VERSION ""

NS_ :

BS_:

BU_:

BO_ 2566856960 ECU_EDC2BC: 8 Vector__XXX
 SG_ FF21_ForcedRegenerationStatus : 28|2@1+ (1,0) [0|3] "" Vector__XXX
 SG_ FF21_DPFSootLevel : 56|8@1+ (1,0) [0|255] "" Vector__XXX
 SG_ FF21_EBCoperationalStatus : 52|4@1+ (1,0) [0|15] "" Vector__XXX
 SG_ FF21_EngineDegradationLevel : 48|4@1+ (1,0) [0|15] "" Vector__XXX
 SG_ FF21_EngineOilTempHigh : 46|2@1+ (1,0) [0|3] "" Vector__XXX
 SG_ FF21_FuelFilterHeaterStatus : 44|2@1+ (1,0) [0|3] "" Vector__XXX
 SG_ FF21_WaterInFuelDetection : 42|2@1+ (1,0) [0|3] "" Vector__XXX
 SG_ FF21_EngineOilPressureLow : 40|2@1+ (1,0) [0|3] "" Vector__XXX
 SG_ FF21_StopButtonSatus : 35|2@1+ (1,0) [0|3] "" Vector__XXX
 SG_ FF21_RegenerationLampStatus : 32|3@1+ (1,0) [0|7] "" Vector__XXX
 SG_ FF21_HydrauPumpActiveRequest : 26|2@1+ (1,0) [0|3] "" Vector__XXX
 SG_ FF21_MILStatus : 24|2@1+ (1,0) [0|3] "" Vector__XXX
 SG_ FF21_EngineOverSpeed : 10|2@1+ (1,0) [0|3] "" Vector__XXX
 SG_ FF21_VehicleSpeedLimitLampStatus : 8|2@1+ (1,0) [0|3] "" Vector__XXX
 SG_ FF21_DiagnosticLampStatus : 6|2@1+ (1,0) [0|3] "" Vector__XXX
 SG_ FF21_FuelBlockStatusByTheI : 4|2@1+ (1,0) [0|3] "" Vector__XXX
 SG_ FF21_ColdStartHeaterStatus : 0|4@1+ (1,0) [0|15] "" Vector__XXX

BO_ 2566763581 ECU_AT1IG2_SA3D: 8 Vector__XXX
 SG_ Aftrtrtmnt1ExhaustTemperature1 : 0|16@1+ (0.03125,-273) [-273|1734.96875] "deg C" Vector__XXX
 SG_ Aftrtrtmnt1DslPFIntkTemperature : 16|16@1+ (0.03125,-273) [-273|1734.96875] "deg C" Vector__XXX
 SG_ Aftrtrtmnt1ExhstTemp1PrelimFMI : 32|5@1+ (1,0) [0|31] "" Vector__XXX
 SG_ Aft1DslPFIntkTempPrelimFMI : 40|5@1+ (1,0) [0|31] "" Vector__XXX

BO_ 2566719744 ECU_HRLFC: 8 Vector__XXX
 SG_ EngineTripFuel : 0|32@1+ (0.001,0) [0|4211081.215] "l" Vector__XXX
 SG_ EngineTotalFuelUsed : 32|32@1+ (0.001,0) [0|4211081.215] "l" Vector__XXX

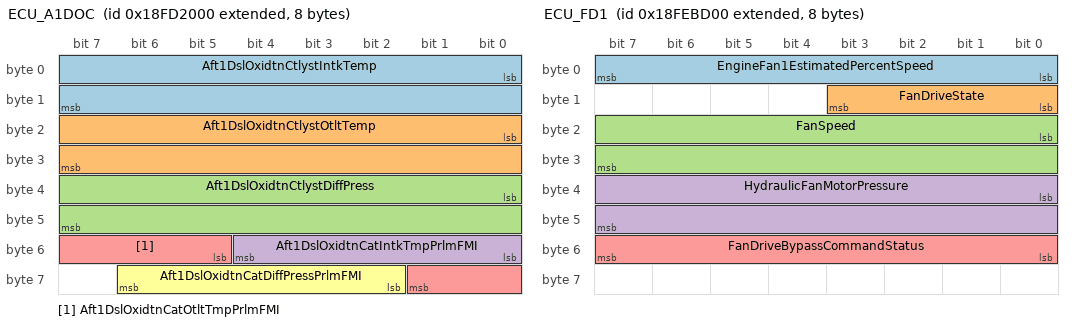
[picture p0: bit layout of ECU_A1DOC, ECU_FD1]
BO_ 2566725632 ECU_A1DOC: 8 Vector__XXX
 SG_ Aft1DslOxidtnCtlystIntkTemp : 0|16@1+ (0.03125,-273) [-273|1734.96875] "deg C" Vector__XXX
 SG_ Aft1DslOxidtnCtlystOtltTemp : 16|16@1+ (0.03125,-273) [-273|1734.96875] "deg C" Vector__XXX
 SG_ Aft1DslOxidtnCtlystDiffPress : 32|16@1+ (0.1,0) [0|6425.5] "kPa" Vector__XXX
 SG_ Aft1DslOxidtnCatIntkTmpPrlmFMI : 48|5@1+ (1,0) [0|31] "" Vector__XXX
 SG_ Aft1DslOxidtnCatOtltTmpPrlmFMI : 53|5@1+ (1,0) [0|31] "" Vector__XXX
 SG_ Aft1DslOxidtnCatDiffPressPrlmFMI : 58|5@1+ (1,0) [0|31] "" Vector__XXX

BO_ 2566749184 ECU_DPFC1: 8 Vector__XXX
 SG_ DieselParticulateFilterLampCmd : 0|3@1+ (1,0) [0|7] "" Vector__XXX
 SG_ AftrtrtmntDslPFPassiveRegenStat : 8|2@1+ (1,0) [0|3] "" Vector__XXX
 SG_ AftrtrtmntDslPFActvRegenStatus : 10|2@1+ (1,0) [0|3] "" Vector__XXX
 SG_ AftrtrtmntDslPFStatus : 12|3@1+ (1,0) [0|7] "" Vector__XXX
 SG_ DslPFActvRegenInhbtdStatus : 16|2@1+ (1,0) [0|3] "" Vector__XXX
 SG_ DslPFActvRegenInhbtdDTInhbtSw : 18|2@1+ (1,0) [0|3] "" Vector__XXX
 SG_ DslPFActRegenInhbtdDTCltchDiseng : 20|2@1+ (1,0) [0|3] "" Vector__XXX
 SG_ DslPFActRegenInhbtdDTSrvcBrkActv : 22|2@1+ (1,0) [0|3] "" Vector__XXX
 SG_ DslPFActvRegenInhbtdDTPTOActv : 24|2@1+ (1,0) [0|3] "" Vector__XXX
 SG_ DPFActRegenInhbtdDTAcclPdlOffIdl : 26|2@1+ (1,0) [0|3] "" Vector__XXX
 SG_ DslPFActvRegenInhbtdDTOutOfNtrl : 28|2@1+ (1,0) [0|3] "" Vector__XXX
 SG_ DPFActRegInhDTVhclSpdAbvAllwdSpd : 30|2@1+ (1,0) [0|3] "" Vector__XXX
 SG_ DPFActRegenInhbtdDTPrkBrkNotSet : 32|2@1+ (1,0) [0|3] "" Vector__XXX
 SG_ DPFActRegenInhbtdDTLowExhstTemp : 34|2@1+ (1,0) [0|3] "" Vector__XXX
 SG_ DslPFActRegenInhbtdDTSysFaultAct : 36|2@1+ (1,0) [0|3] "" Vector__XXX
 SG_ DslPFActvRegenInhbtdDTSysTimeout : 38|2@1+ (1,0) [0|3] "" Vector__XXX
 SG_ DPFActRegenInhbtdDTTmprySysLckt : 40|2@1+ (1,0) [0|3] "" Vector__XXX
 SG_ DPFActRegenInhbtdDTPrmntSysLckt : 42|2@1+ (1,0) [0|3] "" Vector__XXX
 SG_ DPFActRegInhbtdDTEngNotWarmedUp : 44|2@1+ (1,0) [0|3] "" Vector__XXX
 SG_ DPFActRegInhDTVhclSpdBlwAllwdSpd : 46|2@1+ (1,0) [0|3] "" Vector__XXX
 SG_ DslPFAutoActvRegenInitConf : 48|2@1+ (1,0) [0|3] "" Vector__XXX
 SG_ ExhstSystemHghTemperatureLampCmd : 50|3@1+ (1,0) [0|7] "" Vector__XXX
 SG_ DslPFActvRegenForcedStatus : 53|3@1+ (1,0) [0|7] "" Vector__XXX
 SG_ HydrocarbonDoserPurgingEnable : 56|2@1+ (1,0) [0|3] "" Vector__XXX
 SG_ DPFActRegenInhbtdDTLowExhstPress : 58|2@1+ (1,0) [0|3] "" Vector__XXX
 SG_ Aft1DPFConditionsNotMetForActReg : 60|2@1+ (1,0) [0|3] "" Vector__XXX

BO_ 2566831360 ECU_FD1: 8 Vector__XXX
 SG_ EngineFan1EstimatedPercentSpeed : 0|8@1+ (0.4,0) [0|100] "%" Vector__XXX
 SG_ FanDriveState : 8|4@1+ (1,0) [0|15] "" Vector__XXX
 SG_ FanSpeed : 16|16@1+ (0.125,0) [0|8031.875] "rpm" Vector__XXX
 SG_ HydraulicFanMotorPressure : 32|16@1+ (0.5,0) [0|32127.5] "kPa" Vector__XXX
 SG_ FanDriveBypassCommandStatus : 48|8@1+ (0.4,0) [0|100] "%" Vector__XXX

BO_ 2566845696 ECU_AMB: 8 Vector__XXX
 SG_ BarometricPressure : 0|8@1+ (0.5,0) [0|125] "kPa" Vector__XXX
 SG_ CabInteriorTemperature : 8|16@1+ (0.03125,-273) [-273|1734.96875] "deg C" Vector__XXX
 SG_ AmbientAirTemperature : 24|16@1+ (0.03125,-273) [-273|1734.96875] "deg C" Vector__XXX
 SG_ EngineIntakeAirTemperature : 40|8@1+ (1,-40) [-40|210] "deg C" Vector__XXX
 SG_ RoadSurfaceTemperature : 48|16@1+ (0.03125,-273) [-273|1734.96875] "deg C" Vector__XXX

BO_ 2566846208 ECU_VEP1: 8 Vector__XXX
 SG_ NetBatteryCurrent : 0|8@1+ (1,-125) [-125|125] "A" Vector__XXX
 SG_ AlternatorCurrent : 8|8@1+ (1,0) [0|250] "A" Vector__XXX
 SG_ ChargingSystemPotential : 16|16@1+ (0.05,0) [0|3212.75] "V" Vector__XXX
 SG_ BatteryPotentialPowerInput1 : 32|16@1+ (0.05,0) [0|3212.75] "V" Vector__XXX
 SG_ KeyswitchBatteryPotential : 48|16@1+ (0.05,0) [0|3212.75] "V" Vector__XXX

BO_ 2566875929 AIRCON_ACRM: 8 Vector__XXX
 SG_ FF6B_VCU_Compressure_State : 22|2@1+ (1,0) [0|3] "" Vector__XXX
 SG_ FF6B_ACP_PS : 56|8@1+ (16,0) [0|4000] "kPa" Vector__XXX
 SG_ FF6B_CurrentAmbientTemperature_ : 48|8@1+ (1,0) [0|255] "" Vector__XXX
 SG_ FF6B_TemperatureState : 44|4@1+ (1,0) [0|15] "" Vector__XXX
 SG_ FF6B_WindDirectRearIndicState : 10|2@1+ (1,0) [0|3] "" Vector__XXX
 SG_ FF6B_WindDirectFrontIndicState : 8|2@1+ (1,0) [0|3] "" Vector__XXX
 SG_ FF6B_WindDirectFloorIndicState : 12|2@1+ (1,0) [0|3] "" Vector__XXX
 SG_ FF6B_WindDirectDEFIndicState : 14|2@1+ (1,0) [0|3] "" Vector__XXX
 SG_ FF6B_TempSettingValueOverState : 18|2@1+ (1,0) [0|3] "" Vector__XXX
 SG_ FF6B_TempSettingValueBelowState : 20|2@1+ (1,0) [0|3] "" Vector__XXX
 SG_ FF6B_OuttakeIntakeModeSelect : 4|2@1+ (1,0) [0|3] "" Vector__XXX
 SG_ FF6B_ManualAutoModeState : 0|2@1+ (1,0) [0|3] "" Vector__XXX
 SG_ FF6B_HVACPowerState : 16|2@1+ (1,0) [0|3] "" Vector__XXX
 SG_ FF6B_DEFModeState : 6|2@1+ (1,0) [0|3] "" Vector__XXX
 SG_ FF6B_CurrentTemperatureSetting : 24|5@1+ (1,0) [0|31] "" Vector__XXX
 SG_ FF6B_CurrentBlowerSpeed : 40|4@1+ (1,0) [0|15] "" Vector__XXX
 SG_ FF6B_CurrentAmbientTemperature : 32|8@1+ (1,0) [0|255] "" Vector__XXX
 SG_ FF6B_ACModeState : 2|2@1+ (1,0) [0|3] "" Vector__XXX

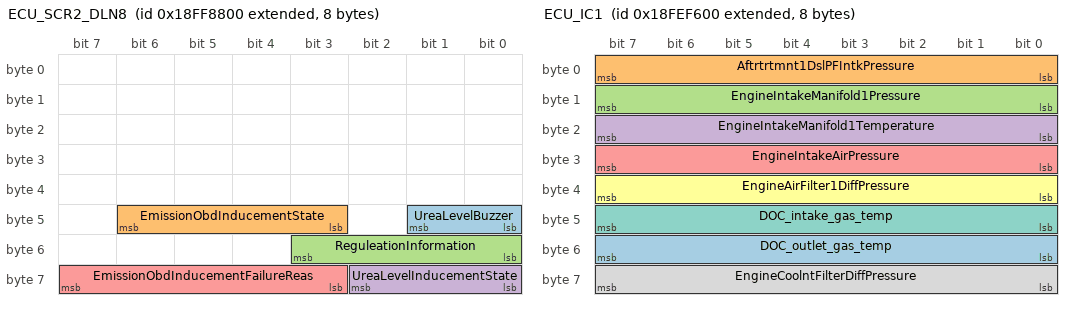
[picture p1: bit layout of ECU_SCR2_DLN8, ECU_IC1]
BO_ 2566883328 ECU_SCR2_DLN8: 8 Vector__XXX
 SG_ UreaLevelBuzzer : 40|2@1+ (1,0) [0|3] "bit" Vector__XXX
 SG_ EmissionObdInducementState : 43|4@1+ (1,0) [0|15] "bit" Vector__XXX
 SG_ ReguleationInformation : 48|4@1+ (1,0) [0|15] "bit" Vector__XXX
 SG_ UreaLevelInducementState : 56|3@1+ (1,0) [0|7] "bit" Vector__XXX
 SG_ EmissionObdInducementFailureReas : 59|5@1+ (1,0) [0|31] "bit" Vector__XXX

BO_ 2566845952 ECU_IC1: 8 Vector__XXX
 SG_ DOC_outlet_gas_temp : 48|8@1+ (0.03125,-273) [-273|-265.03125] "deg C" Vector__XXX
 SG_ Aftrtrtmnt1DslPFIntkPressure : 0|8@1+ (0.5,0) [0|125] "kPa" Vector__XXX
 SG_ EngineIntakeManifold1Pressure : 8|8@1+ (2,0) [0|500] "kPa" Vector__XXX
 SG_ EngineIntakeManifold1Temperature : 16|8@1+ (1,-40) [-40|210] "deg C" Vector__XXX
 SG_ EngineIntakeAirPressure : 24|8@1+ (2,0) [0|500] "kPa" Vector__XXX
 SG_ EngineAirFilter1DiffPressure : 32|8@1+ (0.05,0) [0|12.5] "kPa" Vector__XXX
 SG_ DOC_intake_gas_temp : 40|8@1+ (0.03125,-273) [-273|-265.03125] "deg C" Vector__XXX
 SG_ EngineCoolntFilterDiffPressure : 56|8@1+ (0.5,0) [0|125] "kPa" Vector__XXX

BO_ 2348875776 ECU_TC1: 8 Vector__XXX
 SG_ TransmissionGearShiftInhbtRq : 0|2@1+ (1,0) [0|3] "" Vector__XXX
 SG_ TrnsmTrqCnvLockupDisableRq : 2|2@1+ (1,0) [0|3] "" Vector__XXX
 SG_ DisengageDrivelineRequest : 4|2@1+ (1,0) [0|3] "" Vector__XXX
 SG_ TrnsmReverseGearShftInhbtRq : 6|2@1+ (1,0) [0|3] "" Vector__XXX
 SG_ RequestedPercentClutchSlip : 8|8@1+ (0.4,0) [0|100] "%" Vector__XXX
 SG_ TransmissionRequestedGear : 16|8@1+ (1,-125) [-125|125] "" Vector__XXX
 SG_ DisengiffLockRequestFrontAxl1 : 24|2@1+ (1,0) [0|3] "" Vector__XXX
 SG_ DisengiffLockRequestFrontAxl2 : 26|2@1+ (1,0) [0|3] "" Vector__XXX
 SG_ DisengageDiffLockRequestRearAxl1 : 28|2@1+ (1,0) [0|3] "" Vector__XXX
 SG_ DisengageDiffLockRequestRearAxl2 : 30|2@1+ (1,0) [0|3] "" Vector__XXX
 SG_ DisengageDiffLockRequestCentral : 32|2@1+ (1,0) [0|3] "" Vector__XXX
 SG_ DisengiffLockRequestCentralFront : 34|2@1+ (1,0) [0|3] "" Vector__XXX
 SG_ DisengiffLockRequestCentralRear : 36|2@1+ (1,0) [0|3] "" Vector__XXX
 SG_ TransmissionLoadRedInhbtRequest : 38|2@1+ (1,0) [0|3] "" Vector__XXX
 SG_ TransmissionMode1 : 40|2@1+ (1,0) [0|3] "" Vector__XXX
 SG_ TransmissionMode2 : 42|2@1+ (1,0) [0|3] "" Vector__XXX
 SG_ TransmissionMode3 : 44|2@1+ (1,0) [0|3] "" Vector__XXX
 SG_ TransmissionMode4 : 46|2@1+ (1,0) [0|3] "" Vector__XXX
 SG_ TransmissionRequestedLaunchGear : 50|4@1+ (1,0) [0|15] "" Vector__XXX
 SG_ TrnsmShftSlctorDisplayMdeSw : 54|2@1+ (1,0) [0|3] "" Vector__XXX
 SG_ TransmissionMode5 : 56|2@1+ (1,0) [0|3] "" Vector__XXX
 SG_ TransmissionMode6 : 58|2@1+ (1,0) [0|3] "" Vector__XXX
 SG_ TransmissionMode7 : 60|2@1+ (1,0) [0|3] "" Vector__XXX
 SG_ TransmissionMode8 : 62|2@1+ (1,0) [0|3] "" Vector__XXX

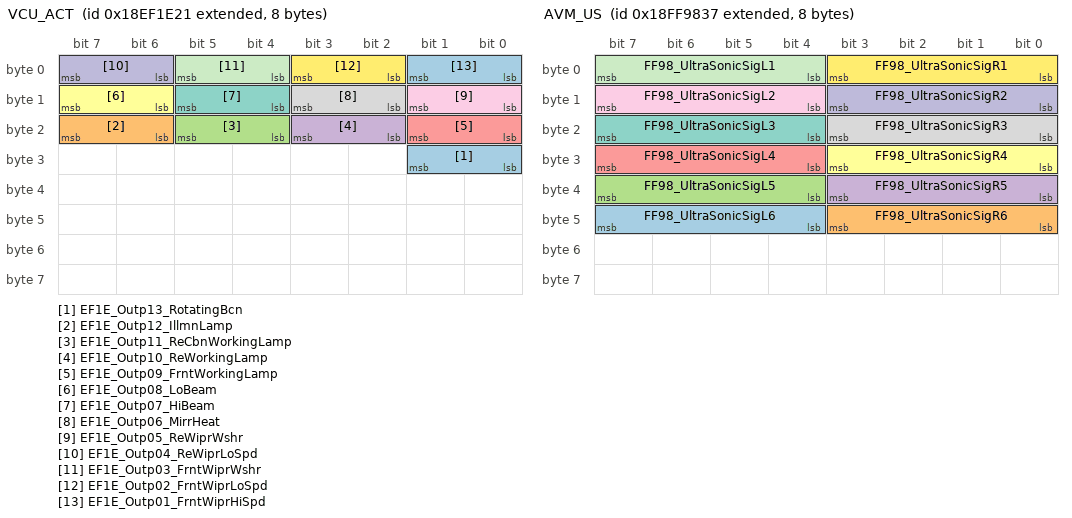
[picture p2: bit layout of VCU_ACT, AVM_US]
BO_ 2565807649 VCU_ACT: 8 Vector__XXX
 SG_ EF1E_Outp13_RotatingBcn : 24|2@1+ (1,0) [0|3] "" Vector__XXX
 SG_ EF1E_Outp12_IllmnLamp : 22|2@1+ (1,0) [0|3] "" Vector__XXX
 SG_ EF1E_Outp11_ReCbnWorkingLamp : 20|2@1+ (1,0) [0|3] "" Vector__XXX
 SG_ EF1E_Outp10_ReWorkingLamp : 18|2@1+ (1,0) [0|3] "" Vector__XXX
 SG_ EF1E_Outp09_FrntWorkingLamp : 16|2@1+ (1,0) [0|3] "" Vector__XXX
 SG_ EF1E_Outp08_LoBeam : 14|2@1+ (1,0) [0|3] "" Vector__XXX
 SG_ EF1E_Outp07_HiBeam : 12|2@1+ (1,0) [0|3] "" Vector__XXX
 SG_ EF1E_Outp06_MirrHeat : 10|2@1+ (1,0) [0|3] "" Vector__XXX
 SG_ EF1E_Outp05_ReWiprWshr : 8|2@1+ (1,0) [0|3] "" Vector__XXX
 SG_ EF1E_Outp04_ReWiprLoSpd : 6|2@1+ (1,0) [0|3] "" Vector__XXX
 SG_ EF1E_Outp03_FrntWiprWshr : 4|2@1+ (1,0) [0|3] "" Vector__XXX
 SG_ EF1E_Outp02_FrntWiprLoSpd : 2|2@1+ (1,0) [0|3] "" Vector__XXX
 SG_ EF1E_Outp01_FrntWiprHiSpd : 0|2@1+ (1,0) [0|3] "" Vector__XXX

BO_ 2566887479 AVM_US: 8 Vector__XXX
 SG_ FF98_UltraSonicSigL6 : 44|4@1+ (1,0) [0|15] "" Vector__XXX
 SG_ FF98_UltraSonicSigR6 : 40|4@1+ (1,0) [0|15] "" Vector__XXX
 SG_ FF98_UltraSonicSigL5 : 36|4@1+ (1,0) [0|15] "" Vector__XXX
 SG_ FF98_UltraSonicSigR5 : 32|4@1+ (1,0) [0|15] "" Vector__XXX
 SG_ FF98_UltraSonicSigL4 : 28|4@1+ (1,0) [0|15] "" Vector__XXX
 SG_ FF98_UltraSonicSigR4 : 24|4@1+ (1,0) [0|15] "" Vector__XXX
 SG_ FF98_UltraSonicSigL3 : 20|4@1+ (1,0) [0|15] "" Vector__XXX
 SG_ FF98_UltraSonicSigR3 : 16|4@1+ (1,0) [0|15] "" Vector__XXX
 SG_ FF98_UltraSonicSigL2 : 12|4@1+ (1,0) [0|15] "" Vector__XXX
 SG_ FF98_UltraSonicSigR2 : 8|4@1+ (1,0) [0|15] "" Vector__XXX
 SG_ FF98_UltraSonicSigL1 : 4|4@1+ (1,0) [0|15] "" Vector__XXX
 SG_ FF98_UltraSonicSigR1 : 0|4@1+ (1,0) [0|15] "" Vector__XXX

BO_ 2566899200 ECU_VGTPosCmd: 8 Vector__XXX
 SG_ FFC6_VGTCommandState : 16|8@1+ (1,0) [0|255] "" Vector__XXX
 SG_ FFC6_VGTnozzle_MSB : 8|8@1+ (1,0) [0|255] "" Vector__XXX
 SG_ FFC6_nozzle_LSB : 0|8@1+ (1,0) [0|255] "" Vector__XXX

BO_ 2566861056 ECU_TFI4CMD: 8 Vector__XXX
 SG_ FF31_Filtertime : 8|8@1+ (1,0) [0|255] "" Vector__XXX
 SG_ FF31_Command : 0|8@1+ (1,0) [0|255] "" Vector__XXX

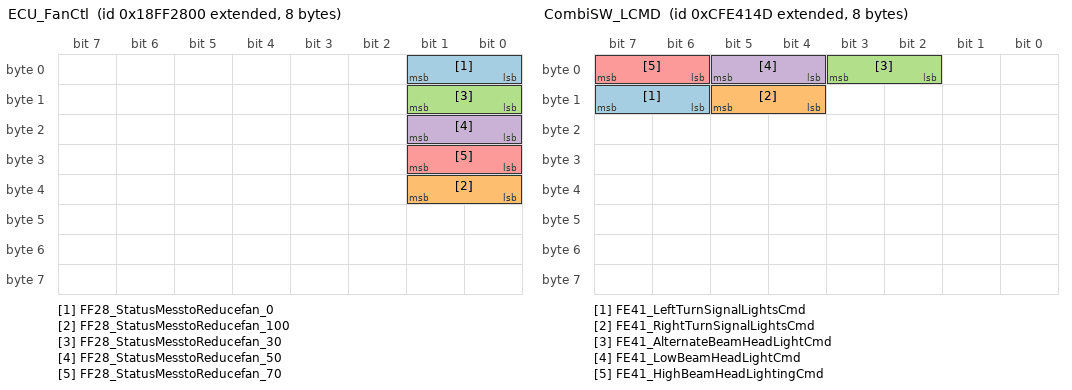
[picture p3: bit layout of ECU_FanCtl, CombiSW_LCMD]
BO_ 2566858752 ECU_FanCtl: 8 Vector__XXX
 SG_ FF28_StatusMesstoReducefan_0 : 0|2@1+ (1,0) [0|3] "" Vector__XXX
 SG_ FF28_StatusMesstoReducefan_100 : 32|2@1+ (1,0) [0|3] "" Vector__XXX
 SG_ FF28_StatusMesstoReducefan_30 : 8|2@1+ (1,0) [0|3] "" Vector__XXX
 SG_ FF28_StatusMesstoReducefan_50 : 16|2@1+ (1,0) [0|3] "" Vector__XXX
 SG_ FF28_StatusMesstoReducefan_70 : 24|2@1+ (1,0) [0|3] "" Vector__XXX

BO_ 2566769997 CombiSW_OWW: 8 Vector__XXX
 SG_ FDCD_WasherSwitch : 45|3@1+ (1,0) [0|7] "" Vector__XXX
 SG_ FDCD_WiperDelayControl : 16|8@1+ (1,0) [0|255] "" Vector__XXX
 SG_ FDCD_WiperSwitch : 4|4@1+ (1,0) [0|15] "" Vector__XXX

BO_ 2365473101 CombiSW_LCMD: 8 Vector__XXX
 SG_ FE41_LeftTurnSignalLightsCmd : 14|2@1+ (1,0) [0|3] "" Vector__XXX
 SG_ FE41_RightTurnSignalLightsCmd : 12|2@1+ (1,0) [0|3] "" Vector__XXX
 SG_ FE41_AlternateBeamHeadLightCmd : 2|2@1+ (1,0) [0|3] "" Vector__XXX
 SG_ FE41_LowBeamHeadLightCmd : 4|2@1+ (1,0) [0|3] "" Vector__XXX
 SG_ FE41_HighBeamHeadLightingCmd : 6|2@1+ (1,0) [0|3] "" Vector__XXX

BO_ 2566904865 VCU_CETI: 10 Vector__XXX
 SG_ FFDC_MissionType : 68|4@1+ (1,0) [0|15] "" Vector__XXX
 SG_ FFDC_JoystickType : 64|4@1+ (1,0) [0|15] "" Vector__XXX
 SG_ FFDC_MCVControlType : 60|4@1+ (1,0) [0|15] "" Vector__XXX
 SG_ FFDC_MCVType : 56|4@1+ (1,0) [0|15] "" Vector__XXX
 SG_ FFDC_PumpControlType : 52|4@1+ (1,0) [0|15] "" Vector__XXX
 SG_ FFDC_PumpType : 48|4@1+ (1,0) [0|15] "" Vector__XXX
 SG_ FFDC_ECUMaker : 44|4@1+ (1,0) [0|15] "" Vector__XXX
 SG_ FFDC_SalesRegion : 72|8@1+ (1,0) [0|255] "" Vector__XXX
 SG_ FFDC_EngineMaker : 40|4@1+ (1,0) [0|15] "" Vector__XXX
 SG_ FFDC_ModelYearVersion : 36|4@1+ (1,0) [0|15] "" Vector__XXX
 SG_ FFDC_MachineType : 32|4@1+ (1,0) [0|15] "" Vector__XXX
 SG_ FFDC_MachineClassification : 16|16@1+ (0.1,0) [0|6502.3] "" Vector__XXX
 SG_ FFDC_MachineGeneration : 8|8@1+ (1,0) [0|255] "" Vector__XXX
 SG_ FFDC_EmissionControl : 0|8@1+ (1,0) [0|255] "" Vector__XXX

BO_ 2566906145 VCU_FLI: 70 Vector__XXX
 SG_ FFE1_FailureLog8_FMI : 411|5@1+ (1,0) [0|31] "" Vector__XXX
 SG_ FFE1_FailureLog9_FMI : 467|5@1+ (1,0) [0|31] "" Vector__XXX
 SG_ FFE1_FailureLog7_FMI : 355|5@1+ (1,0) [0|31] "" Vector__XXX
 SG_ FFE1_FailureLog6_FMI : 299|5@1+ (1,0) [0|31] "" Vector__XXX
 SG_ FFE1_FailureLog5_FMI : 243|5@1+ (1,0) [0|31] "" Vector__XXX
 SG_ FFE1_FailureLog4_FMI : 187|5@1+ (1,0) [0|31] "" Vector__XXX
 SG_ FFE1_FailureLog3_FMI : 131|5@1+ (1,0) [0|31] "" Vector__XXX
 SG_ FFE1_FailureLog2_FMI : 75|5@1+ (1,0) [0|31] "" Vector__XXX
 SG_ FFE1_FailureLog10_Code : 512|11@1+ (1,0) [0|2047] "" Vector__XXX
 SG_ FFE1_FailureLog9_Code : 456|11@1+ (1,0) [0|2047] "" Vector__XXX
 SG_ FFE1_FailureLog8_Code : 400|11@1+ (1,0) [0|2047] "" Vector__XXX
 SG_ FFE1_FailureLog7_Code : 344|11@1+ (1,0) [0|2047] "" Vector__XXX
 SG_ FFE1_FailureLog6_Code : 288|11@1+ (1,0) [0|2047] "" Vector__XXX
 SG_ FFE1_FailureLog5_Code : 232|11@1+ (1,0) [0|2047] "" Vector__XXX
 SG_ FFE1_FailureLog4_Code : 176|11@1+ (1,0) [0|2047] "" Vector__XXX
 SG_ FFE1_FailureLog3_Code : 120|11@1+ (1,0) [0|2047] "" Vector__XXX
 SG_ FFE1_FailureLog1_FMI : 19|5@1+ (1,0) [0|31] "" Vector__XXX
 SG_ FFE1_FailureLogN_Count : 112|8@1+ (1,0) [0|255] "" Vector__XXX
 SG_ FFE1_FailureLog2_FirstOccurTime : 80|32@1+ (1,0) [0|4294967295] "" Vector__XXX
 SG_ FFE1_FailureLog2_Count : 56|8@1+ (1,0) [0|255] "" Vector__XXX
 SG_ FFE1_FailureLog2_Code : 64|11@1+ (1,0) [0|2047] "" Vector__XXX
 SG_ FFE1_FailureLog1_FirstOccurTime : 24|32@1+ (1,0) [0|4294967295] "" Vector__XXX
 SG_ FFE1_FailureLog1_Count : 0|8@1+ (1,0) [0|255] "" Vector__XXX
 SG_ FFE1_FailureLog1_Code : 8|11@1+ (1,0) [0|2047] "" Vector__XXX

BO_ 2566906657 VCU_TPUC: 8 Vector__XXX
 SG_ FFE3_TMSPermanent : 0|32@1+ (1,0) [0|4294967295] "" Vector__XXX

BO_ 2566902561 VCU_FOCPHI: 60 Vector__XXX
 SG_ FFD3_PumpDriveOil : 384|16@1+ (1,0) [0|65535] "" Vector__XXX
 SG_ FFD3_PumpDriveAirCartridge : 400|16@1+ (1,0) [0|65535] "" Vector__XXX
 SG_ FFD3_HSTFilter : 368|16@1+ (1,0) [0|65535] "h" Vector__XXX
 SG_ FFD3_AxleOilFilter : 352|16@1+ (1,0) [0|65535] "h" Vector__XXX
 SG_ FFD3_ATS_SparkPlug : 336|16@1+ (1,0) [0|65535] "h" Vector__XXX
 SG_ FFD3_EngCrankcaseBreather : 320|16@1+ (1,0) [0|65535] "h" Vector__XXX
 SG_ FFD3_AirConditionerFilter_Inner : 304|16@1+ (1,0) [0|65535] "h" Vector__XXX
 SG_ FFD3_AirConditionerFilter_Outer : 288|16@1+ (1,0) [0|65535] "h" Vector__XXX
 SG_ FFD3_EngineOilCentCleanerFilter : 272|16@1+ (1,0) [0|65535] "h" Vector__XXX
 SG_ FFD3_DEF_AdBlueBreatherFilter : 256|16@1+ (1,0) [0|65535] "h" Vector__XXX
 SG_ FFD3_DEF_AdBlueFilter : 240|16@1+ (1,0) [0|65535] "h" Vector__XXX
 SG_ FFD3_OilBathPrecleaner : 224|16@1+ (1,0) [0|65535] "h" Vector__XXX
 SG_ FFD3_TransmissionOilFilter : 176|16@1+ (1,0) [0|65535] "h" Vector__XXX
 SG_ FFD3_TransmissionOil : 160|16@1+ (1,0) [0|65535] "h" Vector__XXX
 SG_ FFD3_ReturnFilter : 48|16@1+ (1,0) [0|65535] "h" Vector__XXX
 SG_ FFD3_PilotFilter : 64|16@1+ (1,0) [0|65535] "h" Vector__XXX
 SG_ FFD3_HydOil : 96|16@1+ (1,0) [0|65535] "h" Vector__XXX
 SG_ FFD3_FuelFilter : 0|16@1+ (1,0) [0|65535] "h" Vector__XXX
 SG_ FFD3_EnginOilFilter : 32|16@1+ (1,0) [0|65535] "h" Vector__XXX
 SG_ FFD3_EngineOil : 80|16@1+ (1,0) [0|65535] "h" Vector__XXX
 SG_ FFD3_DPFFilter : 128|16@1+ (1,0) [0|65535] "h" Vector__XXX
 SG_ FFD3_DEF : 208|16@1+ (1,0) [0|65535] "h" Vector__XXX
 SG_ FFD3_CoolantWater : 112|16@1+ (1,0) [0|65535] "h" Vector__XXX
 SG_ FFD3_BreatherOilSeparatorFilter : 144|16@1+ (1,0) [0|65535] "h" Vector__XXX
 SG_ FFD3_AxleOil : 192|16@1+ (1,0) [0|65535] "h" Vector__XXX
 SG_ FFD3_AirCleaner : 16|16@1+ (1,0) [0|65535] "h" Vector__XXX

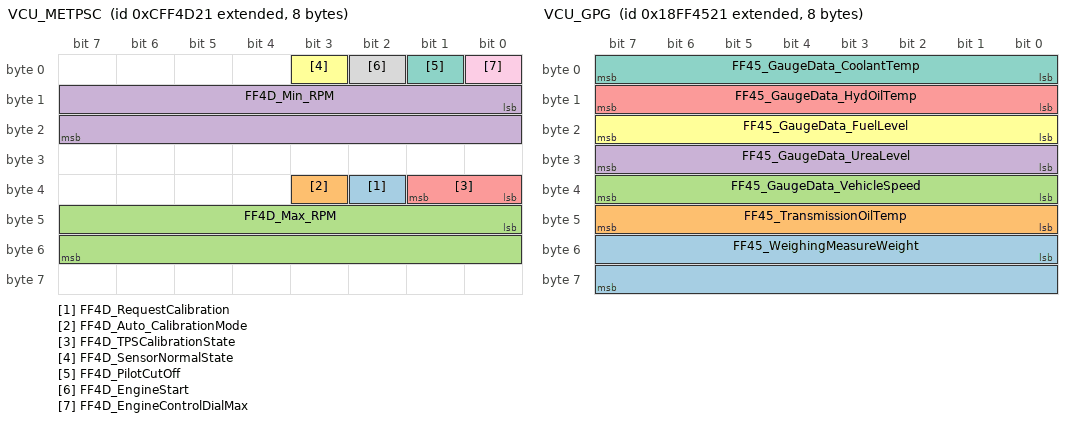
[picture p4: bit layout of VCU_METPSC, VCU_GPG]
BO_ 2365541665 VCU_METPSC: 8 Vector__XXX
 SG_ FF4D_RequestCalibration : 34|1@1+ (1,0) [0|1] "" Vector__XXX
 SG_ FF4D_Auto_CalibrationMode : 35|1@1+ (1,0) [0|1] "" Vector__XXX
 SG_ FF4D_Max_RPM : 40|16@1+ (0.125,0) [0|8031.875] "rpm" Vector__XXX
 SG_ FF4D_Min_RPM : 8|16@1+ (0.125,0) [0|8031.875] "rpm" Vector__XXX
 SG_ FF4D_TPSCalibrationState : 32|2@1+ (1,0) [0|3] "" Vector__XXX
 SG_ FF4D_SensorNormalState : 3|1@1+ (1,0) [0|1] "" Vector__XXX
 SG_ FF4D_PilotCutOff : 1|1@1+ (1,0) [0|1] "" Vector__XXX
 SG_ FF4D_EngineStart : 2|1@1+ (1,0) [0|1] "" Vector__XXX
 SG_ FF4D_EngineControlDialMax : 0|1@1+ (1,0) [0|1] "" Vector__XXX

BO_ 2566866209 VCU_GPG: 8 Vector__XXX
 SG_ FF45_WeighingMeasureWeight : 48|16@1+ (1,-32127) [-32127|32127] "Kg" Vector__XXX
 SG_ FF45_TransmissionOilTemp : 40|8@1+ (1,0) [0|255] "" Vector__XXX
 SG_ FF45_GaugeData_VehicleSpeed : 32|8@1+ (1,0) [0|255] "km/h" Vector__XXX
 SG_ FF45_GaugeData_UreaLevel : 24|8@1+ (1,0) [0|255] "%" Vector__XXX
 SG_ FF45_GaugeData_HydOilTemp : 8|8@1+ (1,0) [0|255] "%" Vector__XXX
 SG_ FF45_GaugeData_FuelLevel : 16|8@1+ (1,0) [0|255] "%" Vector__XXX
 SG_ FF45_GaugeData_CoolantTemp : 0|8@1+ (1,0) [0|255] "%" Vector__XXX

BO_ 2566905633 VCU_UHDI: 96 Vector__XXX
 SG_ FFDF_TravelPower : 192|32@1+ (1,0) [0|4294967295] "min" Vector__XXX
 SG_ FFDF_TwoWayMode : 320|32@1+ (1,0) [0|4294967295] "min" Vector__XXX
 SG_ FFDF_TravelStandard : 224|32@1+ (1,0) [0|4294967295] "min" Vector__XXX
 SG_ FFDF_TotalOperationHour : 736|32@1+ (1,0) [0|4294967295] "min" Vector__XXX
 SG_ FFDF_StandardMode : 64|32@1+ (1,0) [0|4294967295] "min" Vector__XXX
 SG_ FFDF_PowerPlusMode : 0|32@1+ (1,0) [0|4294967295] "min" Vector__XXX
 SG_ FFDF_PowerMode : 32|32@1+ (1,0) [0|4294967295] "min" Vector__XXX
 SG_ FFDF_LiftMode : 256|32@1+ (1,0) [0|4294967295] "min" Vector__XXX
 SG_ FFDF_Idle : 160|32@1+ (1,0) [0|4294967295] "min" Vector__XXX
 SG_ FFDF_HydOilTemp_Below30 : 352|32@1+ (1,0) [0|4294967295] "min" Vector__XXX
 SG_ FFDF_HydOilTemp_Above96 : 512|32@1+ (1,0) [0|4294967295] "min" Vector__XXX
 SG_ FFDF_HydOilTemp_86to95 : 480|32@1+ (1,0) [0|4294967295] "min" Vector__XXX
 SG_ FFDF_HydOilTemp_76to85 : 448|32@1+ (1,0) [0|4294967295] "min" Vector__XXX
 SG_ FFDF_HydOilTemp_51to75 : 416|32@1+ (1,0) [0|4294967295] "min" Vector__XXX
 SG_ FFDF_HydOilTemp_31to50 : 384|32@1+ (1,0) [0|4294967295] "min" Vector__XXX
 SG_ FFDF_EconomyMode : 96|32@1+ (1,0) [0|4294967295] "min" Vector__XXX
 SG_ FFDF_CoolantOilTemp_Below40 : 544|32@1+ (1,0) [0|4294967295] "min" Vector__XXX
 SG_ FFDF_CoolantOilTemp_Above106 : 704|32@1+ (1,0) [0|4294967295] "min" Vector__XXX
 SG_ FFDF_CoolantOilTemp_96to105 : 672|32@1+ (1,0) [0|4294967295] "min" Vector__XXX
 SG_ FFDF_CoolantOilTemp_86to95 : 640|32@1+ (1,0) [0|4294967295] "min" Vector__XXX
 SG_ FFDF_CoolantOilTemp_61to85 : 608|32@1+ (1,0) [0|4294967295] "min" Vector__XXX
 SG_ FFDF_CoolantOilTemp_41to60 : 576|32@1+ (1,0) [0|4294967295] "min" Vector__XXX
 SG_ FFDF_BreakerMode : 288|32@1+ (1,0) [0|4294967295] "min" Vector__XXX
 SG_ FFDF_AutoIdle : 128|32@1+ (1,0) [0|4294967295] "min" Vector__XXX

BO_ 2566905377 VCU_FUDI: 36 Vector__XXX
 SG_ FFDE_TravelStandard : 224|32@1+ (0.5,0) [0|2147483647.5] "L" Vector__XXX
 SG_ FFDE_TravelPower : 192|32@1+ (0.5,0) [0|2147483647.5] "L" Vector__XXX
 SG_ FFDE_StandardMode : 64|32@1+ (0.5,0) [0|2147483647.5] "L" Vector__XXX
 SG_ FFDE_PowerPlusMode : 0|32@1+ (0.5,0) [0|2147483647.5] "L" Vector__XXX
 SG_ FFDE_PowerMode : 32|32@1+ (0.5,0) [0|2147483647.5] "L" Vector__XXX
 SG_ FFDE_Idle : 160|32@1+ (0.5,0) [0|2147483647.5] "L" Vector__XXX
 SG_ FFDE_EconomyMode : 96|32@1+ (0.5,0) [0|2147483647.5] "L" Vector__XXX
 SG_ FFDE_AutoIdle : 128|32@1+ (0.5,0) [0|2147483647.5] "L" Vector__XXX

BO_ 2565668669 ECU_TPCM_SA3D: 8 Vector__XXX
 SG_ ECU_TPCM_SA3D_Mux M : 0|8@1+ (1,0) [0|0] "" Vector__XXX
 SG_ TotalMessageSize16 m16 : 8|16@1+ (1,0) [0|64255] "" Vector__XXX
 SG_ TotalNumberOfPackets16 m16 : 24|8@1+ (1,0) [0|255] "" Vector__XXX
 SG_ MaximumNumberOfPackets m16 : 32|8@1+ (1,0) [0|255] "" Vector__XXX
 SG_ PGNOfThePacketedMessage16 m16 : 40|24@1+ (1,0) [0|16777215] "" Vector__XXX
 SG_ NumberOfPacketsThatCanBeSent m17 : 8|8@1+ (1,0) [0|255] "" Vector__XXX
 SG_ NextPacketNumberToBeSent m17 : 16|8@1+ (1,0) [0|255] "" Vector__XXX
 SG_ PGNOfThePacketedMessage17 m17 : 40|24@1+ (1,0) [0|16777215] "" Vector__XXX
 SG_ TotalMessageSize19 m19 : 8|16@1+ (1,0) [0|64255] "" Vector__XXX
 SG_ TotalNumberOfPackets19 m19 : 24|8@1+ (1,0) [0|255] "" Vector__XXX
 SG_ PGNOfThePacketedMessage19 m19 : 40|24@1+ (1,0) [0|16777215] "" Vector__XXX
 SG_ TotalMessageSize32 m32 : 8|16@1+ (1,0) [0|64255] "" Vector__XXX
 SG_ TotalNumberOfPackets32 m32 : 24|8@1+ (1,0) [0|255] "" Vector__XXX
 SG_ PGNOfThePacketedMessage32 m32 : 40|24@1+ (1,0) [0|16777215] "" Vector__XXX
 SG_ ConnectionAbortReason m255 : 8|8@1+ (1,0) [0|255] "" Vector__XXX
 SG_ ParameterGrpNoOfPacketedMessage m255 : 40|24@1+ (1,0) [0|16777215] "" Vector__XXX

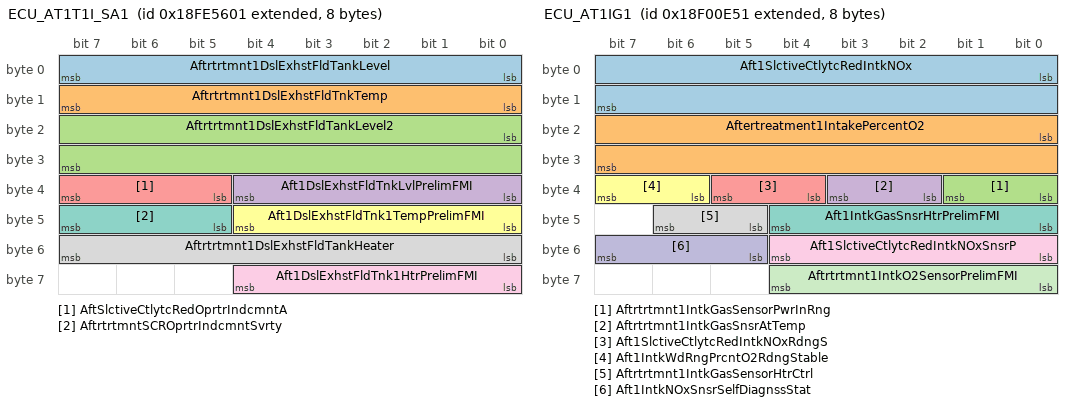
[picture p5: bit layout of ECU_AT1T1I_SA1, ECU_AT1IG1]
BO_ 2566804993 ECU_AT1T1I_SA1: 8 Vector__XXX
 SG_ Aftrtrtmnt1DslExhstFldTankLevel : 0|8@1+ (0.4,0) [0|100] "%" Vector__XXX
 SG_ Aftrtrtmnt1DslExhstFldTnkTemp : 8|8@1+ (1,-40) [-40|210] "deg C" Vector__XXX
 SG_ Aftrtrtmnt1DslExhstFldTankLevel2 : 16|16@1+ (0.1,0) [0|6425.5] "mm" Vector__XXX
 SG_ Aft1DslExhstFldTnkLvlPrelimFMI : 32|5@1+ (1,0) [0|31] "" Vector__XXX
 SG_ AftSlctiveCtlytcRedOprtrIndcmntA : 37|3@1+ (1,0) [0|7] "" Vector__XXX
 SG_ Aft1DslExhstFldTnk1TempPrelimFMI : 40|5@1+ (1,0) [0|31] "" Vector__XXX
 SG_ AftrtrtmntSCROprtrIndcmntSvrty : 45|3@1+ (1,0) [0|7] "" Vector__XXX
 SG_ Aftrtrtmnt1DslExhstFldTankHeater : 48|8@1+ (0.4,0) [0|100] "%" Vector__XXX
 SG_ Aft1DslExhstFldTnk1HtrPrelimFMI : 56|5@1+ (1,0) [0|31] "" Vector__XXX

BO_ 2566763325 ECU_AT1OG2_SA3D: 8 Vector__XXX
 SG_ Aftrtrtmnt1ExhaustTemperature3 : 0|16@1+ (0.03125,-273) [-273|1734.96875] "deg C" Vector__XXX
 SG_ Aftrtrtmnt1DslPFOtltTemperature : 16|16@1+ (0.03125,-273) [-273|1734.96875] "deg C" Vector__XXX
 SG_ Aftrtrtmnt1ExhstTemp3PrelimFMI : 32|5@1+ (1,0) [0|31] "" Vector__XXX
 SG_ Aft1DslPFOtltExhstTempPrelimFMI : 40|5@1+ (1,0) [0|31] "" Vector__XXX

BO_ 2565799680 ECU_ACM: 8 Vector__XXX
 SG_ NAMEOfControllerApplication : 0|64@1+ (1,0) [0|1.84467440737096E+019] "" Vector__XXX

BO_ 2565869137 ECU_AT1IG1: 8 Vector__XXX
 SG_ Aft1SlctiveCtlytcRedIntkNOx : 0|16@1+ (0.05,-200) [-200|3012.75] "ppm" Vector__XXX
 SG_ Aftertreatment1IntakePercentO2 : 16|16@1+ (0.000514,-12) [-12|21.02707] "%" Vector__XXX
 SG_ Aftrtrtmnt1IntkGasSensorPwrInRng : 32|2@1+ (1,0) [0|3] "" Vector__XXX
 SG_ Aftrtrtmnt1IntkGasSnsrAtTemp : 34|2@1+ (1,0) [0|3] "" Vector__XXX
 SG_ Aft1SlctiveCtlytcRedIntkNOxRdngS : 36|2@1+ (1,0) [0|3] "" Vector__XXX
 SG_ Aft1IntkWdRngPrcntO2RdngStable : 38|2@1+ (1,0) [0|3] "" Vector__XXX
 SG_ Aft1IntkGasSnsrHtrPrelimFMI : 40|5@1+ (1,0) [0|31] "" Vector__XXX
 SG_ Aftrtrtmnt1IntkGasSensorHtrCtrl : 45|2@1+ (1,0) [0|3] "" Vector__XXX
 SG_ Aft1SlctiveCtlytcRedIntkNOxSnsrP : 48|5@1+ (1,0) [0|31] "" Vector__XXX
 SG_ Aft1IntkNOxSnsrSelfDiagnssStat : 53|3@1+ (1,0) [0|7] "" Vector__XXX
 SG_ Aftrtrtmnt1IntkO2SensorPrelimFMI : 56|5@1+ (1,0) [0|31] "" Vector__XXX

BO_ 2566709248 ECU_DPFC2: 8 Vector__XXX
 SG_ Aft1DslPFIntkTemperatuRstPoint : 0|16@1+ (0.03125,-273) [-273|1734.96875] "deg C" Vector__XXX
 SG_ EngineUnburnedFuelPercentage : 16|16@1+ (0.0025,0) [0|160.6375] "%" Vector__XXX
 SG_ Aftertreatment1FuelMassRate : 32|16@1+ (0.05,0) [0|3212.75] "g/m" Vector__XXX
 SG_ Aftertreatment2FuelMassRate : 48|16@1+ (0.05,0) [0|3212.75] "g/m" Vector__XXX

BO_ 2365394514 ECU_AT1OGC2: 8 Vector__XXX
 SG_ Aft1OtltNOxSnsrO2PressCorrctn : 0|8@1+ (0.5,0) [0|125] "%/bar" Vector__XXX
 SG_ Aft1OtltNOxSnsrNOxPressCorrctn : 8|8@1+ (0.5,0) [0|125] "%/bar" Vector__XXX
 SG_ Aftrtrtmnt1OtltNOxSnsrNO2Corrctn : 16|8@1+ (0.5,0) [0|125] "%" Vector__XXX
 SG_ Aftrtrtmnt1OtltNOxSnsrNH3Corrctn : 24|8@1+ (0.5,0) [0|125] "%" Vector__XXX
 SG_ Aft1OtltNOxSnsrSelfDiagssFinalRs : 32|8@1+ (1,0) [0|250] "" Vector__XXX

BO_ 2365394770 ECU_AT1OGC1: 8 Vector__XXX
 SG_ Aftrtrtmnt1OtltNOxSensorHtrRatio : 0|16@1+ (0.001,0) [0|64.255] "" Vector__XXX
 SG_ Aft1OtltNOxSnsrNwPrtDviatNOxGain : 16|16@1+ (0.1,-100) [-100|6325.5] "%" Vector__XXX
 SG_ Aft1OtltNOxSnsrNPDviatNOxOffst : 32|8@1+ (1,-125) [-125|125] "ppm" Vector__XXX
 SG_ Aftrtrtmnt1OtltNOxSensorOpHours : 40|16@1+ (1,0) [0|64255] "hr" Vector__XXX

BO_ 2365395025 ECU_AT1IGC2: 8 Vector__XXX
 SG_ Aft1IntkNOxSnsrO2PressCorrctn : 0|8@1+ (0.5,0) [0|125] "%/bar" Vector__XXX
 SG_ Aft1IntkNOxSnsrNOxPressCorrctn : 8|8@1+ (0.5,0) [0|125] "%/bar" Vector__XXX
 SG_ Aftrtrtmnt1IntkNOxSnsrNO2Corrctn : 16|8@1+ (0.5,0) [0|125] "%" Vector__XXX
 SG_ Aftrtrtmnt1IntkNOxSnsrNH3Corrctn : 24|8@1+ (0.5,0) [0|125] "%" Vector__XXX
 SG_ Aft1IntkNOxSnsrSelfDiagssFinalRs : 32|8@1+ (1,0) [0|250] "" Vector__XXX

BO_ 2365395281 ECU_AT1IGC1: 8 Vector__XXX
 SG_ Aftrtrtmnt1IntkNOxSensorHtrRatio : 0|16@1+ (0.001,0) [0|64.255] "" Vector__XXX
 SG_ Aft1IntkNOxSnsrNwPrtDviatNOxGain : 16|16@1+ (0.1,-100) [-100|6325.5] "%" Vector__XXX
 SG_ Aft1IntkNOxSnsrNPDviatNOxOffst : 32|8@1+ (1,-125) [-125|125] "ppm" Vector__XXX
 SG_ Aftrtrtmnt1IntkNOxSensorOpHours : 40|16@1+ (1,0) [0|64255] "hr" Vector__XXX

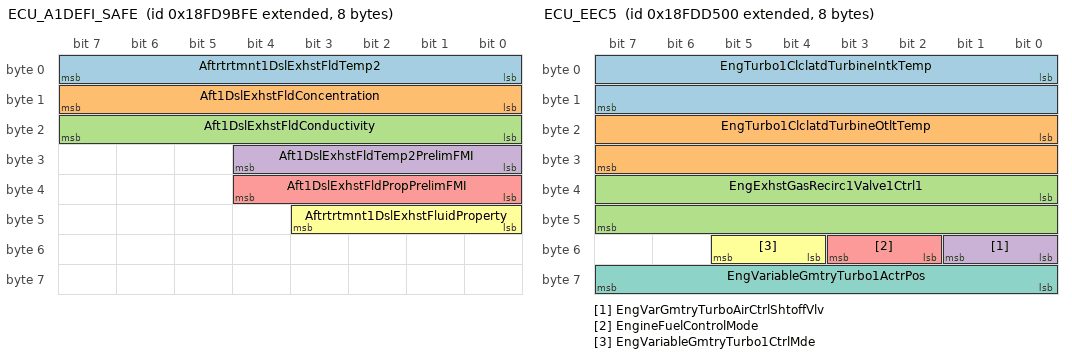
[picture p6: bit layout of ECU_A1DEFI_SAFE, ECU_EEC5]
BO_ 2566757374 ECU_A1DEFI_SAFE: 8 Vector__XXX
 SG_ Aftrtrtmnt1DslExhstFldTemp2 : 0|8@1+ (1,-40) [-40|210] "deg C" Vector__XXX
 SG_ Aft1DslExhstFldConcentration : 8|8@1+ (0.25,0) [0|62.5] "%" Vector__XXX
 SG_ Aft1DslExhstFldConductivity : 16|8@1+ (5,0) [0|1250] "uS/mm" Vector__XXX
 SG_ Aft1DslExhstFldTemp2PrelimFMI : 24|5@1+ (1,0) [0|31] "" Vector__XXX
 SG_ Aft1DslExhstFldPropPrelimFMI : 32|5@1+ (1,0) [0|31] "" Vector__XXX
 SG_ Aftrtrtmnt1DslExhstFluidProperty : 40|4@1+ (1,0) [0|15] "" Vector__XXX

BO_ 2566771968 ECU_EEC5: 8 Vector__XXX
 SG_ EngTurbo1ClclatdTurbineIntkTemp : 0|16@1+ (0.03125,-273) [-273|1734.96875] "deg C" Vector__XXX
 SG_ EngTurbo1ClclatdTurbineOtltTemp : 16|16@1+ (0.03125,-273) [-273|1734.96875] "deg C" Vector__XXX
 SG_ EngExhstGasRecirc1Valve1Ctrl1 : 32|16@1+ (0.0025,0) [0|160.6375] "%" Vector__XXX
 SG_ EngVarGmtryTurboAirCtrlShtoffVlv : 48|2@1+ (1,0) [0|3] "" Vector__XXX
 SG_ EngineFuelControlMode : 50|2@1+ (1,0) [0|3] "" Vector__XXX
 SG_ EngVariableGmtryTurbo1CtrlMde : 52|2@1+ (1,0) [0|3] "" Vector__XXX
 SG_ EngVariableGmtryTurbo1ActrPos : 56|8@1+ (0.4,0) [0|100] "%" Vector__XXX

BO_ 2566802176 ECU_TCFG2: 8 Vector__XXX
 SG_ TransmissionTorqueLimit : 0|16@1+ (0.0025,0) [0|163.8375] "Nm" Vector__XXX

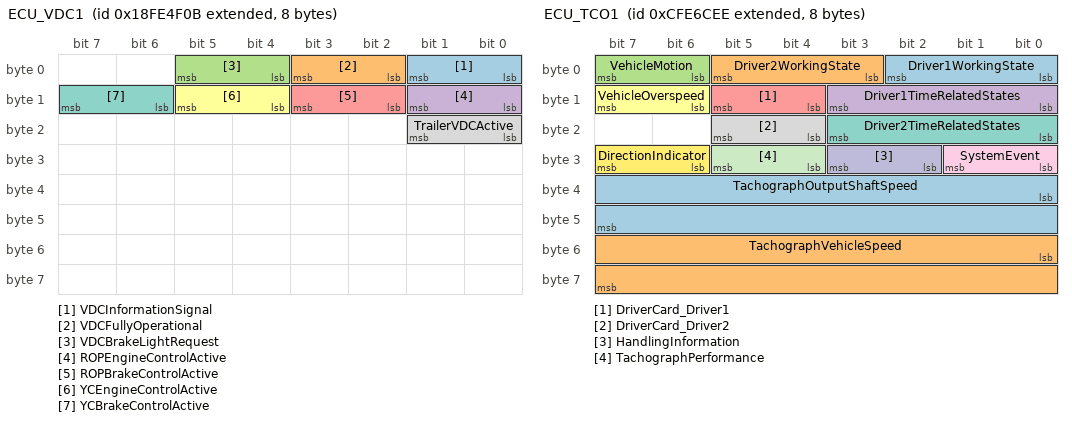
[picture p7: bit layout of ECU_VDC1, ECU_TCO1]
BO_ 2566803211 ECU_VDC1: 8 Vector__XXX
 SG_ VDCInformationSignal : 0|2@1+ (1,0) [0|3] "" Vector__XXX
 SG_ VDCFullyOperational : 2|2@1+ (1,0) [0|3] "" Vector__XXX
 SG_ VDCBrakeLightRequest : 4|2@1+ (1,0) [0|3] "" Vector__XXX
 SG_ ROPEngineControlActive : 8|2@1+ (1,0) [0|3] "" Vector__XXX
 SG_ ROPBrakeControlActive : 10|2@1+ (1,0) [0|3] "" Vector__XXX
 SG_ YCEngineControlActive : 12|2@1+ (1,0) [0|3] "" Vector__XXX
 SG_ YCBrakeControlActive : 14|2@1+ (1,0) [0|3] "" Vector__XXX
 SG_ TrailerVDCActive : 16|2@1+ (1,0) [0|3] "" Vector__XXX

BO_ 2365484270 ECU_TCO1: 8 Vector__XXX
 SG_ Driver1WorkingState : 0|3@1+ (1,0) [0|7] "" Vector__XXX
 SG_ Driver2WorkingState : 3|3@1+ (1,0) [0|7] "" Vector__XXX
 SG_ VehicleMotion : 6|2@1+ (1,0) [0|3] "" Vector__XXX
 SG_ Driver1TimeRelatedStates : 8|4@1+ (1,0) [0|15] "" Vector__XXX
 SG_ DriverCard_Driver1 : 12|2@1+ (1,0) [0|3] "" Vector__XXX
 SG_ VehicleOverspeed : 14|2@1+ (1,0) [0|3] "" Vector__XXX
 SG_ Driver2TimeRelatedStates : 16|4@1+ (1,0) [0|15] "" Vector__XXX
 SG_ DriverCard_Driver2 : 20|2@1+ (1,0) [0|3] "" Vector__XXX
 SG_ SystemEvent : 24|2@1+ (1,0) [0|3] "" Vector__XXX
 SG_ HandlingInformation : 26|2@1+ (1,0) [0|3] "" Vector__XXX
 SG_ TachographPerformance : 28|2@1+ (1,0) [0|3] "" Vector__XXX
 SG_ DirectionIndicator : 30|2@1+ (1,0) [0|3] "" Vector__XXX
 SG_ TachographOutputShaftSpeed : 32|16@1+ (0.125,0) [0|8031.875] "rpm" Vector__XXX
 SG_ TachographVehicleSpeed : 48|16@1+ (0.00390625,0) [0|250.996] "km/h" Vector__XXX

BO_ 2298375691 ECU_HRW: 8 Vector__XXX
 SG_ FrontAxle_LeftWheelSpeed : 0|16@1+ (0.00390625,0) [0|250.996] "km/h" Vector__XXX
 SG_ FrontAxle_RightWheelSpeed : 16|16@1+ (0.00390625,0) [0|250.996] "km/h" Vector__XXX
 SG_ RearAxle_LeftWheelSpeed : 32|16@1+ (0.00390625,0) [0|250.996] "km/h" Vector__XXX
 SG_ RearAxle_RightWheelSpeed : 48|16@1+ (0.00390625,0) [0|250.996] "km/h" Vector__XXX

BO_ 2566818849 VCU_AAI: 8 Vector__XXX
 SG_ HydraulicOilTemperature : 0|10@1+ (1,-40) [-40|983] "deg C" Vector__XXX
 SG_ AuxiliaryPressure1 : 16|8@1+ (16,0) [0|4000] "kPa" Vector__XXX
 SG_ AuxiliaryPressure2 : 24|8@1+ (16,0) [0|4000] "kPa" Vector__XXX
 SG_ AuxiliaryLevel : 32|16@1+ (0.1,0) [0|6425.5] "mm" Vector__XXX
 SG_ RelativeHumidity : 48|8@1+ (0.4,0) [0|100] "%" Vector__XXX

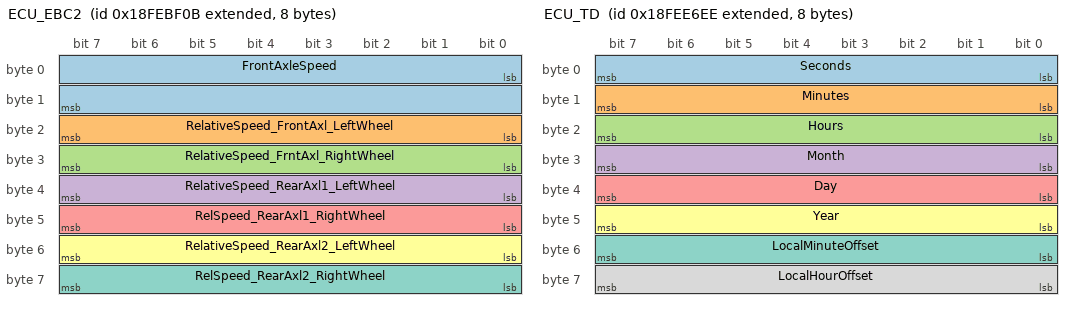
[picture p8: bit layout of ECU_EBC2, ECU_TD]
BO_ 2566831883 ECU_EBC2: 8 Vector__XXX
 SG_ FrontAxleSpeed : 0|16@1+ (0.00390625,0) [0|250.996] "km/h" Vector__XXX
 SG_ RelativeSpeed_FrontAxl_LeftWheel : 16|8@1+ (0.0625,-7.8125) [-7.8125|7.8125] "km/h" Vector__XXX
 SG_ RelativeSpeed_FrntAxl_RightWheel : 24|8@1+ (0.0625,-7.8125) [-7.8125|7.8125] "km/h" Vector__XXX
 SG_ RelativeSpeed_RearAxl1_LeftWheel : 32|8@1+ (0.0625,-7.8125) [-7.8125|7.8125] "km/h" Vector__XXX
 SG_ RelSpeed_RearAxl1_RightWheel : 40|8@1+ (0.0625,-7.8125) [-7.8125|7.8125] "km/h" Vector__XXX
 SG_ RelativeSpeed_RearAxl2_LeftWheel : 48|8@1+ (0.0625,-7.8125) [-7.8125|7.8125] "km/h" Vector__XXX
 SG_ RelSpeed_RearAxl2_RightWheel : 56|8@1+ (0.0625,-7.8125) [-7.8125|7.8125] "km/h" Vector__XXX

BO_ 2566832622 ECU_VDHR: 8 Vector__XXX
 SG_ TotalVehicleDistance : 0|32@1+ (5,0) [0|21055406] "m" Vector__XXX
 SG_ TripDistance : 32|32@1+ (5,0) [0|21055406] "m" Vector__XXX

BO_ 2566838561 VCU_AUXIO1: 8 Vector__XXX
 SG_ AuxiliaryIO04 : 0|2@1+ (1,0) [0|3] "" Vector__XXX
 SG_ AuxiliaryIO03 : 2|2@1+ (1,0) [0|3] "" Vector__XXX
 SG_ AuxiliaryIO02 : 4|2@1+ (1,0) [0|3] "" Vector__XXX
 SG_ AuxiliaryIO01 : 6|2@1+ (1,0) [0|3] "" Vector__XXX
 SG_ AuxiliaryIO08 : 8|2@1+ (1,0) [0|3] "" Vector__XXX
 SG_ AuxiliaryIO07 : 10|2@1+ (1,0) [0|3] "" Vector__XXX
 SG_ AuxiliaryIO06 : 12|2@1+ (1,0) [0|3] "" Vector__XXX
 SG_ AuxiliaryIO05 : 14|2@1+ (1,0) [0|3] "" Vector__XXX
 SG_ AuxiliaryIO12 : 16|2@1+ (1,0) [0|3] "" Vector__XXX
 SG_ AuxiliaryIO11 : 18|2@1+ (1,0) [0|3] "" Vector__XXX
 SG_ AuxiliaryIO10 : 20|2@1+ (1,0) [0|3] "" Vector__XXX
 SG_ AuxiliaryIO09 : 22|2@1+ (1,0) [0|3] "" Vector__XXX
 SG_ AuxiliaryIO16 : 24|2@1+ (1,0) [0|3] "" Vector__XXX
 SG_ AuxiliaryIO15 : 26|2@1+ (1,0) [0|3] "" Vector__XXX
 SG_ AuxiliaryIO14 : 28|2@1+ (1,0) [0|3] "" Vector__XXX
 SG_ AuxiliaryIO13 : 30|2@1+ (1,0) [0|3] "" Vector__XXX
 SG_ AuxiliaryIOChannel1 : 32|16@1+ (1,0) [0|64255] "" Vector__XXX
 SG_ AuxiliaryIOChannel2 : 48|16@1+ (1,0) [0|64255] "" Vector__XXX

BO_ 2566839296 ECU_IO: 8 Vector__XXX
 SG_ EngineTotalIdleFuelUsed : 0|32@1+ (0.5,0) [0|2105540607.5] "l" Vector__XXX
 SG_ EngineTotalIdleHours : 32|32@1+ (0.05,0) [0|210554060.75] "hr" Vector__XXX

BO_ 2566841600 ECU_HOURS: 8 Vector__XXX
 SG_ EngineTotalHoursOfOperation : 0|32@1+ (0.05,0) [0|210554060.75] "hr" Vector__XXX
 SG_ EngineTotalRevolutions : 32|32@1+ (1000,0) [0|4211081215000] "" Vector__XXX

BO_ 2566842094 ECU_TD: 8 Vector__XXX
 SG_ Seconds : 0|8@1+ (0.25,0) [0|62.5] "s" Vector__XXX
 SG_ Minutes : 8|8@1+ (1,0) [0|250] "min" Vector__XXX
 SG_ Hours : 16|8@1+ (1,0) [0|250] "hr" Vector__XXX
 SG_ Month : 24|8@1+ (1,0) [0|250] "Months" Vector__XXX
 SG_ Day : 32|8@1+ (0.25,0) [0|62.5] "Days" Vector__XXX
 SG_ Year : 40|8@1+ (1,1985) [1985|2235] "Years" Vector__XXX
 SG_ LocalMinuteOffset : 48|8@1+ (1,-125) [-125|125] "min" Vector__XXX
 SG_ LocalHourOffset : 56|8@1+ (1,-125) [-125|125] "hr" Vector__XXX

BO_ 2566842112 ECU_VH: 8 Vector__XXX
 SG_ TotalVehicleHours : 0|32@1+ (0.05,0) [0|210554060.75] "hr" Vector__XXX
 SG_ TotalPowerTakeoffHours : 32|32@1+ (0.05,0) [0|210554060.75] "hr" Vector__XXX

BO_ 2566843136 ECU_CI: 8 Vector__XXX

BO_ 2566843392 ECU_VI: 8 Vector__XXX
 SG_ VehicleIdentificationNumber : 0|64@1+ (1,0) [0|0] "ASCII" Vector__XXX

BO_ 2566843648 ECU_CCSS: 8 Vector__XXX
 SG_ MaximumVehicleSpeedLimit : 0|8@1+ (1,0) [0|250] "km/h" Vector__XXX
 SG_ CruiseControlHighSetLimitSpeed : 8|8@1+ (1,0) [0|250] "km/h" Vector__XXX
 SG_ CruiseControlLowSetLimitSpeed : 16|8@1+ (1,0) [0|250] "km/h" Vector__XXX
 SG_ MaximumVehicleSpeedLimitHighReso : 24|16@1+ (0.00390625,0) [0|250.996] "km/h" Vector__XXX

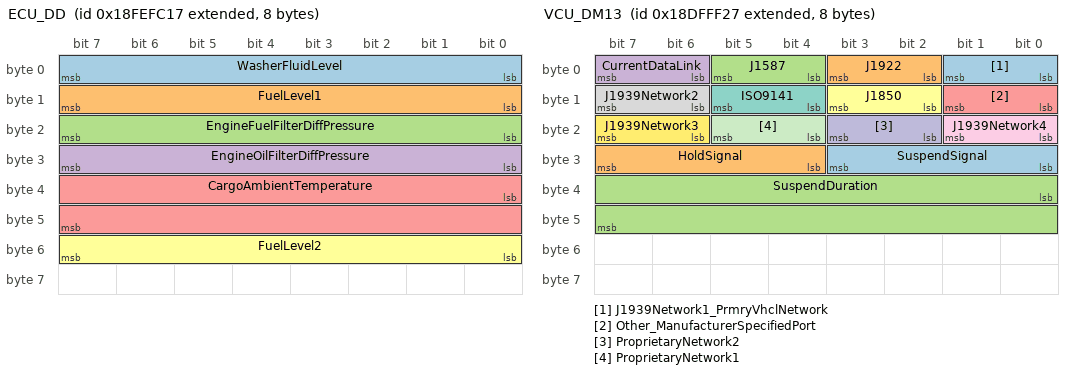
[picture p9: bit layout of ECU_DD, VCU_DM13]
BO_ 2566847511 ECU_DD: 8 Vector__XXX
 SG_ WasherFluidLevel : 0|8@1+ (0.4,0) [0|100] "%" Vector__XXX
 SG_ FuelLevel1 : 8|8@1+ (0.4,0) [0|100] "%" Vector__XXX
 SG_ EngineFuelFilterDiffPressure : 16|8@1+ (2,0) [0|500] "kPa" Vector__XXX
 SG_ EngineOilFilterDiffPressure : 24|8@1+ (0.5,0) [0|125] "kPa" Vector__XXX
 SG_ CargoAmbientTemperature : 32|16@1+ (0.03125,-273) [-273|1734.96875] "deg C" Vector__XXX
 SG_ FuelLevel2 : 48|8@1+ (0.4,0) [0|100] "%" Vector__XXX

BO_ 2564816679 VCU_DM13: 8 Vector__XXX
 SG_ J1939Network1_PrmryVhclNetwork : 0|2@1+ (1,0) [0|3] "" Vector__XXX
 SG_ J1922 : 2|2@1+ (1,0) [0|3] "" Vector__XXX
 SG_ J1587 : 4|2@1+ (1,0) [0|3] "" Vector__XXX
 SG_ CurrentDataLink : 6|2@1+ (1,0) [0|3] "" Vector__XXX
 SG_ Other_ManufacturerSpecifiedPort : 8|2@1+ (1,0) [0|3] "" Vector__XXX
 SG_ J1850 : 10|2@1+ (1,0) [0|3] "" Vector__XXX
 SG_ ISO9141 : 12|2@1+ (1,0) [0|3] "" Vector__XXX
 SG_ J1939Network2 : 14|2@1+ (1,0) [0|3] "" Vector__XXX
 SG_ J1939Network4 : 16|2@1+ (1,0) [0|3] "" Vector__XXX
 SG_ ProprietaryNetwork2 : 18|2@1+ (1,0) [0|3] "" Vector__XXX
 SG_ ProprietaryNetwork1 : 20|2@1+ (1,0) [0|3] "" Vector__XXX
 SG_ J1939Network3 : 22|2@1+ (1,0) [0|3] "" Vector__XXX
 SG_ SuspendSignal : 24|4@1+ (1,0) [0|15] "" Vector__XXX
 SG_ HoldSignal : 28|4@1+ (1,0) [0|15] "" Vector__XXX
 SG_ SuspendDuration : 32|16@1+ (1,0) [0|64255] "s" Vector__XXX

BO_ 2564816929 VCU_CM1: 8 Vector__XXX
 SG_ EngineFan1RequestedPercentSpeed : 0|8@1+ (0.4,0) [0|100] "%" Vector__XXX
 SG_ CabInteriorTemperatureCommand : 8|16@1+ (0.03125,-273) [-273|1734.96875] "deg C" Vector__XXX
 SG_ AuxHeaterCoolantPumpRequest : 24|2@1+ (1,0) [0|3] "" Vector__XXX
 SG_ BatteryMainSwitchHoldRequest : 26|2@1+ (1,0) [0|3] "" Vector__XXX
 SG_ OperatorSeatDirectionSwitch : 28|2@1+ (1,0) [0|3] "" Vector__XXX
 SG_ SeatBeltSwitch : 30|2@1+ (1,0) [0|3] "" Vector__XXX
 SG_ ParkBrakeCommand : 32|2@1+ (1,0) [0|3] "" Vector__XXX
 SG_ VehicleLmtngSpdGvrnrDecrementSw : 34|2@1+ (1,0) [0|3] "" Vector__XXX
 SG_ VehicleLmtngSpdGvrnrIncrementSw : 36|2@1+ (1,0) [0|3] "" Vector__XXX
 SG_ VehicleLmtngSpeedGvrnrEnblSwitch : 38|2@1+ (1,0) [0|3] "" Vector__XXX
 SG_ AftrtrtmntRegenInhbtSwitch : 40|2@1+ (1,0) [0|3] "" Vector__XXX
 SG_ AftrtrtmntRegenForceSwitch : 42|2@1+ (1,0) [0|3] "" Vector__XXX
 SG_ AutoGearShiftingEnableSwitch : 44|2@1+ (1,0) [0|3] "" Vector__XXX
 SG_ EngineAutomaticStartEnableSwitch : 46|2@1+ (1,0) [0|3] "" Vector__XXX
 SG_ AuxiliaryHeaterModeRequest : 48|4@1+ (1,0) [0|15] "" Vector__XXX
 SG_ RequestEngineZoneHeating : 52|2@1+ (1,0) [0|3] "" Vector__XXX
 SG_ RequestCabZoneHeating : 54|2@1+ (1,0) [0|3] "" Vector__XXX
 SG_ SelectedMaximumVehicleSpeedLimit : 56|8@1+ (1,0) [0|250] "" Vector__XXX

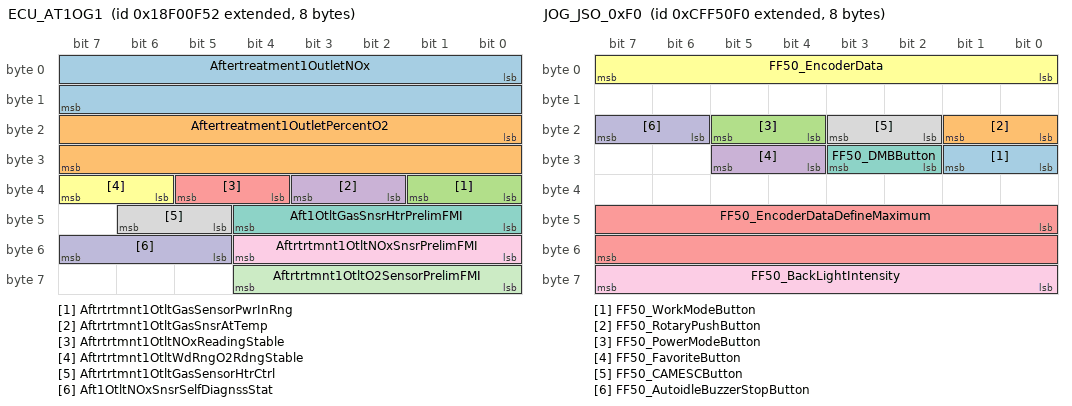
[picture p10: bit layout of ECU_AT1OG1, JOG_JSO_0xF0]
BO_ 2565869394 ECU_AT1OG1: 8 Vector__XXX
 SG_ Aftertreatment1OutletNOx : 0|16@1+ (0.05,-200) [-200|3012.75] "ppm" Vector__XXX
 SG_ Aftertreatment1OutletPercentO2 : 16|16@1+ (0.000514,-12) [-12|21.02707] "%" Vector__XXX
 SG_ Aftrtrtmnt1OtltGasSensorPwrInRng : 32|2@1+ (1,0) [0|3] "" Vector__XXX
 SG_ Aftrtrtmnt1OtltGasSnsrAtTemp : 34|2@1+ (1,0) [0|3] "" Vector__XXX
 SG_ Aftrtrtmnt1OtltNOxReadingStable : 36|2@1+ (1,0) [0|3] "" Vector__XXX
 SG_ Aftrtrtmnt1OtltWdRngO2RdngStable : 38|2@1+ (1,0) [0|3] "" Vector__XXX
 SG_ Aft1OtltGasSnsrHtrPrelimFMI : 40|5@1+ (1,0) [0|31] "" Vector__XXX
 SG_ Aftrtrtmnt1OtltGasSensorHtrCtrl : 45|2@1+ (1,0) [0|3] "" Vector__XXX
 SG_ Aftrtrtmnt1OtltNOxSnsrPrelimFMI : 48|5@1+ (1,0) [0|31] "" Vector__XXX
 SG_ Aft1OtltNOxSnsrSelfDiagnssStat : 53|3@1+ (1,0) [0|7] "" Vector__XXX
 SG_ Aftrtrtmnt1OtltO2SensorPrelimFMI : 56|5@1+ (1,0) [0|31] "" Vector__XXX

BO_ 2566883072 ECU_DLN7: 8 Vector__XXX
 SG_ UreaLevel : 0|8@1+ (0.4,0) [0|100] "%" Vector__XXX

BO_ 2565668641 VCU_BAM_REX: 8 Vector__XXX
 SG_ VCU_BAM_REX_Mux M : 0|8@1+ (1,0) [0|0] "" Vector__XXX
 SG_ TotalMessageSize16 m16 : 8|16@1+ (1,0) [0|64255] "" Vector__XXX
 SG_ TotalNumberOfPackets16 m16 : 24|8@1+ (1,0) [0|255] "" Vector__XXX
 SG_ MaximumNumberOfPackets m16 : 32|8@1+ (1,0) [0|255] "" Vector__XXX
 SG_ PGNOfThePacketedMessage16 m16 : 40|24@1+ (1,0) [0|16777215] "" Vector__XXX
 SG_ NumberOfPacketsThatCanBeSent m17 : 8|8@1+ (1,0) [0|255] "" Vector__XXX
 SG_ NextPacketNumberToBeSent m17 : 16|8@1+ (1,0) [0|255] "" Vector__XXX
 SG_ PGNOfThePacketedMessage17 m17 : 40|24@1+ (1,0) [0|16777215] "" Vector__XXX
 SG_ TotalMessageSize19 m19 : 8|16@1+ (1,0) [0|64255] "" Vector__XXX
 SG_ TotalNumberOfPackets19 m19 : 24|8@1+ (1,0) [0|255] "" Vector__XXX
 SG_ PGNOfThePacketedMessage19 m19 : 40|24@1+ (1,0) [0|16777215] "" Vector__XXX
 SG_ TotalMessageSize32 m32 : 8|16@1+ (1,0) [0|64255] "" Vector__XXX
 SG_ TotalNumberOfPackets32 m32 : 24|8@1+ (1,0) [0|255] "" Vector__XXX
 SG_ PGNOfThePacketedMessage32 m32 : 40|24@1+ (1,0) [0|16777215] "" Vector__XXX
 SG_ ConnectionAbortReason m255 : 8|8@1+ (1,0) [0|255] "" Vector__XXX
 SG_ ParameterGrpNoOfPacketedMessage m255 : 40|24@1+ (1,0) [0|16777215] "" Vector__XXX

BO_ 2564882192 ECU_CM1_RDE: 8 Vector__XXX
 SG_ EngineFan1RequestedPercentSpeed : 0|8@1+ (0.4,0) [0|100] "%" Vector__XXX
 SG_ CabInteriorTemperatureCommand : 8|16@1+ (0.03125,-273) [-273|1734.96875] "deg C" Vector__XXX
 SG_ AuxHeaterCoolantPumpRequest : 24|2@1+ (1,0) [0|3] "" Vector__XXX
 SG_ BatteryMainSwitchHoldRequest : 26|2@1+ (1,0) [0|3] "" Vector__XXX
 SG_ OperatorSeatDirectionSwitch : 28|2@1+ (1,0) [0|3] "" Vector__XXX
 SG_ SeatBeltSwitch : 30|2@1+ (1,0) [0|3] "" Vector__XXX
 SG_ ParkBrakeCommand : 32|2@1+ (1,0) [0|3] "" Vector__XXX
 SG_ VehicleLmtngSpdGvrnrDecrementSw : 34|2@1+ (1,0) [0|3] "" Vector__XXX
 SG_ VehicleLmtngSpdGvrnrIncrementSw : 36|2@1+ (1,0) [0|3] "" Vector__XXX
 SG_ VehicleLmtngSpeedGvrnrEnblSwitch : 38|2@1+ (1,0) [0|3] "" Vector__XXX
 SG_ AftrtrtmntRegenInhbtSwitch : 40|2@1+ (1,0) [0|3] "" Vector__XXX
 SG_ AftrtrtmntRegenForceSwitch : 42|2@1+ (1,0) [0|3] "" Vector__XXX
 SG_ AutoGearShiftingEnableSwitch : 44|2@1+ (1,0) [0|3] "" Vector__XXX
 SG_ EngineAutomaticStartEnableSwitch : 46|2@1+ (1,0) [0|3] "" Vector__XXX
 SG_ AuxiliaryHeaterModeRequest : 48|4@1+ (1,0) [0|15] "" Vector__XXX
 SG_ RequestEngineZoneHeating : 52|2@1+ (1,0) [0|3] "" Vector__XXX
 SG_ RequestCabZoneHeating : 54|2@1+ (1,0) [0|3] "" Vector__XXX
 SG_ SelectedMaximumVehicleSpeedLimit : 56|8@1+ (1,0) [0|250] "" Vector__XXX

BO_ 2365457697 VCU_GTACP: 8 Vector__XXX
 SG_ GeneratorTotalRealPower : 0|32@1+ (1,-2000000000) [-2000000000|2211081215] "W" Vector__XXX
 SG_ GeneratorTotalApparentPower : 32|32@1+ (1,-2000000000) [-2000000000|2211081215] "VA" Vector__XXX

BO_ 2566887720 GP_AVMRM: 8 Vector__XXX
 SG_ FF99_Ultrasonic_optionset : 23|1@1+ (1,0) [0|1] "" Vector__XXX
 SG_ FF99_CameraParamVersion_MSB_Copy : 56|7@1+ (1,0) [0|127] "" Vector__XXX
 SG_ FF99_CameraParamCalibState : 63|1@1+ (1,0) [0|1] "" Vector__XXX
 SG_ FF99_WarningGuideSettingCommand : 40|1@1+ (1,0) [0|1] "" Vector__XXX
 SG_ FF99_ViewMode : 0|4@1+ (1,0) [0|15] "" Vector__XXX
 SG_ FF99_VehicleType_2 : 17|2@1+ (1,0) [0|3] "" Vector__XXX
 SG_ FF99_VehicleType_1 : 16|1@1+ (1,0) [0|1] "" Vector__XXX
 SG_ FF99_UltrasonicSensor12Command : 31|1@1+ (1,0) [0|1] "" Vector__XXX
 SG_ FF99_UltrasonicSensor11Command : 30|1@1+ (1,0) [0|1] "" Vector__XXX
 SG_ FF99_UltrasonicSensor10Command : 29|1@1+ (1,0) [0|1] "" Vector__XXX
 SG_ FF99_UltrasonicSensor09Command : 28|1@1+ (1,0) [0|1] "" Vector__XXX
 SG_ FF99_UltrasonicSensor08Command : 39|1@1+ (1,0) [0|1] "" Vector__XXX
 SG_ FF99_UltrasonicSensor07Command : 38|1@1+ (1,0) [0|1] "" Vector__XXX
 SG_ FF99_UltrasonicSensor06Command : 37|1@1+ (1,0) [0|1] "" Vector__XXX
 SG_ FF99_UltrasonicSensor05Command : 36|1@1+ (1,0) [0|1] "" Vector__XXX
 SG_ FF99_UltrasonicSensor04Command : 35|1@1+ (1,0) [0|1] "" Vector__XXX
 SG_ FF99_UltrasonicSensor03Command : 34|1@1+ (1,0) [0|1] "" Vector__XXX
 SG_ FF99_UltrasonicSensor02Command : 33|1@1+ (1,0) [0|1] "" Vector__XXX
 SG_ FF99_UltrasonicSensor01Command : 32|1@1+ (1,0) [0|1] "" Vector__XXX
 SG_ FF99_UltrasonicDistance : 19|1@1+ (1,0) [0|1] "" Vector__XXX
 SG_ FF99_UltrasonicBuzzerStop : 22|1@1+ (1,0) [0|1] "" Vector__XXX
 SG_ FF99_UltrasonicBuzzerOff_Copy_1 : 20|1@1+ (1,0) [0|1] "" Vector__XXX
 SG_ FF99_TonUnits : 8|4@1+ (1,0) [0|15] "" Vector__XXX
 SG_ FF99_TonTens : 12|4@1+ (1,0) [0|15] "" Vector__XXX
 SG_ FF99_Language : 42|6@1+ (1,0) [0|63] "" Vector__XXX
 SG_ FF99_FactoryType : 4|4@1+ (1,0) [0|15] "" Vector__XXX
 SG_ FF99_FactoryResetCommand : 24|1@1+ (1,0) [0|1] "" Vector__XXX
 SG_ FF99_CameraParamVersion_LSB : 48|8@1+ (1,0) [0|255] "" Vector__XXX
 SG_ FF99_CalibTolMenuApproachCommand : 41|1@1+ (1,0) [0|1] "" Vector__XXX
 SG_ FF99_CalibrationToleranceCommand : 25|2@1+ (1,0) [0|3] "" Vector__XXX
 SG_ FF99_BoomCameraOption : 21|1@1+ (1,0) [0|1] "" Vector__XXX
 SG_ FF99_ApplySettingCommand : 27|1@1+ (1,0) [0|1] "" Vector__XXX

BO_ 2565821480 GP_SMAVM: 8 Vector__XXX
 SG_ EF54_SubCMD : 8|8@1+ (1,0) [0|255] "" Vector__XXX
 SG_ EF54_MainCMD : 0|8@1+ (1,0) [0|255] "" Vector__XXX
 SG_ EF54_Data2_GaugePanelType : 24|8@1+ (1,0) [0|255] "" Vector__XXX
 SG_ EF54_Data1_BacklightIntensity : 16|8@1+ (1,0) [0|255] "" Vector__XXX

BO_ 2565816616 GP_SMGW: 8 Vector__XXX
 SG_ EF41_SubCMD : 8|8@1+ (1,0) [0|255] "" Vector__XXX
 SG_ EF41_MainCMD : 0|8@1+ (1,0) [0|255] "" Vector__XXX
 SG_ EF41_Data1_GatewayVolume : 16|8@1+ (1,0) [0|255] "" Vector__XXX

BO_ 2566886952 GP_AVMVM: 8 Vector__XXX
 SG_ FF96_ViewMode : 0|4@1+ (1,0) [0|15] "" Vector__XXX

BO_ 2365542640 JOG_JSO_0xF0: 8 Vector__XXX
 SG_ FF50_WorkModeButton : 24|2@1+ (1,0) [0|3] "" Vector__XXX
 SG_ FF50_RotaryPushButton : 16|2@1+ (1,0) [0|3] "" Vector__XXX
 SG_ FF50_PowerModeButton : 20|2@1+ (1,0) [0|3] "" Vector__XXX
 SG_ FF50_FavoriteButton : 28|2@1+ (1,0) [0|3] "" Vector__XXX
 SG_ FF50_EncoderDataDefineMaximum : 40|16@1+ (1,0) [0|65535] "" Vector__XXX
 SG_ FF50_EncoderData : 0|8@1+ (1,0) [0|255] "" Vector__XXX
 SG_ FF50_DMBButton : 26|2@1+ (1,0) [0|3] "" Vector__XXX
 SG_ FF50_CAMESCButton : 18|2@1+ (1,0) [0|3] "" Vector__XXX
 SG_ FF50_BackLightIntensity : 56|8@1+ (1,0) [0|255] "" Vector__XXX
 SG_ FF50_AutoidleBuzzerStopButton : 22|2@1+ (1,0) [0|3] "" Vector__XXX

BO_ 2566834762 TMS_DM1: 13 Vector__XXX
 SG_ FECA_03_SPN3 : 101|3@1+ (1,0) [0|7] "" Vector__XXX
 SG_ FECA_03_SPN2 : 88|8@1+ (1,0) [0|255] "" Vector__XXX
 SG_ FECA_03_SPN1 : 80|8@1+ (1,0) [0|255] "" Vector__XXX
 SG_ FECA_03_FMI : 96|5@1+ (1,0) [0|31] "" Vector__XXX
 SG_ FECA_02_SPN3 : 69|3@1+ (1,0) [0|7] "" Vector__XXX
 SG_ FECA_02_SPN2 : 56|8@1+ (1,0) [0|255] "" Vector__XXX
 SG_ FECA_02_SPN1 : 48|8@1+ (1,0) [0|255] "" Vector__XXX
 SG_ FECA_02_FMI : 64|5@1+ (1,0) [0|31] "" Vector__XXX
 SG_ FECA_01_SPN3 : 37|3@1+ (1,0) [0|7] "" Vector__XXX
 SG_ FECA_01_SPN2 : 24|8@1+ (1,0) [0|255] "" Vector__XXX
 SG_ FECA_01_SPN1 : 16|8@1+ (1,0) [0|255] "" Vector__XXX
 SG_ FECA_01_FMI : 32|5@1+ (1,0) [0|31] "" Vector__XXX

BO_ 2565818920 GP_SMTMS: 9 Vector__XXX
 SG_ EF4A_SuspectParameterNumber : 0|19@1+ (1,0) [0|524287] "" Vector__XXX
 SG_ EF4A_OTAUserApprovalCommand : 64|2@1+ (1,0) [0|3] "" Vector__XXX
 SG_ EF4A_OTAPossibilitySCRCommand : 66|4@1+ (1,0) [0|15] "" Vector__XXX
 SG_ EF4A_DataField : 24|40@1+ (1,0) [0|1099511627775] "" Vector__XXX

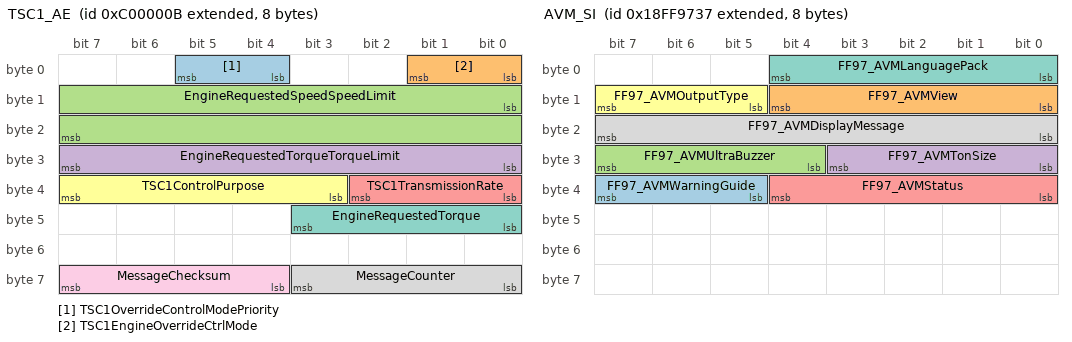
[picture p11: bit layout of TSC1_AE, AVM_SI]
BO_ 2348810251 TSC1_AE: 8 Vector__XXX
 SG_ TSC1OverrideControlModePriority : 4|2@1+ (1,0) [0|3] "" Vector__XXX
 SG_ TSC1EngineOverrideCtrlMode : 0|2@1+ (1,0) [0|3] "" Vector__XXX
 SG_ EngineRequestedSpeedSpeedLimit : 8|16@1+ (0.125,0) [0|8031.875] "rpm" Vector__XXX
 SG_ EngineRequestedTorqueTorqueLimit : 24|8@1+ (1,-125) [-125|125] "%" Vector__XXX
 SG_ TSC1TransmissionRate : 32|3@1+ (1,0) [0|7] "" Vector__XXX
 SG_ TSC1ControlPurpose : 35|5@1+ (1,0) [0|31] "" Vector__XXX
 SG_ EngineRequestedTorque : 40|4@1+ (0.125,0) [0|0.875] "%" Vector__XXX
 SG_ MessageCounter : 56|4@1+ (1,0) [0|15] "" Vector__XXX
 SG_ MessageChecksum : 60|4@1+ (1,0) [0|15] "" Vector__XXX

BO_ 2566871629 CombiSW_HCMD: 8 Vector__XXX
 SG_ FF5A_HornSwitchInput : 34|2@1+ (1,0) [0|3] "" Vector__XXX

BO_ 2566888759 AVM_VER: 8 Vector__XXX
 SG_ FF9D_AVMVersionYear : 32|16@1+ (1,0) [0|65535] "" Vector__XXX
 SG_ FF9D_AVMVersionMonth : 24|8@1+ (1,0) [0|255] "" Vector__XXX
 SG_ FF9D_AVMVersionDate : 16|8@1+ (1,0) [0|255] "" Vector__XXX
 SG_ FF9D_AVMVersion : 0|16@1+ (1,0) [0|65535] "" Vector__XXX

BO_ 2566888503 AVM_CP: 96 Vector__XXX
 SG_ FF9C_AVMCameraParameter_4_2 : 736|32@1+ (1,0) [0|4294967295] "" Vector__XXX
 SG_ FF9C_AVMCameraParameter_4_1 : 672|64@1+ (1,0) [0|1.84467440737096E+019] "" Vector__XXX
 SG_ FF9C_AVMCameraParameter_3_4 : 640|32@1+ (1,0) [0|4294967295] "" Vector__XXX
 SG_ FF9C_AVMCameraParameter_3_3 : 576|64@1+ (1,0) [0|1.84467440737096E+019] "" Vector__XXX
 SG_ FF9C_AVMCameraParameter_3_2 : 512|64@1+ (1,0) [0|1.84467440737096E+019] "" Vector__XXX
 SG_ FF9C_AVMCameraParameter_3_1 : 448|64@1+ (1,0) [0|1.84467440737096E+019] "" Vector__XXX
 SG_ FF9C_AVMCameraParameter_2_4 : 416|32@1+ (1,0) [0|4294967295] "" Vector__XXX
 SG_ FF9C_AVMCameraParameter_2_3 : 352|64@1+ (1,0) [0|1.84467440737096E+019] "" Vector__XXX
 SG_ FF9C_AVMCameraParameter_2_2 : 288|64@1+ (1,0) [0|1.84467440737096E+019] "" Vector__XXX
 SG_ FF9C_AVMCameraParameter_2_1 : 224|64@1+ (1,0) [0|1.84467440737096E+019] "" Vector__XXX
 SG_ FF9C_AVMCameraParameter_1_4 : 192|32@1+ (1,0) [0|4294967295] "" Vector__XXX
 SG_ FF9C_AVMCameraParameter_1_3 : 128|64@1+ (1,0) [0|1.84467440737096E+019] "" Vector__XXX
 SG_ FF9C_AVMCameraParameter_1_2 : 64|64@1+ (1,0) [0|1.84467440737096E+019] "" Vector__XXX
 SG_ FF9C_AVMCameraParameter_1_1 : 0|64@1+ (1,0) [0|1.84467440737096E+019] "" Vector__XXX

BO_ 2566887991 AVM_SM: 8 Vector__XXX
 SG_ FF9A_Ultrasonic_optionset : 23|1@1+ (1,0) [0|1] "" Vector__XXX
 SG_ FF9A_WarningGuideSettingCommand : 40|1@1+ (1,0) [0|1] "" Vector__XXX
 SG_ FF9A_Language : 42|6@1+ (1,0) [0|63] "" Vector__XXX
 SG_ FF9A_CameraParamVersion_MSB : 56|7@1+ (1,0) [0|127] "" Vector__XXX
 SG_ FF9A_CameraParamVersion_LSB : 48|8@1+ (1,0) [0|255] "" Vector__XXX
 SG_ FF9A_CameraParamCalibState : 63|1@1+ (1,0) [0|1] "" Vector__XXX
 SG_ FF9A_CalibTolMenuApproachCommand : 41|1@1+ (1,0) [0|1] "" Vector__XXX
 SG_ FF9A_ViewMode : 0|4@1+ (1,0) [0|15] "" Vector__XXX
 SG_ FF9A_VehicleType_2 : 17|2@1+ (1,0) [0|3] "" Vector__XXX
 SG_ FF9A_VehicleType_1 : 16|1@1+ (1,0) [0|1] "" Vector__XXX
 SG_ FF9A_UltrasonicSensor12Command : 31|1@1+ (1,0) [0|1] "" Vector__XXX
 SG_ FF9A_UltrasonicSensor11Command : 30|1@1+ (1,0) [0|1] "" Vector__XXX
 SG_ FF9A_UltrasonicSensor10Command : 29|1@1+ (1,0) [0|1] "" Vector__XXX
 SG_ FF9A_UltrasonicSensor09Command : 28|1@1+ (1,0) [0|1] "" Vector__XXX
 SG_ FF9A_UltrasonicSensor08Command : 39|1@1+ (1,0) [0|1] "" Vector__XXX
 SG_ FF9A_UltrasonicSensor07Command : 38|1@1+ (1,0) [0|1] "" Vector__XXX
 SG_ FF9A_UltrasonicSensor06Command : 37|1@1+ (1,0) [0|1] "" Vector__XXX
 SG_ FF9A_UltrasonicSensor05Command : 36|1@1+ (1,0) [0|1] "" Vector__XXX
 SG_ FF9A_UltrasonicSensor04Command : 35|1@1+ (1,0) [0|1] "" Vector__XXX
 SG_ FF9A_UltrasonicSensor03Command : 34|1@1+ (1,0) [0|1] "" Vector__XXX
 SG_ FF9A_UltrasonicSensor02Command : 33|1@1+ (1,0) [0|1] "" Vector__XXX
 SG_ FF9A_UltrasonicSensor01Command : 32|1@1+ (1,0) [0|1] "" Vector__XXX
 SG_ FF9A_UltrasonicDistance : 19|1@1+ (1,0) [0|1] "" Vector__XXX
 SG_ FF9A_UltrasonicBuzzerStop : 22|1@1+ (1,0) [0|1] "" Vector__XXX
 SG_ FF9A_UltrasonicBuzzerOff : 20|1@1+ (1,0) [0|1] "" Vector__XXX
 SG_ FF9A_TonUnits : 8|4@1+ (1,0) [0|15] "" Vector__XXX
 SG_ FF9A_TonTens : 12|4@1+ (1,0) [0|15] "" Vector__XXX
 SG_ FF9A_FactoryType : 4|4@1+ (1,0) [0|15] "" Vector__XXX
 SG_ FF9A_FactoryResetCommand : 24|1@1+ (1,0) [0|1] "" Vector__XXX
 SG_ FF9A_CalibrationToleranceCommand : 25|2@1+ (1,0) [0|3] "" Vector__XXX
 SG_ FF9A_BoomCameraOption : 21|1@1+ (1,0) [0|1] "" Vector__XXX
 SG_ FF9A_ApplySettingCommand : 27|1@1+ (1,0) [0|1] "" Vector__XXX

BO_ 2566887223 AVM_SI: 8 Vector__XXX
 SG_ FF97_AVMWarningGuide : 37|3@1+ (1,0) [0|7] "" Vector__XXX
 SG_ FF97_AVMView : 8|5@1+ (1,0) [0|31] "" Vector__XXX
 SG_ FF97_AVMUltraBuzzer : 28|4@1+ (1,0) [0|15] "" Vector__XXX
 SG_ FF97_AVMTonSize : 24|4@1+ (1,0) [0|15] "" Vector__XXX
 SG_ FF97_AVMStatus : 32|5@1+ (1,0) [0|31] "" Vector__XXX
 SG_ FF97_AVMOutputType : 13|3@1+ (1,0) [0|7] "" Vector__XXX
 SG_ FF97_AVMLanguagePack : 0|5@1+ (1,0) [0|31] "" Vector__XXX
 SG_ FF97_AVMDisplayMessage : 16|8@1+ (1,0) [0|255] "" Vector__XXX

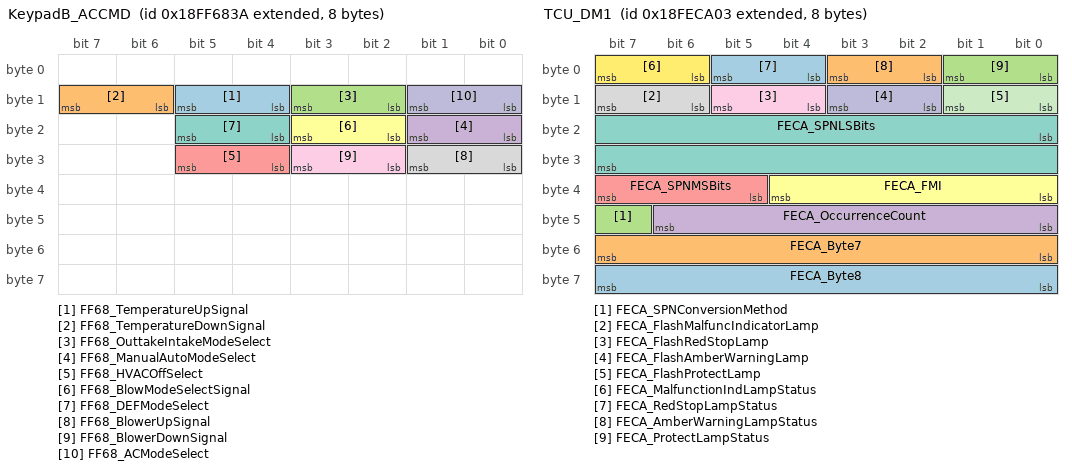
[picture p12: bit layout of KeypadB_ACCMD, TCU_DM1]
BO_ 2566875194 KeypadB_ACCMD: 8 Vector__XXX
 SG_ FF68_TemperatureUpSignal : 12|2@1+ (1,0) [0|3] "" Vector__XXX
 SG_ FF68_TemperatureDownSignal : 14|2@1+ (1,0) [0|3] "" Vector__XXX
 SG_ FF68_OuttakeIntakeModeSelect : 10|2@1+ (1,0) [0|3] "" Vector__XXX
 SG_ FF68_ManualAutoModeSelect : 16|2@1+ (1,0) [0|3] "" Vector__XXX
 SG_ FF68_HVACOffSelect : 28|2@1+ (1,0) [0|3] "" Vector__XXX
 SG_ FF68_BlowModeSelectSignal : 18|2@1+ (1,0) [0|3] "" Vector__XXX
 SG_ FF68_DEFModeSelect : 20|2@1+ (1,0) [0|3] "" Vector__XXX
 SG_ FF68_BlowerUpSignal : 24|2@1+ (1,0) [0|3] "" Vector__XXX
 SG_ FF68_BlowerDownSignal : 26|2@1+ (1,0) [0|3] "" Vector__XXX
 SG_ FF68_ACModeSelect : 8|2@1+ (1,0) [0|3] "" Vector__XXX

BO_ 2365554944 ECU_DLN2: 8 Vector__XXX
 SG_ FF81_EngineLoad : 22|2@1+ (1,0) [0|3] "" Vector__XXX
 SG_ FF81_DPFRegenerationState : 10|4@1+ (1,0) [0|15] "" Vector__XXX

BO_ 2566881313 VCU_DLN1: 8 Vector__XXX
 SG_ FF80_EngineStopWithoutErrorCode : 24|2@1+ (1,0) [0|3] "" Vector__XXX
 SG_ FF80_EngineStopWithErrorCode : 22|2@1+ (1,0) [0|3] "" Vector__XXX
 SG_ FF80_EngineStart : 20|2@1+ (1,0) [0|3] "" Vector__XXX
 SG_ FF80_APPscania : 8|8@1+ (0.4,0) [0|102] "" Vector__XXX

BO_ 2566834691 TCU_DM1: 8 Vector__XXX
 SG_ FECA_Byte8 : 56|8@1+ (1,0) [0|255] "" Vector__XXX
 SG_ FECA_Byte7 : 48|8@1+ (1,0) [0|255] "" Vector__XXX
 SG_ FECA_SPNConversionMethod : 47|1@1+ (1,0) [0|1] "" Vector__XXX
 SG_ FECA_OccurrenceCount : 40|7@1+ (1,0) [0|127] "" Vector__XXX
 SG_ FECA_SPNMSBits : 37|3@1+ (1,0) [0|7] "" Vector__XXX
 SG_ FECA_FMI : 32|5@1+ (1,0) [0|31] "" Vector__XXX
 SG_ FECA_SPNLSBits : 16|16@1+ (1,0) [0|65535] "" Vector__XXX
 SG_ FECA_FlashMalfuncIndicatorLamp : 14|2@1+ (1,0) [0|3] "" Vector__XXX
 SG_ FECA_FlashRedStopLamp : 12|2@1+ (1,0) [0|3] "" Vector__XXX
 SG_ FECA_FlashAmberWarningLamp : 10|2@1+ (1,0) [0|3] "" Vector__XXX
 SG_ FECA_FlashProtectLamp : 8|2@1+ (1,0) [0|3] "" Vector__XXX
 SG_ FECA_MalfunctionIndLampStatus : 6|2@1+ (1,0) [0|3] "" Vector__XXX
 SG_ FECA_RedStopLampStatus : 4|2@1+ (1,0) [0|3] "" Vector__XXX
 SG_ FECA_AmberWarningLampStatus : 2|2@1+ (1,0) [0|3] "" Vector__XXX
 SG_ FECA_ProtectLampStatus : 0|2@1+ (1,0) [0|3] "" Vector__XXX

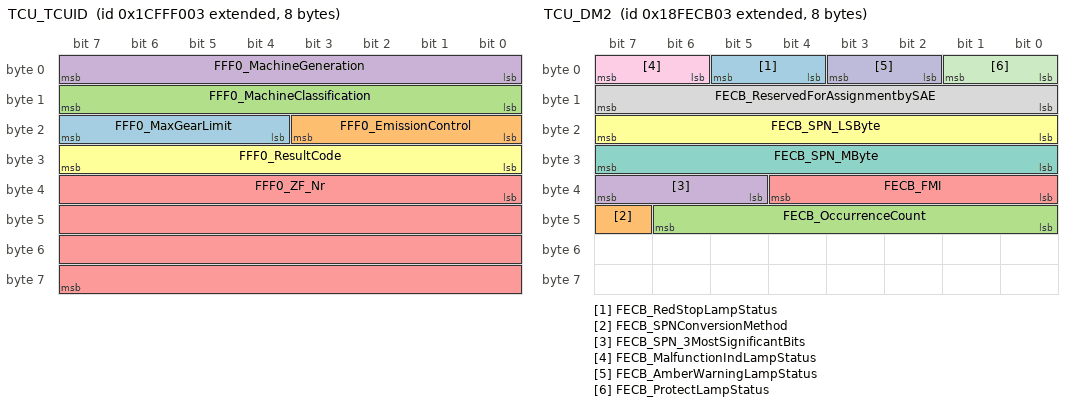
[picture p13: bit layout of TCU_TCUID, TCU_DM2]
BO_ 2634018819 TCU_TCUID: 8 Vector__XXX
 SG_ FFF0_MaxGearLimit : 20|4@1+ (1,0) [0|15] "" Vector__XXX
 SG_ FFF0_EmissionControl : 16|4@1+ (1,0) [0|15] "" Vector__XXX
 SG_ FFF0_MachineClassification : 8|8@1+ (1,0) [0|255] "" Vector__XXX
 SG_ FFF0_MachineGeneration : 0|8@1+ (1,0) [0|255] "" Vector__XXX
 SG_ FFF0_ZF_Nr : 32|32@1+ (1,0) [0|4294967295] "" Vector__XXX
 SG_ FFF0_ResultCode : 24|8@1+ (1,0) [0|20] "" Vector__XXX

BO_ 2566834947 TCU_DM2: 8 Vector__XXX
 SG_ FECB_RedStopLampStatus : 4|2@1+ (1,0) [0|3] "" Vector__XXX
 SG_ FECB_SPNConversionMethod : 47|1@1+ (1,0) [0|1] "" Vector__XXX
 SG_ FECB_OccurrenceCount : 40|7@1+ (1,0) [0|126] "" Vector__XXX
 SG_ FECB_SPN_3MostSignificantBits : 37|3@1+ (1,0) [0|7] "" Vector__XXX
 SG_ FECB_FMI : 32|5@1+ (1,0) [0|31] "" Vector__XXX
 SG_ FECB_SPN_LSByte : 16|8@1+ (1,0) [0|255] "" Vector__XXX
 SG_ FECB_SPN_MByte : 24|8@1+ (1,0) [0|255] "" Vector__XXX
 SG_ FECB_ReservedForAssignmentbySAE : 8|8@1+ (1,0) [0|255] "" Vector__XXX
 SG_ FECB_MalfunctionIndLampStatus : 6|2@1+ (1,0) [0|3] "" Vector__XXX
 SG_ FECB_AmberWarningLampStatus : 2|2@1+ (1,0) [0|3] "" Vector__XXX
 SG_ FECB_ProtectLampStatus : 0|2@1+ (1,0) [0|3] "" Vector__XXX

BO_ 2565808424 GP_SMVCU: 240 Vector__XXX
 SG_ EF21_OptSetting_Trailer : 345|1@1+ (1,0) [0|1] "" Vector__XXX
 SG_ EA21_GSPN : 19|1@1+ (1,0) [0|1] "" Vector__XXX
 SG_ EF21_OptSetting_Beacon : 1519|1@1+ (1,0) [0|1] "" Vector__XXX
 SG_ EF21_OptSetting_ReverseFAN : 1518|1@1+ (1,0) [0|1] "" Vector__XXX
 SG_ EF21_OptSetting_RCW : 1517|1@1+ (1,0) [0|1] "" Vector__XXX
 SG_ EF21_OptSetting_QuickCoupler : 1516|1@1+ (1,0) [0|1] "" Vector__XXX
 SG_ EF21_OptSetting_TravelSwingAlarm : 1515|1@1+ (1,0) [0|1] "" Vector__XXX
 SG_ EF21_OptSetting_SmartKey : 1514|1@1+ (1,0) [0|1] "" Vector__XXX
 SG_ EF21_OptSetting_OWD : 1513|1@1+ (1,0) [0|1] "" Vector__XXX
 SG_ EF21_TiltRotating_Enable : 1512|1@1+ (1,0) [0|1] "" Vector__XXX
 SG_ EF21_BreakerTime_Enable : 1511|1@1+ (1,0) [0|1] "" Vector__XXX
 SG_ EF21_VoiceWarning_Enable : 1510|1@1+ (1,0) [0|1] "" Vector__XXX
 SG_ EF21_EngLockSetState : 1493|1@1+ (1,0) [0|1] "" Vector__XXX
 SG_ EF21_MultiFunctionButtonSelect : 1489|4@1+ (1,0) [0|15] "" Vector__XXX
 SG_ EF21_VehicleSerialNumber : 1369|56@1+ (1,0) [0|7.20575940379279E+016] "" Vector__XXX
 SG_ EF21_OwnerPassword : 1337|32@1+ (1,0) [0|4294967295] "" Vector__XXX
 SG_ EF21_UserPassword : 1305|32@1+ (1,0) [0|4294967295] "" Vector__XXX
 SG_ EF21_AttachData_EngRPM_2way05 : 496|16@1+ (1,0) [0|65535] "" Vector__XXX
 SG_ EF21_AttachData_EngRPM_2way04 : 480|16@1+ (1,0) [0|65535] "" Vector__XXX
 SG_ EF21_AttachData_EngRPM_2way03 : 464|16@1+ (1,0) [0|65535] "" Vector__XXX
 SG_ EF21_AttachData_EngRPM_2way02 : 448|16@1+ (1,0) [0|65535] "" Vector__XXX
 SG_ EF21_AttachData_EngRPM_2way01 : 432|16@1+ (1,0) [0|65535] "" Vector__XXX
 SG_ EF21_AttachData_EngRPM_Breaker05 : 416|16@1+ (1,0) [0|65535] "" Vector__XXX
 SG_ EF21_AttachData_EngRPM_Breaker04 : 400|16@1+ (1,0) [0|65535] "" Vector__XXX
 SG_ EF21_AttachData_EngRPM_Breaker03 : 384|16@1+ (1,0) [0|65535] "" Vector__XXX
 SG_ EF21_AttachData_EngRPM_Breaker02 : 368|16@1+ (1,0) [0|65535] "" Vector__XXX
 SG_ EF21_AttachData_EngRPM_Breaker01 : 352|16@1+ (1,0) [0|65535] "" Vector__XXX
 SG_ EF21_AttachData_2wayButton_05 : 343|2@1+ (1,0) [0|3] "" Vector__XXX
 SG_ EF21_AttachData_2wayButton_04 : 341|2@1+ (1,0) [0|3] "" Vector__XXX
 SG_ EF21_AttachData_2wayButton_03 : 339|2@1+ (1,0) [0|3] "" Vector__XXX
 SG_ EF21_AttachData_2wayButton_02 : 337|2@1+ (1,0) [0|3] "" Vector__XXX
 SG_ EF21_AttachData_2wayButton_01 : 335|2@1+ (1,0) [0|3] "" Vector__XXX
 SG_ EF21_AttachData_BreakerButton_05 : 333|2@1+ (1,0) [0|3] "" Vector__XXX
 SG_ EF21_AttachData_BreakerButton_04 : 331|2@1+ (1,0) [0|3] "" Vector__XXX
 SG_ EF21_AttachData_BreakerButton_03 : 329|2@1+ (1,0) [0|3] "" Vector__XXX
 SG_ EF21_AttachData_BreakerButton_02 : 327|2@1+ (1,0) [0|3] "" Vector__XXX
 SG_ EF21_AttachData_BreakerButton_01 : 325|2@1+ (1,0) [0|3] "" Vector__XXX
 SG_ EF21_SelectedAttachNo_2Way : 317|8@1+ (1,0) [0|255] "" Vector__XXX
 SG_ EF21_SelectedAttachNo_Breaker : 309|8@1+ (1,0) [0|255] "" Vector__XXX
 SG_ EF21_AutoShutOffTimeData : 301|8@1+ (1,0) [0|255] "" Vector__XXX
 SG_ EF21_AutoIldeTimedata : 285|16@1+ (1,0) [0|65535] "" Vector__XXX
 SG_ EF21_BreakerOperationTimedata : 269|16@1+ (1,0) [0|65535] "" Vector__XXX
 SG_ EF21_PeriodData_BOilSepFilter : 253|16@1+ (1,0) [0|65535] "" Vector__XXX
 SG_ EF21_PeriodInfoData_DPFFilter : 237|16@1+ (1,0) [0|65535] "" Vector__XXX
 SG_ EF21_PeriodInfoData_CoolantWater : 221|16@1+ (1,0) [0|65535] "" Vector__XXX
 SG_ EF21_PeriodInfoData_HydOil : 205|16@1+ (1,0) [0|65535] "" Vector__XXX
 SG_ EF21_PeriodInfoData_EngineOil : 189|16@1+ (1,0) [0|65535] "" Vector__XXX
 SG_ EF21_PeriodInfoData_PilotFilter : 173|16@1+ (1,0) [0|65535] "" Vector__XXX
 SG_ EF21_PeriodInfoData_HydOilFilter : 157|16@1+ (1,0) [0|65535] "" Vector__XXX
 SG_ EF21_PeriodInfoData_EngOilFilter : 141|16@1+ (1,0) [0|65535] "" Vector__XXX
 SG_ EF21_PeriodInfoData_AirCleaner : 125|16@1+ (1,0) [0|65535] "" Vector__XXX
 SG_ EF21_PeriodInfoData_FuelFilter : 109|16@1+ (1,0) [0|65535] "" Vector__XXX
 SG_ EF21_ThumbwheelSpeed_Rotating : 107|2@1+ (1,0) [0|3] "" Vector__XXX
 SG_ EF21_ThumbwheelSpeed_2way : 105|2@1+ (1,0) [0|3] "" Vector__XXX
 SG_ EF21_2WayOption_JoyPedal : 103|2@1+ (1,0) [0|3] "" Vector__XXX
 SG_ EF21_Temp_AutoIdleRPM : 102|1@1+ (1,0) [0|1] "" Vector__XXX
 SG_ EF21_VBOEmergModeCMD_JoySensor : 101|1@1+ (1,0) [0|1] "" Vector__XXX
 SG_ EF21_VBOEmergModeCMD_AngleSensor : 100|1@1+ (1,0) [0|1] "" Vector__XXX
 SG_ EF21_SPC : 99|1@1+ (1,0) [0|1] "" Vector__XXX
 SG_ EF21_VoiceWarningCMD : 98|1@1+ (1,0) [0|1] "" Vector__XXX
 SG_ EF21_BoomSwing : 97|1@1+ (1,0) [0|1] "" Vector__XXX
 SG_ EF21_Travel2Pump : 96|1@1+ (1,0) [0|1] "" Vector__XXX
 SG_ EF21_KeypadOpt_RotatingBeaconOpt : 75|1@1+ (1,0) [0|1] "" Vector__XXX
 SG_ EF21_Travel1Pump : 95|1@1+ (1,0) [0|1] "" Vector__XXX
 SG_ EF21_AutoShutOffEnableState : 94|1@1+ (1,0) [0|1] "" Vector__XXX
 SG_ EF21_AutoShutOffCancelCMD : 93|1@1+ (1,0) [0|1] "" Vector__XXX
 SG_ EF21_AutoCalibrationCMD : 92|1@1+ (1,0) [0|1] "" Vector__XXX
 SG_ EF21_AngleSensorCalibrationCMD : 91|1@1+ (1,0) [0|1] "" Vector__XXX
 SG_ EF21_ResetCMD_OperationHour : 90|1@1+ (1,0) [0|1] "" Vector__XXX
 SG_ EF21_ResetCMD_AVMFailureLog : 89|1@1+ (1,0) [0|1] "" Vector__XXX
 SG_ EF21_ResetCMD_EPOSFailureLog : 88|1@1+ (1,0) [0|1] "" Vector__XXX
 SG_ EF21_ResetCMD_BreathOilSepFilter : 87|1@1+ (1,0) [0|1] "" Vector__XXX
 SG_ EF21_ResetCMD_DPFFilter : 86|1@1+ (1,0) [0|1] "" Vector__XXX
 SG_ EF21_ResetCMD_CoolantWater : 85|1@1+ (1,0) [0|1] "" Vector__XXX
 SG_ EF21_ResetCMD_HydOil : 84|1@1+ (1,0) [0|1] "" Vector__XXX
 SG_ EF21_ResetCMD_EngineOil : 83|1@1+ (1,0) [0|1] "" Vector__XXX
 SG_ EF21_ResetCMD_PilotFilter : 82|1@1+ (1,0) [0|1] "" Vector__XXX
 SG_ EF21_ResetCMD_HydOilFilter : 81|1@1+ (1,0) [0|1] "" Vector__XXX
 SG_ EF21_ResetCMD_EngineOilFilter : 80|1@1+ (1,0) [0|1] "" Vector__XXX
 SG_ EF21_ResetCMD_AirCleaner : 79|1@1+ (1,0) [0|1] "" Vector__XXX
 SG_ EF21_ResetCMD_FuelFilter : 78|1@1+ (1,0) [0|1] "" Vector__XXX
 SG_ EF21_KeypadOpt_BoomSwingOption : 77|1@1+ (1,0) [0|1] "" Vector__XXX
 SG_ EF21_KeypadOpt_OWDOption : 76|1@1+ (1,0) [0|1] "" Vector__XXX
 SG_ EF21_KeypadOpt_AirCompOption : 74|1@1+ (1,0) [0|1] "" Vector__XXX
 SG_ EF21_KeypadOpt_AlarmOption : 73|1@1+ (1,0) [0|1] "" Vector__XXX
 SG_ EF21_OptionPedal : 72|1@1+ (1,0) [0|1] "" Vector__XXX
 SG_ EF21_HighLand : 71|1@1+ (1,0) [0|1] "" Vector__XXX
 SG_ EF21_Ripper : 70|1@1+ (1,0) [0|1] "" Vector__XXX
 SG_ EF21_Rotating : 69|1@1+ (1,0) [0|1] "" Vector__XXX
 SG_ EF21_AttchOpt_Joystick : 68|1@1+ (1,0) [0|1] "" Vector__XXX
 SG_ EF21_AttchOpt_Pedal : 67|1@1+ (1,0) [0|1] "" Vector__XXX
 SG_ EF21_AttchOpt_2Pump : 66|1@1+ (1,0) [0|1] "" Vector__XXX
 SG_ EF21_AttchOpt_TwoWay : 65|1@1+ (1,0) [0|1] "" Vector__XXX
 SG_ EF21_AttchOpt_Breaker : 64|1@1+ (1,0) [0|1] "" Vector__XXX
 SG_ EF21_VCUDataField : 24|32@1+ (1,0) [0|4294967295] "" Vector__XXX
 SG_ EF21_SuspectParameterNumber : 0|19@1+ (1,0) [0|524287] "" Vector__XXX

BO_ 2565865761 VCU_EBC1: 8 Vector__XXX
 SG_ ASREngineControlActive : 0|2@1+ (1,0) [0|3] "" Vector__XXX
 SG_ ASRBrakeControlActive : 2|2@1+ (1,0) [0|3] "" Vector__XXX
 SG_ AntiLockBrakingActive : 4|2@1+ (1,0) [0|3] "" Vector__XXX
 SG_ EBSBrakeSwitch : 6|2@1+ (1,0) [0|3] "" Vector__XXX
 SG_ BrakePedalPosition : 8|8@1+ (0.4,0) [0|100] "%" Vector__XXX
 SG_ ABSOffRoadSwitch : 16|2@1+ (1,0) [0|3] "" Vector__XXX
 SG_ ASROffRoadSwitch : 18|2@1+ (1,0) [0|3] "" Vector__XXX
 SG_ ASRHillHolderSwitch : 20|2@1+ (1,0) [0|3] "" Vector__XXX
 SG_ TractionControlOverrideSwitch : 22|2@1+ (1,0) [0|3] "" Vector__XXX
 SG_ AcceleratorInterlockSwitch : 24|2@1+ (1,0) [0|3] "" Vector__XXX
 SG_ EngineDerateSwitch : 26|2@1+ (1,0) [0|3] "" Vector__XXX
 SG_ EngineAuxiliaryShutdownSwitch : 28|2@1+ (1,0) [0|3] "" Vector__XXX
 SG_ RemoteAcceleratorEnableSwitch : 30|2@1+ (1,0) [0|3] "" Vector__XXX
 SG_ EngineRetarderSelection : 32|8@1+ (0.4,0) [0|100] "%" Vector__XXX
 SG_ ABSFullyOperational : 40|2@1+ (1,0) [0|3] "" Vector__XXX
 SG_ EBSRedWarningSignal : 42|2@1+ (1,0) [0|3] "" Vector__XXX
 SG_ ABSEBSAmberWarningSignal : 44|2@1+ (1,0) [0|3] "" Vector__XXX
 SG_ ATCASRInformationSignal : 46|2@1+ (1,0) [0|3] "" Vector__XXX
 SG_ SrcAddrOfCtrllingDevForBrkCtrl : 48|8@1+ (1,0) [0|255] "" Vector__XXX
 SG_ RailroadModeSwitch : 56|2@1+ (1,0) [0|3] "" Vector__XXX
 SG_ HaltBrakeSwitch : 58|2@1+ (1,0) [0|3] "" Vector__XXX
 SG_ TrailerABSStatus : 60|2@1+ (1,0) [0|3] "" Vector__XXX
 SG_ TractorMntdTrailerABSWarningSig : 62|2@1+ (1,0) [0|3] "" Vector__XXX

BO_ 2365543713 VCU_KeypadA_Indicate2: 8 Vector__XXX
 SG_ FF55_TrsmModeSelectRight : 36|2@1+ (1,0) [0|3] "" Vector__XXX
 SG_ FF55_TrsmModeSelectLeft : 40|2@1+ (1,0) [0|3] "" Vector__XXX
 SG_ FF55_TrsmModeSelectCenter : 38|2@1+ (1,0) [0|3] "" Vector__XXX
 SG_ FF55_TorqueConverterLockUpRight : 48|2@1+ (1,0) [0|3] "" Vector__XXX
 SG_ FF55_TorqueConverterLockUpLeft : 52|2@1+ (1,0) [0|3] "" Vector__XXX
 SG_ FF55_TorqueConverterLockUpCenter : 50|2@1+ (1,0) [0|3] "" Vector__XXX
 SG_ FF55_ClutchCutOffRight : 42|2@1+ (1,0) [0|3] "" Vector__XXX
 SG_ FF55_ClutchCutOffLeft : 46|2@1+ (1,0) [0|3] "" Vector__XXX
 SG_ FF55_ClutchCutOffCenter : 44|2@1+ (1,0) [0|3] "" Vector__XXX
 SG_ FF55_MaxSpeedDownLeft : 34|2@1+ (1,0) [0|3] "" Vector__XXX
 SG_ FF55_MaxSpeedDownCenter : 32|2@1+ (1,0) [0|3] "" Vector__XXX
 SG_ FF55_MaxSpeedDownRight : 30|2@1+ (1,0) [0|3] "" Vector__XXX
 SG_ FF55_MaxSpeedUpLeft : 28|2@1+ (1,0) [0|3] "" Vector__XXX
 SG_ FF55_MaxSpeedUpCenter : 26|2@1+ (1,0) [0|3] "" Vector__XXX
 SG_ FF55_MaxSpeedUpRight : 24|2@1+ (1,0) [0|3] "" Vector__XXX
 SG_ FF55_BucketDetentLeft : 22|2@1+ (1,0) [0|3] "" Vector__XXX
 SG_ FF55_BucketDetentCenter : 20|2@1+ (1,0) [0|3] "" Vector__XXX
 SG_ FF55_BucketDetentRight : 18|2@1+ (1,0) [0|3] "" Vector__XXX
 SG_ FF55_BoomDetentLeft : 16|2@1+ (1,0) [0|3] "" Vector__XXX
 SG_ FF55_BoomDetentCenter : 14|2@1+ (1,0) [0|3] "" Vector__XXX
 SG_ FF55_BoomDetentRight : 12|2@1+ (1,0) [0|3] "" Vector__XXX
 SG_ FF55_DiffLockEngagedLeft : 10|2@1+ (1,0) [0|3] "" Vector__XXX
 SG_ FF55_DiffLockEngagedCenter : 8|2@1+ (1,0) [0|3] "" Vector__XXX
 SG_ FF55_DiffLockEngagedRight : 6|2@1+ (1,0) [0|3] "" Vector__XXX
 SG_ FF55_ModeSelectLeft : 4|2@1+ (1,0) [0|3] "" Vector__XXX
 SG_ FF55_ModeSelectCenter : 2|2@1+ (1,0) [0|3] "" Vector__XXX
 SG_ FF55_ModeSelectRight : 0|2@1+ (1,0) [0|3] "" Vector__XXX

BO_ 2365543504 KeypadA_OperateSignal_E25: 8 Vector__XXX
 SG_ FF54_Keypad_881_TrackExpansion : 63|1@1+ (1,0) [0|1] "" Vector__XXX
 SG_ FF54_Keypad_871_InterlockOver : 62|1@1+ (1,0) [0|1] "" Vector__XXX
 SG_ FF54_Keypad_861_AUX8 : 61|1@1+ (1,0) [0|1] "" Vector__XXX
 SG_ FF54_Keypad_851_AUX7 : 60|1@1+ (1,0) [0|1] "" Vector__XXX
 SG_ FF54_Keypad_841_Continousflow : 59|1@1+ (1,0) [0|1] "" Vector__XXX
 SG_ FF54_Keypad_831_ReverseFAN : 58|1@1+ (1,0) [0|1] "" Vector__XXX
 SG_ FF54_Keypad_821_SelfLevel : 57|1@1+ (1,0) [0|1] "" Vector__XXX
 SG_ FF54_Keypad_811_Reserved : 56|1@1+ (1,0) [0|1] "" Vector__XXX
 SG_ FF54_Keypad_711_RearMirroHeat : 48|1@1+ (1,0) [0|1] "" Vector__XXX
 SG_ FF54_Keypad_781_Up : 55|1@1+ (1,0) [0|1] "" Vector__XXX
 SG_ FF54_Keypad_771_Down : 54|1@1+ (1,0) [0|1] "" Vector__XXX
 SG_ FF54_Enter_Signal : 53|1@1+ (1,0) [0|1] "" Vector__XXX
 SG_ FF54_Menu_Signal : 52|1@1+ (1,0) [0|1] "" Vector__XXX
 SG_ FF54_AirCompSig : 42|1@1+ (1,0) [0|1] "" Vector__XXX
 SG_ FF54_TractionOperation_sig : 28|1@1+ (1,0) [0|1] "" Vector__XXX
 SG_ FF54_Keypad_Front_Wiper : 47|1@1+ (1,0) [0|1] "" Vector__XXX
 SG_ FF54_Keypad_Rear_Wiper : 46|1@1+ (1,0) [0|1] "" Vector__XXX
 SG_ FF54_Keypad_Side_Wiper : 45|1@1+ (1,0) [0|1] "" Vector__XXX
 SG_ FF54_Keypad_Front_WiperWasher : 44|1@1+ (1,0) [0|1] "" Vector__XXX
 SG_ FF54_Keypad_Side_WiperWasher : 43|1@1+ (1,0) [0|1] "" Vector__XXX
 SG_ FF54_Keypad_TravelSpeedSig : 41|1@1+ (1,0) [0|1] "" Vector__XXX
 SG_ FF54_Keypad_AutoidleSig : 40|1@1+ (1,0) [0|1] "" Vector__XXX
 SG_ FF54_AudioSwitchSignal : 50|1@1+ (1,0) [0|1] "" Vector__XXX
 SG_ FF54_CallSwitchSignal : 49|1@1+ (1,0) [0|1] "" Vector__XXX
 SG_ FF54_BuzzerStopSignal : 51|1@1+ (1,0) [0|1] "" Vector__XXX
 SG_ FF54_Keypad_crab_round_select : 39|1@1+ (1,0) [0|1] "" Vector__XXX
 SG_ FF54_Keypad_4wheel_2wheel_select : 38|1@1+ (1,0) [0|1] "" Vector__XXX
 SG_ FF54_Keypad_Outrigger_RR : 26|1@1+ (1,0) [0|1] "" Vector__XXX
 SG_ FF54_Keypad_Outrigger_RL : 25|1@1+ (1,0) [0|1] "" Vector__XXX
 SG_ FF54_Keypad_Outrigger_FR : 24|1@1+ (1,0) [0|1] "" Vector__XXX
 SG_ FF54_Keypad_Outrigger_ALL : 27|1@1+ (1,0) [0|1] "" Vector__XXX
 SG_ FF54_Keypad_Outrigger_FL : 23|1@1+ (1,0) [0|1] "" Vector__XXX
 SG_ FF54_Keypad_Workmode : 10|1@1+ (1,0) [0|1] "" Vector__XXX
 SG_ FF54_Keypad_TravelAlarm : 8|1@1+ (1,0) [0|1] "" Vector__XXX
 SG_ FF54_Keypad_TrailerHitch : 13|1@1+ (1,0) [0|1] "" Vector__XXX
 SG_ FF54_Keypad_Powermode : 9|1@1+ (1,0) [0|1] "" Vector__XXX
 SG_ FF54_Keypad_JoystickSteering : 15|1@1+ (1,0) [0|1] "" Vector__XXX
 SG_ FF54_Keypad_Fineswing : 14|1@1+ (1,0) [0|1] "" Vector__XXX
 SG_ FF54_Keypad_BoomSwing : 11|1@1+ (1,0) [0|1] "" Vector__XXX
 SG_ FF54_Keypad_ADB : 12|1@1+ (1,0) [0|1] "" Vector__XXX
 SG_ FF54_Keypad_OWD : 5|1@1+ (1,0) [0|1] "" Vector__XXX
 SG_ FF54_Keypad_BoomLamp : 4|1@1+ (1,0) [0|1] "" Vector__XXX
 SG_ FF54_ThrottleLockUp : 37|1@1+ (1,0) [0|1] "" Vector__XXX
 SG_ FF54_TractionControlMode : 36|1@1+ (1,0) [0|1] "" Vector__XXX
 SG_ FF54_VariableSpeedDown : 35|1@1+ (1,0) [0|1] "" Vector__XXX
 SG_ FF54_VariableSpeedUp : 34|1@1+ (1,0) [0|1] "" Vector__XXX
 SG_ FF54_TrsmModeSelect : 29|1@1+ (1,0) [0|1] "" Vector__XXX
 SG_ FF54_TorqueConverterLockUp : 31|1@1+ (1,0) [0|1] "" Vector__XXX
 SG_ FF54_ClutchCutOff : 30|1@1+ (1,0) [0|1] "" Vector__XXX
 SG_ FF54_RearWorkingLamp : 2|1@1+ (1,0) [0|1] "" Vector__XXX
 SG_ FF54_RearWiperAndWasher : 6|1@1+ (1,0) [0|1] "" Vector__XXX
 SG_ FF54_ModeSelect : 17|1@1+ (1,0) [0|1] "" Vector__XXX
 SG_ FF54_MirrorHeat : 7|1@1+ (1,0) [0|1] "" Vector__XXX
 SG_ FF54_MenuHelp : 16|1@1+ (1,0) [0|1] "" Vector__XXX
 SG_ FF54_MaxSpeedUp : 33|1@1+ (1,0) [0|1] "" Vector__XXX
 SG_ FF54_MaxSpeedDown : 32|1@1+ (1,0) [0|1] "" Vector__XXX
 SG_ FF54_LoadIsolation : 18|1@1+ (1,0) [0|1] "" Vector__XXX
 SG_ FF54_BoomFloating : 0|1@1+ (1,0) [0|1] "" Vector__XXX
 SG_ FF54_SwingLock : 1|1@1+ (1,0) [0|1] "" Vector__XXX
 SG_ FF54_EmergencySteering : 21|1@1+ (1,0) [0|1] "" Vector__XXX
 SG_ FF54_DifferentialLockEngaged : 22|1@1+ (1,0) [0|1] "" Vector__XXX
 SG_ FF54_BucketDetent : 20|1@1+ (1,0) [0|1] "" Vector__XXX
 SG_ FF54_BoomDetent : 19|1@1+ (1,0) [0|1] "" Vector__XXX
 SG_ FF54_BeaconLamp : 3|1@1+ (1,0) [0|1] "" Vector__XXX

BO_ 2566902049 VCU_FSDI: 105 Vector__XXX
 SG_ FFD1_CondenserRevFan_Auto_Period : 744|8@1+ (1,0) [0|255] "" Vector__XXX
 SG_ FFD1_CondenserReverseFanMode : 732|1@1+ (1,0) [0|1] "" Vector__XXX
 SG_ FFD1_SetAdvanceLeveling : 730|1@1+ (1,0) [0|1] "" Vector__XXX
 SG_ FFD1_OptSetGroundSaw : 729|1@1+ (1,0) [0|1] "" Vector__XXX
 SG_ FFD1_Set_TPMS : 728|1@1+ (1,0) [0|1] "" Vector__XXX
 SG_ FFD1_OptnSettingTrailer : 742|1@1+ (1,0) [0|1] "" Vector__XXX
 SG_ FFD1_SettingEscortWorkingLamp : 741|1@1+ (1,0) [0|1] "" Vector__XXX
 SG_ FFD1_Rotat_ThumbWheelDirecSet : 731|1@1+ (1,0) [0|1] "" Vector__XXX
 SG_ FFD1_Opt_Wiper : 189|1@1+ (1,0) [0|1] "" Vector__XXX
 SG_ FFD1_Opt_TransparentBucket : 399|1@1+ (1,0) [0|1] "" Vector__XXX
 SG_ FFD1_Opt_InteligentFloatingBoom : 398|1@1+ (1,0) [0|1] "" Vector__XXX
 SG_ FFD1_Opt_EngineAirheater : 61|1@1+ (1,0) [0|1] "" Vector__XXX
 SG_ FFD1_Opt_2DMG : 60|1@1+ (1,0) [0|1] "" Vector__XXX
 SG_ FFD1_Set_Joytick_Tilt : 715|2@1+ (1,0) [0|3] "" Vector__XXX
 SG_ FFD1_Set_Joytick_Boom : 717|2@1+ (1,0) [0|3] "" Vector__XXX
 SG_ FFD1_CMD_AntiBlankFireActivate : 719|1@1+ (1,0) [0|1] "" Vector__XXX
 SG_ FFD1_ReverseFanDurationTimeData : 709|6@1+ (1,0) [0|63] "" Vector__XXX
 SG_ FFD1_Opt_HighFlow : 708|1@1+ (1,0) [0|1] "" Vector__XXX
 SG_ FFD1_Opt_3rdParty3DMGMC : 704|4@1+ (1,0) [0|15] "" Vector__XXX
 SG_ FFD1_RearCabinLamp : 703|1@1+ (1,0) [0|1] "" Vector__XXX
 SG_ FFD1_TorqueConverterLockUp : 699|1@1+ (1,0) [0|1] "" Vector__XXX
 SG_ FFD1_DozingMC : 700|3@1+ (1,0) [0|7] "" Vector__XXX
 SG_ FFD1_Opt_DAAC : 671|1@1+ (1,0) [0|1] "" Vector__XXX
 SG_ FFD1_2wayThumbWheelDirectionSet : 698|1@1+ (1,0) [0|1] "" Vector__XXX
 SG_ FFD1_PedalOpt2 : 696|2@1+ (1,0) [0|3] "" Vector__XXX
 SG_ FFD1_MaxTravelSpeedSet : 688|8@1+ (1,0) [0|255] "" Vector__XXX
 SG_ FFD1_KeylessUse : 191|1@1+ (1,0) [0|1] "" Vector__XXX
 SG_ FFD1_Option_TLMotorOverheat : 188|1@1+ (1,0) [0|1] "" Vector__XXX
 SG_ FFD1_Option_Keyless : 190|1@1+ (1,0) [0|1] "" Vector__XXX
 SG_ FFD1_Option_FNRControlSelect : 186|1@1+ (1,0) [0|1] "" Vector__XXX
 SG_ FFD1_Option_FNRControlDefault : 187|1@1+ (1,0) [0|1] "" Vector__XXX
 SG_ FFD1_Option_CANtypeCombiSW : 185|1@1+ (1,0) [0|1] "" Vector__XXX
 SG_ FFD1_SetTiltRotatorType : 635|3@1+ (1,0) [0|7] "" Vector__XXX
 SG_ FFD1_SetQuickCollingMode : 646|1@1+ (1,0) [0|1] "" Vector__XXX
 SG_ FFD1_SetJoystickType : 640|3@1+ (1,0) [0|7] "" Vector__XXX
 SG_ FFD1_OptSetTravelStraightPedal : 643|1@1+ (1,0) [0|1] "" Vector__XXX
 SG_ FFD1_OptSetRotating : 638|2@1+ (1,0) [0|3] "" Vector__XXX
 SG_ FFD1_OptSetPedalJoystickRotating : 644|2@1+ (1,0) [0|3] "" Vector__XXX
 SG_ FFD1_OptSetMirrorHeater : 647|1@1+ (1,0) [0|1] "" Vector__XXX
 SG_ FFD1_TravelSpeedSet : 600|3@1+ (1,0) [0|7] "" Vector__XXX
 SG_ FFD1_OptSetDozerBlade : 633|1@1+ (1,0) [0|1] "" Vector__XXX
 SG_ FFD1_TorqueConvertorLockUpSet : 628|1@1+ (1,0) [0|1] "" Vector__XXX
 SG_ FFD1_OptSetJoystickPatternChange : 629|3@1+ (1,0) [0|7] "" Vector__XXX
 SG_ FFD1_OptSetHighLift : 632|1@1+ (1,0) [0|1] "" Vector__XXX
 SG_ FFD1_OptSetArtiBoom : 634|1@1+ (1,0) [0|1] "" Vector__XXX
 SG_ FFD1_DHLAutoSetting : 627|1@1+ (1,0) [0|1] "" Vector__XXX
 SG_ FFD1_TravelSpeedPreset4Reverse : 624|3@1+ (1,0) [0|7] "" Vector__XXX
 SG_ FFD1_TravelSpeedPreset4Forward : 621|3@1+ (1,0) [0|7] "" Vector__XXX
 SG_ FFD1_TravelSpeedPreset3Reverse : 618|3@1+ (1,0) [0|7] "" Vector__XXX
 SG_ FFD1_TravelSpeedPreset3Forward : 615|3@1+ (1,0) [0|7] "" Vector__XXX
 SG_ FFD1_TravelSpeedPreset2Reverse : 612|3@1+ (1,0) [0|7] "" Vector__XXX
 SG_ FFD1_TravelSpeedPreset2Forward : 609|3@1+ (1,0) [0|7] "" Vector__XXX
 SG_ FFD1_TravelSpeedPreset1Reverse : 606|3@1+ (1,0) [0|7] "" Vector__XXX
 SG_ FFD1_TravelSpeedPreset1Forward : 603|3@1+ (1,0) [0|7] "" Vector__XXX
 SG_ FFD1_OptionSetRollover : 599|1@1+ (1,0) [0|1] "" Vector__XXX
 SG_ FFD1_OptionSet4thSpool : 597|1@1+ (1,0) [0|1] "" Vector__XXX
 SG_ FFD1_LISReverseOperationVelocity : 584|8@1+ (1,0) [0|255] "" Vector__XXX
 SG_ FFD1_ConstantFlowStep : 592|4@1+ (1,0) [0|15] "" Vector__XXX
 SG_ FFD1_ConstantFlowSetting : 596|1@1+ (1,0) [0|1] "" Vector__XXX
 SG_ FFD1_ReverseSpeedLimit : 577|1@1+ (1,0) [0|1] "" Vector__XXX
 SG_ FFD1_OptionSetCabinLamp : 583|1@1+ (1,0) [0|1] "" Vector__XXX
 SG_ FFD1_ESteeringSetting : 578|1@1+ (1,0) [0|1] "" Vector__XXX
 SG_ FFD1_WorkingLISSet : 568|1@1+ (1,0) [0|1] "" Vector__XXX
 SG_ FFD1_ESteeringHoystickSen : 569|2@1+ (1,0) [0|3] "" Vector__XXX
 SG_ FFD1_eMCVOptBucketSensitivity : 572|1@1+ (1,0) [0|1] "" Vector__XXX
 SG_ FFD1_eMCVOptBucketDumpProtect : 574|1@1+ (1,0) [0|1] "" Vector__XXX
 SG_ FFD1_eMCVOptBucketCloudProt : 573|1@1+ (1,0) [0|1] "" Vector__XXX
 SG_ FFD1_eMCVOptBoomUpProtect : 575|1@1+ (1,0) [0|1] "" Vector__XXX
 SG_ FFD1_eMCVOptBoomSensitivity : 571|1@1+ (1,0) [0|1] "" Vector__XXX
 SG_ FFD1_eMCVOptBoomDownProtect : 576|1@1+ (1,0) [0|1] "" Vector__XXX
 SG_ FFD1_R2InputValue : 536|16@1+ (1,0) [0|65535] "" Vector__XXX
 SG_ FFD1_R1InputValue : 520|16@1+ (1,0) [0|65535] "" Vector__XXX
 SG_ FFD1_LCInputValue : 552|16@1+ (1,0) [0|65535] "" Vector__XXX
 SG_ FFD1_OptionSetReverseFan : 454|1@1+ (1,0) [0|1] "" Vector__XXX
 SG_ FFD1_MaxCriterionWeightValue : 472|16@1+ (1,0) [0|65535] "" Vector__XXX
 SG_ FFD1_HalfCriterionWeightValue : 456|16@1+ (1,0) [0|65535] "" Vector__XXX
 SG_ FFD1_BucketWeightInputValue : 504|16@1+ (1,0) [0|65535] "" Vector__XXX
 SG_ FFD1_BoomWeightInputValue : 488|16@1+ (1,0) [0|65535] "" Vector__XXX
 SG_ FFD1_OptionsetTravelSwingAlarm : 451|1@1+ (1,0) [0|1] "" Vector__XXX
 SG_ FFD1_OptionsetRCW : 453|1@1+ (1,0) [0|1] "" Vector__XXX
 SG_ FFD1_OptionsetQuickCoupler : 452|1@1+ (1,0) [0|1] "" Vector__XXX
 SG_ FFD1_OptionsetElecSteering : 455|1@1+ (1,0) [0|1] "" Vector__XXX
 SG_ FFD1_OptionsetSmartkey : 450|1@1+ (1,0) [0|1] "" Vector__XXX
 SG_ FFD1_OptionsetOWD : 449|1@1+ (1,0) [0|1] "" Vector__XXX
 SG_ FFD1_MachineNameInitializing : 448|1@1+ (1,0) [0|1] "" Vector__XXX
 SG_ FFD1_outrigger_RR : 582|1@1+ (1,0) [0|1] "" Vector__XXX
 SG_ FFD1_outrigger_FR : 580|1@1+ (1,0) [0|1] "" Vector__XXX
 SG_ FFD1_outrigger_FL_Front : 579|1@1+ (1,0) [0|1] "" Vector__XXX
 SG_ FFD1_TM_MaxSpeedLimit : 255|1@1+ (1,0) [0|1] "" Vector__XXX
 SG_ FFD1_SetRollSlope : 672|16@1+ (1,0) [0|65535] "" Vector__XXX
 SG_ FFD1_ReserveLampFuncActivation : 670|1@1+ (1,0) [0|1] "" Vector__XXX
 SG_ FFD1_BladeTiltSensitivity : 664|2@1+ (1,0) [0|3] "" Vector__XXX
 SG_ FFD1_BladeRaiseDownSensitivity : 666|2@1+ (1,0) [0|3] "" Vector__XXX
 SG_ FFD1_BladeAngleSensitivity : 668|2@1+ (1,0) [0|3] "" Vector__XXX
 SG_ FFD1_SetPitchSlpoe : 648|16@1+ (1,0) [0|65535] "" Vector__XXX
 SG_ FFD1_VehicleSerialNumber : 120|56@1+ (1,0) [0|7.20575940379279E+016] "" Vector__XXX
 SG_ FFD1_TiltRotatorMode : 97|1@1+ (1,0) [0|1] "" Vector__XXX
 SG_ FFD1_CHMSL : 98|1@1+ (1,0) [0|1] "" Vector__XXX
 SG_ FFD1_CANTypeFuelSensor : 99|1@1+ (1,0) [0|1] "" Vector__XXX
 SG_ FFD1_AttachmentWeighingFactor : 100|4@1+ (1,0) [0|15] "" Vector__XXX
 SG_ FFD1_Weighing_Option : 63|1@1+ (1,0) [0|1] "" Vector__XXX
 SG_ FFD1_MC_Option : 62|1@1+ (1,0) [0|1] "" Vector__XXX
 SG_ FFD1_OptnSetting_4wheel : 598|1@1+ (1,0) [0|1] "" Vector__XXX
 SG_ FFD1_outrigger_RL_Rear : 581|1@1+ (1,0) [0|1] "" Vector__XXX
 SG_ FFD1_TrsmLimitGear : 400|3@1+ (1,0) [0|7] "" Vector__XXX
 SG_ FFD1_ReverseFanTimeData : 408|8@1+ (1,0) [0|255] "" Vector__XXX
 SG_ FFD1_ReverseFanMocdSetting : 444|1@1+ (1,0) [0|1] "" Vector__XXX
 SG_ FFD1_ReverseFanActivation : 445|1@1+ (1,0) [0|1] "" Vector__XXX
 SG_ FFD1_OptnSettingWeighing : 443|1@1+ (1,0) [0|1] "" Vector__XXX
 SG_ FFD1_OptnSettingThumbWheel : 438|1@1+ (1,0) [0|1] "" Vector__XXX
 SG_ FFD1_OptnSettingMCVType : 447|1@1+ (1,0) [0|1] "" Vector__XXX
 SG_ FFD1_OptnSettingLIS : 407|1@1+ (1,0) [0|1] "" Vector__XXX
 SG_ FFD1_OptnSettingEmrgcySteering : 406|1@1+ (1,0) [0|1] "" Vector__XXX
 SG_ FFD1_OptnSettingDHL : 405|1@1+ (1,0) [0|1] "" Vector__XXX
 SG_ FFD1_OptnSettingBeacon : 397|1@1+ (1,0) [0|1] "" Vector__XXX
 SG_ FFD1_OptnSettingAxleOilCooler : 437|1@1+ (1,0) [0|1] "" Vector__XXX
 SG_ FFD1_MultiFunctionButtonSelect : 393|4@1+ (1,0) [0|15] "" Vector__XXX
 SG_ FFD1_MachineName_11 : 384|8@1+ (1,0) [0|255] "" Vector__XXX
 SG_ FFD1_MachineName_10 : 376|8@1+ (1,0) [0|255] "" Vector__XXX
 SG_ FFD1_MachineName_09 : 368|8@1+ (1,0) [0|255] "" Vector__XXX
 SG_ FFD1_MachineName_08 : 360|8@1+ (1,0) [0|255] "" Vector__XXX
 SG_ FFD1_MachineName_07 : 352|8@1+ (1,0) [0|255] "" Vector__XXX
 SG_ FFD1_MachineName_06 : 344|8@1+ (1,0) [0|255] "" Vector__XXX
 SG_ FFD1_MachineName_05 : 336|8@1+ (1,0) [0|255] "" Vector__XXX
 SG_ FFD1_MachineName_04 : 328|8@1+ (1,0) [0|255] "" Vector__XXX
 SG_ FFD1_MachineName_03 : 320|8@1+ (1,0) [0|255] "" Vector__XXX
 SG_ FFD1_MachineName_02 : 312|8@1+ (1,0) [0|255] "" Vector__XXX
 SG_ FFD1_MachineName_01 : 304|8@1+ (1,0) [0|255] "" Vector__XXX
 SG_ FFD1_LISVelocity : 416|8@1+ (1,0) [0|255] "" Vector__XXX
 SG_ FFD1_HydrostatCalCmd : 442|1@1+ (1,0) [0|1] "" Vector__XXX
 SG_ FFD1_EmrgyModeActivation : 440|1@1+ (1,0) [0|1] "" Vector__XXX
 SG_ FFD1_CreepGear : 424|8@1+ (1,0) [0|255] "" Vector__XXX
 SG_ FFD1_CreepActivation : 439|1@1+ (1,0) [0|1] "" Vector__XXX
 SG_ FFD1_ClutchCalCmd : 441|1@1+ (1,0) [0|1] "" Vector__XXX
 SG_ FFD1_BrakeCalibrationSetting : 432|2@1+ (1,0) [0|3] "" Vector__XXX
 SG_ FFD1_AutoIdleFunctionActivation : 392|1@1+ (1,0) [0|1] "" Vector__XXX
 SG_ FFD1_AngleSensorTuning : 434|3@1+ (1,0) [0|7] "" Vector__XXX
 SG_ FFD1_AEBRequest : 446|1@1+ (1,0) [0|1] "" Vector__XXX
 SG_ FFD1_2ndFNRLeverType : 403|2@1+ (1,0) [0|3] "" Vector__XXX
 SG_ FFD1_UserPassword_3 : 88|8@1+ (1,0) [0|255] "" Vector__XXX
 SG_ FFD1_UserPassword_2 : 80|8@1+ (1,0) [0|255] "" Vector__XXX
 SG_ FFD1_UserPassword_1 : 72|8@1+ (1,0) [0|255] "" Vector__XXX
 SG_ FFD1_UserPassword_0 : 64|8@1+ (1,0) [0|255] "" Vector__XXX
 SG_ FFD1_UserLockState : 96|1@1+ (1,0) [0|1] "" Vector__XXX
 SG_ FFD1_UserDataIndex_0 : 176|8@1+ (1,0) [0|255] "" Vector__XXX
 SG_ FFD1_TempAutoIdleRPMChange : 261|1@1+ (1,0) [0|1] "" Vector__XXX
 SG_ FFD1_SPCSet : 260|1@1+ (1,0) [0|1] "" Vector__XXX
 SG_ FFD1_RotatingOpt : 252|1@1+ (1,0) [0|1] "" Vector__XXX
 SG_ FFD1_RipperOpt : 253|1@1+ (1,0) [0|1] "" Vector__XXX
 SG_ FFD1_PedalOpt : 245|1@1+ (1,0) [0|1] "" Vector__XXX
 SG_ FFD1_OwnerPassword_UserEnable : 32|1@1+ (1,0) [0|1] "" Vector__XXX
 SG_ FFD1_OwnerPassword_MenuApply3 : 56|3@1+ (1,0) [0|7] "" Vector__XXX
 SG_ FFD1_OwnerPassword_MenuApply2 : 48|3@1+ (1,0) [0|7] "" Vector__XXX
 SG_ FFD1_OwnerPassword_MenuApply : 40|3@1+ (1,0) [0|7] "" Vector__XXX
 SG_ FFD1_OwnerPassword_LockDuration : 33|2@1+ (1,0) [0|3] "" Vector__XXX
 SG_ FFD1_OwnerPassword_3 : 24|8@1+ (1,0) [0|255] "" Vector__XXX
 SG_ FFD1_OwnerPassword_2 : 16|8@1+ (1,0) [0|255] "" Vector__XXX
 SG_ FFD1_OwnerPassword_1 : 8|8@1+ (1,0) [0|255] "" Vector__XXX
 SG_ FFD1_OwnerPassword_0 : 0|8@1+ (1,0) [0|255] "" Vector__XXX
 SG_ FFD1_OutSoundWarningCMD : 259|1@1+ (1,0) [0|1] "" Vector__XXX
 SG_ FFD1_JoystickThumbWheel_Rotate : 250|2@1+ (1,0) [0|3] "" Vector__XXX
 SG_ FFD1_JoystickThumbWheel_2Way : 248|2@1+ (1,0) [0|3] "" Vector__XXX
 SG_ FFD1_HighLandOpt : 254|1@1+ (1,0) [0|1] "" Vector__XXX
 SG_ FFD1_Drive2Pump : 257|1@1+ (1,0) [0|1] "" Vector__XXX
 SG_ FFD1_Drive1Pump : 256|1@1+ (1,0) [0|1] "" Vector__XXX
 SG_ FFD1_BreakerOperationTimeData : 272|16@1+ (1,0) [0|65535] "s" Vector__XXX
 SG_ FFD1_BoomSwing : 258|1@1+ (1,0) [0|1] "" Vector__XXX
 SG_ FFD1_AutoShutOffTimeData : 264|8@1+ (1,0) [0|255] "min" Vector__XXX
 SG_ FFD1_AutoShutOffEnableState : 263|1@1+ (1,0) [0|1] "" Vector__XXX
 SG_ FFD1_AutoShutOffCancelCMD : 262|1@1+ (1,0) [0|1] "" Vector__XXX
 SG_ FFD1_AutoIdleTimeData : 288|16@1+ (1,0) [0|65535] "s" Vector__XXX
 SG_ FFD1_AttatchOpt_Twoway : 241|1@1+ (1,0) [0|1] "" Vector__XXX
 SG_ FFD1_AttatchOpt_Pedal : 243|1@1+ (1,0) [0|1] "" Vector__XXX
 SG_ FFD1_AttatchOpt_Joystick : 244|1@1+ (1,0) [0|1] "" Vector__XXX
 SG_ FFD1_AttatchOpt_Breaker : 240|1@1+ (1,0) [0|1] "" Vector__XXX
 SG_ FFD1_2WayOptSet : 246|2@1+ (1,0) [0|3] "" Vector__XXX
 SG_ FFD1_2PumpOpt : 242|1@1+ (1,0) [0|1] "" Vector__XXX

BO_ 2231329825 VCU_ZFIMP: 8 Vector__XXX
 SG_ ZFIMP_BucketPosition : 16|8@1+ (0.8,-100) [-100|104] "%" Vector__XXX
 SG_ ZFIMP_BoomPosition : 0|8@1+ (0.8,-100) [-100|104] "%" Vector__XXX

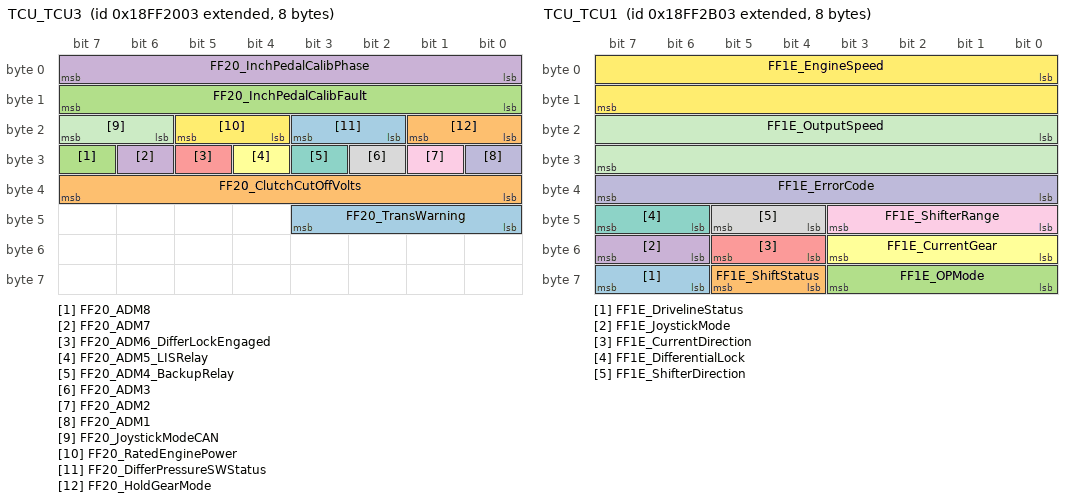
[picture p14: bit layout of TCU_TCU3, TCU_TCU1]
BO_ 2566856707 TCU_TCU3: 8 Vector__XXX
 SG_ FF20_TransWarning : 40|4@1- (1,0) [-8|7] "" Vector__XXX
 SG_ FF20_ClutchCutOffVolts : 32|8@1- (0.025,0) [0|3.175] "V" Vector__XXX
 SG_ FF20_ADM8 : 31|1@1+ (1,0) [0|1] "" Vector__XXX
 SG_ FF20_ADM7 : 30|1@1+ (1,0) [0|1] "" Vector__XXX
 SG_ FF20_ADM6_DifferLockEngaged : 29|1@1+ (1,0) [0|1] "" Vector__XXX
 SG_ FF20_ADM5_LISRelay : 28|1@1+ (1,0) [0|1] "" Vector__XXX
 SG_ FF20_ADM4_BackupRelay : 27|1@1+ (1,0) [0|1] "" Vector__XXX
 SG_ FF20_ADM3 : 26|1@1+ (1,0) [0|1] "" Vector__XXX
 SG_ FF20_ADM2 : 25|1@1+ (1,0) [0|1] "" Vector__XXX
 SG_ FF20_ADM1 : 24|1@1+ (1,0) [0|1] "" Vector__XXX
 SG_ FF20_JoystickModeCAN : 22|2@1+ (1,0) [0|3] "" Vector__XXX
 SG_ FF20_RatedEnginePower : 20|2@1+ (1,0) [0|3] "" Vector__XXX
 SG_ FF20_DifferPressureSWStatus : 18|2@1+ (1,0) [0|3] "" Vector__XXX
 SG_ FF20_HoldGearMode : 16|2@1+ (1,0) [0|3] "" Vector__XXX
 SG_ FF20_InchPedalCalibFault : 8|8@1+ (1,0) [0|21] "" Vector__XXX
 SG_ FF20_InchPedalCalibPhase : 0|8@1+ (1,0) [0|4] "" Vector__XXX

BO_ 2566848801 VCU_VEHICLE1: 8 Vector__XXX
 SG_ FF01_CCOSelect : 4|2@1+ (1,0) [0|3] "" Vector__XXX
 SG_ FF01_RetarderPressure : 56|8@1+ (1,0) [0|255] "" Vector__XXX
 SG_ FF01_DLMAutoSelect : 54|2@1+ (1,0) [0|3] "" Vector__XXX
 SG_ FF01_DLMManualSelect : 52|2@1+ (1,0) [0|3] "" Vector__XXX
 SG_ FF01_DownShiftMode : 50|2@1+ (1,0) [0|3] "" Vector__XXX
 SG_ FF01_GearRangeExpansion : 48|2@1+ (1,0) [0|3] "" Vector__XXX
 SG_ FF01_ConverterLockupDiable : 46|2@1+ (1,0) [0|3] "" Vector__XXX
 SG_ FF01_ShiftPointTableSelection : 44|2@1+ (1,0) [0|3] "" Vector__XXX
 SG_ FF01_RetPreheat : 42|2@1+ (1,0) [0|3] "" Vector__XXX
 SG_ FF01_ParkBrakeTest : 41|1@1+ (1,0) [0|1] "" Vector__XXX
 SG_ FF01_AEBRequest : 40|1@1+ (1,0) [0|1] "" Vector__XXX
 SG_ FF01_UpperGearLimit : 20|4@1+ (1,0) [0|15] "" Vector__XXX
 SG_ FF01_LowerGearLimit : 16|4@1+ (1,0) [0|15] "" Vector__XXX
 SG_ FF01_DifferentialLockSelect : 14|2@1+ (1,0) [0|3] "" Vector__XXX
 SG_ FF01_EngBrakeSelect : 12|2@1+ (1,0) [0|3] "" Vector__XXX
 SG_ FF01_RetarderSelect : 10|2@1+ (1,0) [0|3] "" Vector__XXX
 SG_ FF01_ParkBrakeStatus : 8|2@1+ (1,0) [0|3] "" Vector__XXX
 SG_ FF01_CCOSlope : 6|2@1+ (1,0) [0|3] "" Vector__XXX
 SG_ FF01_AutoShiftPoint : 2|2@1+ (1,0) [0|3] "" Vector__XXX
 SG_ FF01_AutoManSelect : 0|2@1+ (1,0) [0|3] "" Vector__XXX

BO_ 2566856451 TCU_TCU2: 8 Vector__XXX
 SG_ FF1F_GearRangeMax : 60|4@1+ (1,0) [0|15] "" Vector__XXX
 SG_ FF1F_GearRangeMin : 56|4@1+ (1,0) [0|15] "" Vector__XXX
 SG_ FF1F_ED15_FNR2ndSelectSW : 54|1@1+ (1,0) [0|1] "" Vector__XXX
 SG_ FF1F_ED14 : 53|1@1+ (1,0) [0|1] "" Vector__XXX
 SG_ FF1F_ED13 : 52|1@1+ (1,0) [0|1] "" Vector__XXX
 SG_ FF1F_ED12_LISSW : 51|1@1+ (1,0) [0|1] "" Vector__XXX
 SG_ FF1F_ED11_DifferLockManualSW : 50|1@1+ (1,0) [0|1] "" Vector__XXX
 SG_ FF1F_ED10_ParkingBrakeRelSW : 49|1@1+ (1,0) [0|1] "" Vector__XXX
 SG_ FF1F_ED9_CCOSW : 48|1@1+ (1,0) [0|1] "" Vector__XXX
 SG_ FF1F_ED8 : 47|1@1+ (1,0) [0|1] "" Vector__XXX
 SG_ FF1F_ED7_DirrerLockAutoSW : 46|1@1+ (1,0) [0|1] "" Vector__XXX
 SG_ FF1F_ED6 : 45|1@1+ (1,0) [0|1] "" Vector__XXX
 SG_ FF1F_ED5 : 44|1@1+ (1,0) [0|1] "" Vector__XXX
 SG_ FF1F_ED4 : 43|1@1+ (1,0) [0|1] "" Vector__XXX
 SG_ FF1F_ED3 : 42|1@1+ (1,0) [0|1] "" Vector__XXX
 SG_ FF1F_ED2 : 41|1@1+ (1,0) [0|1] "" Vector__XXX
 SG_ FF1F_ED1 : 40|1@1+ (1,0) [0|1] "" Vector__XXX
 SG_ FF1F_AEBSubcode : 24|8@1+ (1,0) [0|255] "" Vector__XXX
 SG_ FF1F_AEBCycle : 16|8@1+ (1,0) [0|255] "" Vector__XXX
 SG_ FF1F_AEBMaincode : 8|8@1+ (1,0) [0|255] "" Vector__XXX
 SG_ FF1F_SumpTemp : 32|8@1+ (1,-50) [-50|200] "" Vector__XXX
 SG_ FF1F_TorqueConTemp : 0|8@1+ (1,-50) [-50|200] "deg" Vector__XXX

BO_ 2566859523 TCU_TCU1: 8 Vector__XXX
 SG_ FF1E_DrivelineStatus : 62|2@1+ (1,0) [0|3] "" Vector__XXX
 SG_ FF1E_ShiftStatus : 60|2@1+ (1,0) [0|3] "" Vector__XXX
 SG_ FF1E_OPMode : 56|4@1+ (1,0) [0|15] "" Vector__XXX
 SG_ FF1E_JoystickMode : 54|2@1+ (1,0) [0|3] "" Vector__XXX
 SG_ FF1E_CurrentDirection : 52|2@1+ (1,0) [0|3] "" Vector__XXX
 SG_ FF1E_CurrentGear : 48|4@1+ (1,0) [0|15] "" Vector__XXX
 SG_ FF1E_DifferentialLock : 46|2@1+ (1,0) [0|3] "" Vector__XXX
 SG_ FF1E_ShifterDirection : 44|2@1+ (1,0) [0|3] "" Vector__XXX
 SG_ FF1E_ShifterRange : 40|4@1+ (1,0) [0|15] "" Vector__XXX
 SG_ FF1E_ErrorCode : 32|8@1+ (1,0) [0|255] "" Vector__XXX
 SG_ FF1E_OutputSpeed : 16|16@1+ (0.125,0) [0|8191.875] "rpm" Vector__XXX
 SG_ FF1E_EngineSpeed : 0|16@1+ (0.125,0) [0|8031.875] "rpm" Vector__XXX

BO_ 2565349687 AVM_Arc_Message: 8 Vector__XXX
 SG_ E817_Reserved : 8|56@1+ (1,0) [0|7.20575940379279E+016] "" Vector__XXX
 SG_ E817_Control_Byte : 0|8@1+ (1,0) [0|255] "" Vector__XXX

BO_ 2566834999 AVM_DM2: 120 Vector__XXX
 SG_ FECB_SPN_MSB : 37|3@1+ (1,0) [0|7] "" Vector__XXX
 SG_ FECB_SPN_LSB : 16|8@1+ (1,0) [0|255] "" Vector__XXX
 SG_ FECB_SPN_Conversion : 47|1@1+ (1,0) [0|1] "" Vector__XXX
 SG_ FECB_SPN2ndByte : 24|8@1+ (1,0) [0|255] "" Vector__XXX
 SG_ FECB_OccurrenceCount : 40|7@1- (1,0) [-64|63] "" Vector__XXX
 SG_ FECB_LampStatus_RedStop : 4|2@1+ (1,0) [0|3] "" Vector__XXX
 SG_ FECB_LampStatus_Protect : 0|2@1+ (1,0) [0|3] "" Vector__XXX
 SG_ FECB_LampStatus_Indicator : 6|2@1+ (1,0) [0|3] "" Vector__XXX
 SG_ FECB_LampStatus_AmberWarning : 2|2@1+ (1,0) [0|3] "" Vector__XXX
 SG_ FECB_FMI : 32|5@1+ (1,0) [0|31] "" Vector__XXX
 SG_ FECB_FlashRedStopLamp : 12|2@1+ (1,0) [0|3] "" Vector__XXX
 SG_ FECB_FlashProtectLamp : 8|2@1+ (1,0) [0|3] "" Vector__XXX
 SG_ FECB_FlashIndicatorLamp : 14|2@1+ (1,0) [0|3] "" Vector__XXX
 SG_ FECB_FlashAmberLamp : 10|2@1+ (1,0) [0|3] "" Vector__XXX

BO_ 2566834743 AVM_Active_DTC_DM1: 120 Vector__XXX
 SG_ FECA_UltraSonicWarning : 10|2@1+ (1,0) [0|3] "" Vector__XXX
 SG_ FECA_FlashRedStopLamp : 12|2@1+ (1,0) [0|3] "" Vector__XXX
 SG_ FECA_FlashProtectLamp : 8|2@1+ (1,0) [0|3] "" Vector__XXX
 SG_ FECA_Flash_IndicatorLamp : 14|2@1+ (1,0) [0|3] "" Vector__XXX
 SG_ FECA_SPNConversionMethod : 47|1@1+ (1,0) [0|1] "" Vector__XXX
 SG_ FECA_SPN3 : 37|3@1+ (1,0) [0|7] "" Vector__XXX
 SG_ FECA_SPN2 : 24|8@1+ (1,0) [0|255] "" Vector__XXX
 SG_ FECA_SPN1 : 16|8@1+ (1,0) [0|255] "" Vector__XXX
 SG_ FECA_RedStopLampStatus : 4|2@1+ (1,0) [0|3] "" Vector__XXX
 SG_ FECA_ProtectLampStatus : 0|2@1+ (1,0) [0|3] "" Vector__XXX
 SG_ FECA_OccurenceConut : 40|7@1+ (1,0) [0|127] "" Vector__XXX
 SG_ FECA_MalFucIndicatorLampStatus : 6|2@1+ (1,0) [0|3] "" Vector__XXX
 SG_ FECA_FMI : 32|5@1+ (1,0) [0|31] "" Vector__XXX
 SG_ FECA_AmberWarmingLampStatus : 2|2@1+ (1,0) [0|3] "" Vector__XXX

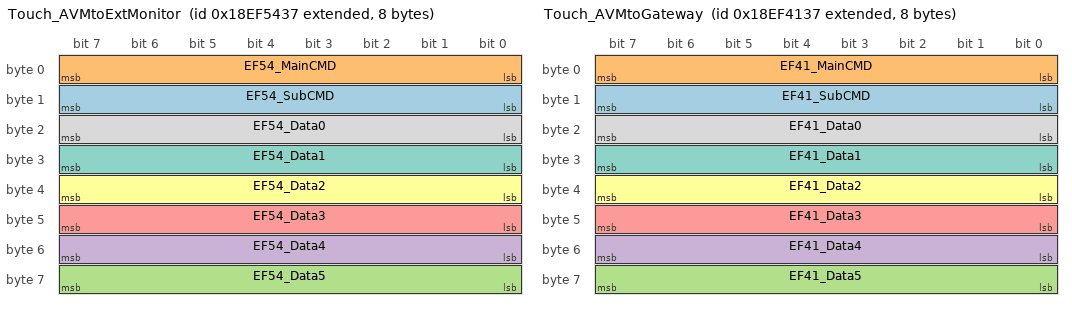
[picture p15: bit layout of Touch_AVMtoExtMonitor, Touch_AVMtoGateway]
BO_ 2565821495 Touch_AVMtoExtMonitor: 8 Vector__XXX
 SG_ EF54_SubCMD : 8|8@1+ (1,0) [0|255] "" Vector__XXX
 SG_ EF54_MainCMD : 0|8@1+ (1,0) [0|255] "" Vector__XXX
 SG_ EF54_Data5 : 56|8@1+ (1,0) [0|255] "" Vector__XXX
 SG_ EF54_Data4 : 48|8@1+ (1,0) [0|255] "" Vector__XXX
 SG_ EF54_Data3 : 40|8@1+ (1,0) [0|255] "" Vector__XXX
 SG_ EF54_Data2 : 32|8@1+ (1,0) [0|255] "" Vector__XXX
 SG_ EF54_Data1 : 24|8@1+ (1,0) [0|255] "" Vector__XXX
 SG_ EF54_Data0 : 16|8@1+ (1,0) [0|255] "" Vector__XXX

BO_ 2565816631 Touch_AVMtoGateway: 8 Vector__XXX
 SG_ EF41_SubCMD : 8|8@1+ (1,0) [0|255] "" Vector__XXX
 SG_ EF41_MainCMD : 0|8@1+ (1,0) [0|255] "" Vector__XXX
 SG_ EF41_Data5 : 56|8@1+ (1,0) [0|255] "" Vector__XXX
 SG_ EF41_Data4 : 48|8@1+ (1,0) [0|255] "" Vector__XXX
 SG_ EF41_Data3 : 40|8@1+ (1,0) [0|255] "" Vector__XXX
 SG_ EF41_Data2 : 32|8@1+ (1,0) [0|255] "" Vector__XXX
 SG_ EF41_Data1 : 24|8@1+ (1,0) [0|255] "" Vector__XXX
 SG_ EF41_Data0 : 16|8@1+ (1,0) [0|255] "" Vector__XXX

BO_ 2565810231 Touch_AVMtoGP: 14 Vector__XXX
 SG_ EF28_OTAupdateConfigFileID : 76|32@1+ (1,0) [0|4294967295] "" Vector__XXX
 SG_ EF28_OTA_percent_Command : 68|8@1+ (1,0) [0|255] "" Vector__XXX
 SG_ EF28_OTA_info_Command : 64|4@1+ (1,0) [0|15] "" Vector__XXX
 SG_ EF28_Datafield : 24|40@1+ (1,0) [0|1099511627775] "" Vector__XXX
 SG_ EF28_SuspectParameterNumber : 0|19@1+ (1,0) [0|524287] "" Vector__XXX

BO_ 2565482551 AVM_Request_to_GP: 2 Vector__XXX
 SG_ EA28_RequsetPGNB2 : 8|8@1+ (1,0) [0|255] "" Vector__XXX
 SG_ EA28_RequsetPGNB1 : 0|8@1+ (1,0) [0|255] "" Vector__XXX

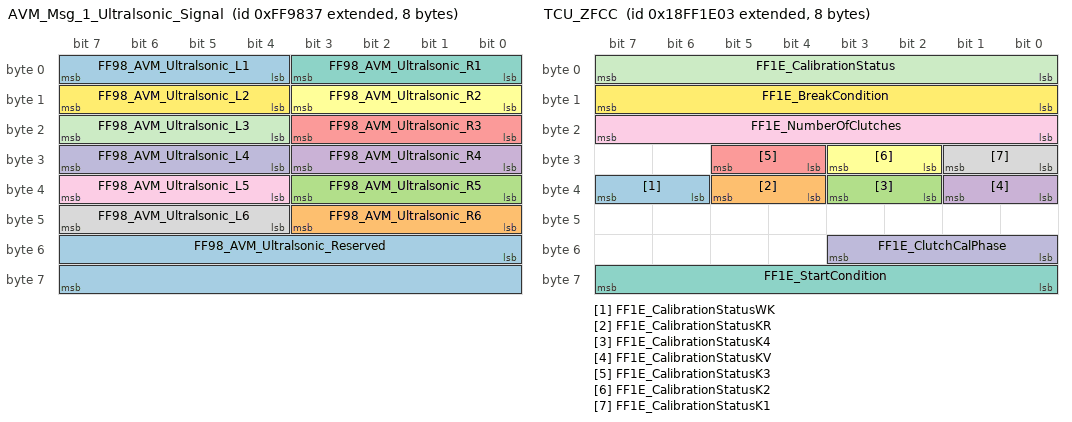
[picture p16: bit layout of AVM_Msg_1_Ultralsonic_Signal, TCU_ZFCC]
BO_ 2164234295 AVM_Msg_1_Ultralsonic_Signal: 8 Vector__XXX
 SG_ FF98_AVM_Ultralsonic_Reserved : 48|16@1+ (1,0) [0|65535] "" Vector__XXX
 SG_ FF98_AVM_Ultralsonic_R6 : 40|4@1+ (1,0) [0|15] "" Vector__XXX
 SG_ FF98_AVM_Ultralsonic_R5 : 32|4@1+ (1,0) [0|15] "" Vector__XXX
 SG_ FF98_AVM_Ultralsonic_R4 : 24|4@1+ (1,0) [0|15] "" Vector__XXX
 SG_ FF98_AVM_Ultralsonic_R3 : 16|4@1+ (1,0) [0|15] "" Vector__XXX
 SG_ FF98_AVM_Ultralsonic_R2 : 8|4@1+ (1,0) [0|15] "" Vector__XXX
 SG_ FF98_AVM_Ultralsonic_R1 : 0|4@1+ (1,0) [0|15] "" Vector__XXX
 SG_ FF98_AVM_Ultralsonic_L6 : 44|4@1+ (1,0) [0|15] "" Vector__XXX
 SG_ FF98_AVM_Ultralsonic_L5 : 36|4@1+ (1,0) [0|15] "" Vector__XXX
 SG_ FF98_AVM_Ultralsonic_L4 : 28|4@1+ (1,0) [0|15] "" Vector__XXX
 SG_ FF98_AVM_Ultralsonic_L3 : 20|4@1+ (1,0) [0|15] "" Vector__XXX
 SG_ FF98_AVM_Ultralsonic_L2 : 12|4@1+ (1,0) [0|15] "" Vector__XXX
 SG_ FF98_AVM_Ultralsonic_L1 : 4|4@1+ (1,0) [0|15] "" Vector__XXX

BO_ 2566856195 TCU_ZFCC: 8 Vector__XXX
 SG_ FF1E_CalibrationStatusWK : 38|2@1+ (1,0) [0|3] "" Vector__XXX
 SG_ FF1E_CalibrationStatusKR : 36|2@1+ (1,0) [0|3] "" Vector__XXX
 SG_ FF1E_CalibrationStatusK4 : 34|2@1+ (1,0) [0|3] "" Vector__XXX
 SG_ FF1E_CalibrationStatusKV : 32|2@1+ (1,0) [0|3] "" Vector__XXX
 SG_ FF1E_CalibrationStatusK3 : 28|2@1+ (1,0) [0|3] "" Vector__XXX
 SG_ FF1E_CalibrationStatusK2 : 26|2@1+ (1,0) [0|3] "" Vector__XXX
 SG_ FF1E_StartCondition : 56|8@1+ (1,0) [0|255] "" Vector__XXX
 SG_ FF1E_CalibrationStatusK1 : 24|2@1+ (1,0) [0|3] "" Vector__XXX
 SG_ FF1E_NumberOfClutches : 16|8@1+ (1,0) [0|255] "" Vector__XXX
 SG_ FF1E_ClutchCalPhase : 48|4@1+ (1,0) [0|15] "" Vector__XXX
 SG_ FF1E_CalibrationStatus : 0|8@1+ (1,0) [0|3] "" Vector__XXX
 SG_ FF1E_BreakCondition : 8|8@1+ (1,0) [0|9] "" Vector__XXX

BO_ 2365522209 VCU_DEC1V: 8 Vector__XXX
 SG_ AcceleratorPedalPositionCommand : 0|10@1+ (0.1,0) [0|100] "%" Vector__XXX

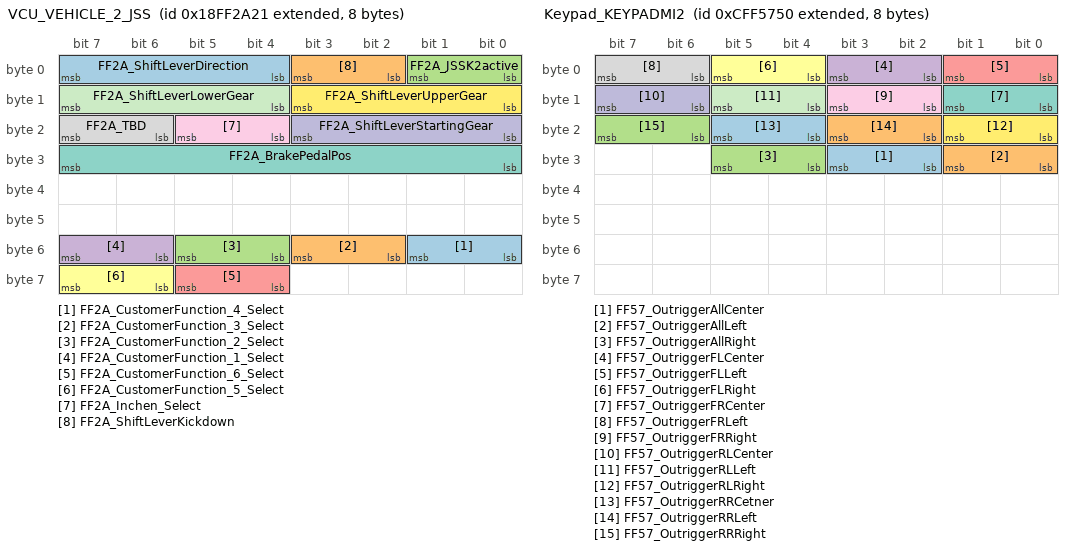
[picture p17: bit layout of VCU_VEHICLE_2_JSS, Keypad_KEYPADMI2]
BO_ 2566859297 VCU_VEHICLE_2_JSS: 8 Vector__XXX
 SG_ FF2A_CustomerFunction_4_Select : 48|2@1+ (1,0) [0|3] "" Vector__XXX
 SG_ FF2A_CustomerFunction_3_Select : 50|2@1+ (1,0) [0|3] "" Vector__XXX
 SG_ FF2A_CustomerFunction_2_Select : 52|2@1+ (1,0) [0|3] "" Vector__XXX
 SG_ FF2A_CustomerFunction_1_Select : 54|2@1+ (1,0) [0|3] "" Vector__XXX
 SG_ FF2A_CustomerFunction_6_Select : 60|2@1+ (1,0) [0|3] "" Vector__XXX
 SG_ FF2A_CustomerFunction_5_Select : 62|2@1+ (1,0) [0|3] "" Vector__XXX
 SG_ FF2A_BrakePedalPos : 24|8@1+ (1,0) [0|255] "%" Vector__XXX
 SG_ FF2A_TBD : 22|2@1+ (1,0) [0|3] "" Vector__XXX
 SG_ FF2A_Inchen_Select : 20|2@1+ (1,0) [0|3] "" Vector__XXX
 SG_ FF2A_ShiftLeverStartingGear : 16|4@1+ (1,0) [0|15] "" Vector__XXX
 SG_ FF2A_ShiftLeverLowerGear : 12|4@1+ (1,0) [0|15] "" Vector__XXX
 SG_ FF2A_ShiftLeverUpperGear : 8|4@1+ (1,0) [0|15] "" Vector__XXX
 SG_ FF2A_ShiftLeverDirection : 4|4@1+ (1,0) [0|15] "" Vector__XXX
 SG_ FF2A_ShiftLeverKickdown : 2|2@1+ (1,0) [0|3] "" Vector__XXX
 SG_ FF2A_JSSK2active : 0|2@1+ (1,0) [0|3] "" Vector__XXX

BO_ 2566905889 VCU_RTFI: 28 Vector__XXX
 SG_ FFE0_RT_Failure14_FMI : 219|5@1+ (1,0) [0|31] "" Vector__XXX
 SG_ FFE0_RT_Failure14_Code : 208|11@1+ (1,0) [0|2047] "" Vector__XXX
 SG_ FFE0_RT_Failure13_FMI : 203|5@1+ (1,0) [0|31] "" Vector__XXX
 SG_ FFE0_RT_Failure13_Code : 192|11@1+ (1,0) [0|2047] "" Vector__XXX
 SG_ FFE0_RT_Failure12_FMI : 187|5@1+ (1,0) [0|31] "" Vector__XXX
 SG_ FFE0_RT_Failure12_Code : 176|11@1+ (1,0) [0|2047] "" Vector__XXX
 SG_ FFE0_RT_Failure11_FMI : 171|5@1+ (1,0) [0|31] "" Vector__XXX
 SG_ FFE0_RT_Failure11_Code : 160|11@1+ (1,0) [0|2047] "" Vector__XXX
 SG_ FFE0_RT_Failure10_FMI : 155|5@1+ (1,0) [0|31] "" Vector__XXX
 SG_ FFE0_RT_Failure10_Code : 144|11@1+ (1,0) [0|2047] "" Vector__XXX
 SG_ FFE0_RT_Failure09_FMI : 139|5@1+ (1,0) [0|31] "" Vector__XXX
 SG_ FFE0_RT_Failure09_Code : 128|11@1+ (1,0) [0|2047] "" Vector__XXX
 SG_ FFE0_RT_Failure08_FMI : 123|5@1+ (1,0) [0|31] "" Vector__XXX
 SG_ FFE0_RT_Failure08_Code : 112|11@1+ (1,0) [0|2047] "" Vector__XXX
 SG_ FFE0_RT_Failure07_FMI : 107|5@1+ (1,0) [0|31] "" Vector__XXX
 SG_ FFE0_RT_Failure07_Code : 96|11@1+ (1,0) [0|2047] "" Vector__XXX
 SG_ FFE0_RT_Failure06_FMI : 91|5@1+ (1,0) [0|31] "" Vector__XXX
 SG_ FFE0_RT_Failure06_Code : 80|11@1+ (1,0) [0|2047] "" Vector__XXX
 SG_ FFE0_RT_Failure05_FMI : 75|5@1+ (1,0) [0|31] "" Vector__XXX
 SG_ FFE0_RT_Failure05_Code : 64|11@1+ (1,0) [0|2047] "" Vector__XXX
 SG_ FFE0_RT_Failure04_FMI : 59|5@1+ (1,0) [0|31] "" Vector__XXX
 SG_ FFE0_RT_Failure04_Code : 48|11@1+ (1,0) [0|2047] "" Vector__XXX
 SG_ FFE0_RT_Failure03_FMI : 43|5@1+ (1,0) [0|31] "" Vector__XXX
 SG_ FFE0_RT_Failure03_Code : 32|11@1+ (1,0) [0|2047] "" Vector__XXX
 SG_ FFE0_RT_Failure02_FMI : 27|5@1+ (1,0) [0|31] "" Vector__XXX
 SG_ FFE0_RT_Failure02_Code : 16|11@1+ (1,0) [0|2047] "" Vector__XXX
 SG_ FFE0_RT_Failure01_FMI : 11|5@1+ (1,0) [0|31] "" Vector__XXX
 SG_ FFE0_RT_Failure01_Code : 0|11@1+ (1,0) [0|2047] "" Vector__XXX

BO_ 2566847589 Fuel_Sensor_Display: 8 Vector__XXX
 SG_ Fuel_Level_Percent : 8|8@1+ (0.4,0) [0|100] "%" Vector__XXX

BO_ 2566260325 Fuel_Sensor_Info: 8 Vector__XXX
 SG_ Fuel_Temp : 48|8@1+ (1,-40) [-40|210] "deg C" Vector__XXX
 SG_ Fuel_Volume : 16|16@1+ (0.1,0) [0|6553.5] "L" Vector__XXX
 SG_ Fuel_Level_mm : 0|16@1+ (0.1,0) [0|6553.5] "mm" Vector__XXX

BO_ 2583685153 VCU_VBO_Torque: 8 Vector__XXX
 SG_ _1FFE8_VBO_PowerShift : 0|8@1+ (0.5,0) [0|127.5] "%" Vector__XXX

BO_ 2365544272 Keypad_KEYPADMI2: 8 Vector__XXX
 SG_ FF57_OutriggerAllCenter : 26|2@1+ (1,0) [0|3] "" Vector__XXX
 SG_ FF57_OutriggerAllLeft : 24|2@1+ (1,0) [0|3] "" Vector__XXX
 SG_ FF57_OutriggerAllRight : 28|2@1+ (1,0) [0|3] "" Vector__XXX
 SG_ FF57_OutriggerFLCenter : 2|2@1+ (1,0) [0|3] "" Vector__XXX
 SG_ FF57_OutriggerFLLeft : 0|2@1+ (1,0) [0|3] "" Vector__XXX
 SG_ FF57_OutriggerFLRight : 4|2@1+ (1,0) [0|3] "" Vector__XXX
 SG_ FF57_OutriggerFRCenter : 8|2@1+ (1,0) [0|3] "" Vector__XXX
 SG_ FF57_OutriggerFRLeft : 6|2@1+ (1,0) [0|3] "" Vector__XXX
 SG_ FF57_OutriggerFRRight : 10|2@1+ (1,0) [0|3] "" Vector__XXX
 SG_ FF57_OutriggerRLCenter : 14|2@1+ (1,0) [0|3] "" Vector__XXX
 SG_ FF57_OutriggerRLLeft : 12|2@1+ (1,0) [0|3] "" Vector__XXX
 SG_ FF57_OutriggerRLRight : 16|2@1+ (1,0) [0|3] "" Vector__XXX
 SG_ FF57_OutriggerRRCetner : 20|2@1+ (1,0) [0|3] "" Vector__XXX
 SG_ FF57_OutriggerRRLeft : 18|2@1+ (1,0) [0|3] "" Vector__XXX
 SG_ FF57_OutriggerRRRight : 22|2@1+ (1,0) [0|3] "" Vector__XXX

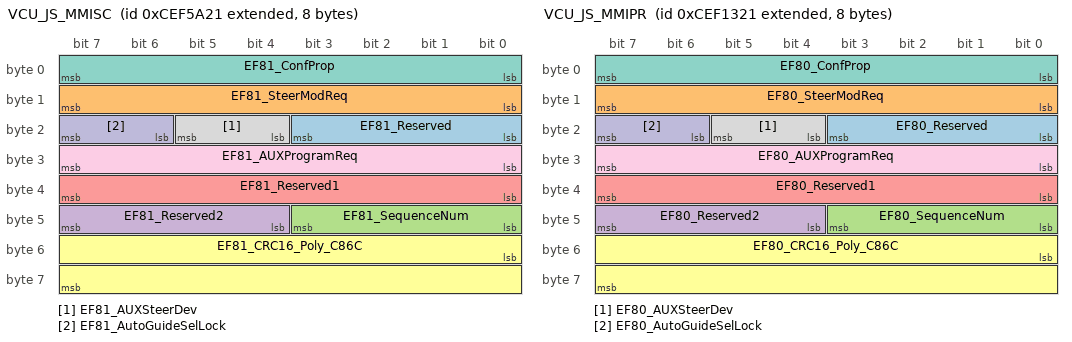
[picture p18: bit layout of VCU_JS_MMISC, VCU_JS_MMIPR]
BO_ 2364496417 VCU_JS_MMISC: 8 Vector__XXX
 SG_ EF81_Reserved : 16|4@1+ (1,0) [0|15] "" Vector__XXX
 SG_ EF81_SteerModReq : 8|8@1+ (1,0) [0|255] "" Vector__XXX
 SG_ EF81_SequenceNum : 40|4@1+ (1,0) [0|15] "" Vector__XXX
 SG_ EF81_Reserved2 : 44|4@1+ (1,0) [0|15] "" Vector__XXX
 SG_ EF81_Reserved1 : 32|8@1+ (1,0) [0|255] "" Vector__XXX
 SG_ EF81_CRC16_Poly_C86C : 48|16@1+ (1,0) [0|65535] "" Vector__XXX
 SG_ EF81_ConfProp : 0|8@1+ (1,0) [0|255] "" Vector__XXX
 SG_ EF81_AUXSteerDev : 20|2@1+ (1,0) [0|3] "" Vector__XXX
 SG_ EF81_AUXProgramReq : 24|8@1+ (1,0) [0|255] "" Vector__XXX
 SG_ EF81_AutoGuideSelLock : 22|2@1+ (1,0) [0|3] "" Vector__XXX

BO_ 2364478241 VCU_JS_MMIPR: 8 Vector__XXX
 SG_ EF80_Reserved : 16|4@1+ (1,0) [0|15] "" Vector__XXX
 SG_ EF80_SteerModReq : 8|8@1+ (1,0) [0|255] "" Vector__XXX
 SG_ EF80_SequenceNum : 40|4@1+ (1,0) [0|15] "" Vector__XXX
 SG_ EF80_Reserved2 : 44|4@1+ (1,0) [0|15] "" Vector__XXX
 SG_ EF80_Reserved1 : 32|8@1+ (1,0) [0|255] "" Vector__XXX
 SG_ EF80_CRC16_Poly_C86C : 48|16@1+ (1,0) [0|65535] "" Vector__XXX
 SG_ EF80_ConfProp : 0|8@1+ (1,0) [0|255] "" Vector__XXX
 SG_ EF80_AUXSteerDev : 20|2@1+ (1,0) [0|3] "" Vector__XXX
 SG_ EF80_AUXProgramReq : 24|8@1+ (1,0) [0|255] "" Vector__XXX
 SG_ EF80_AutoGuideSelLock : 22|2@1+ (1,0) [0|3] "" Vector__XXX

BO_ 2365528353 VCU_JS_VSRD: 8 Vector__XXX
 SG_ FF19_VehSpd : 16|16@1+ (0.00390625,0) [0|250.996] "" Vector__XXX
 SG_ FF19_SequenceNum : 40|4@1+ (1,0) [0|15] "" Vector__XXX
 SG_ FF19_DirIndication : 14|2@1+ (1,0) [0|3] "" Vector__XXX
 SG_ FF19_CRC16_Poly_C86C : 48|16@1+ (1,0) [0|65535] "" Vector__XXX

BO_ 2365528097 VCU_JS_VSPR: 8 Vector__XXX
 SG_ FF18_VehSpd : 16|16@1+ (0.00390625,0) [0|250.996] "" Vector__XXX
 SG_ FF18_SequenceNum : 40|4@1+ (1,0) [0|15] "" Vector__XXX
 SG_ FF18_DirIndication : 14|2@1+ (1,0) [0|3] "" Vector__XXX
 SG_ FF18_CRC16_Poly_C86C : 48|16@1+ (1,0) [0|65535] "" Vector__XXX

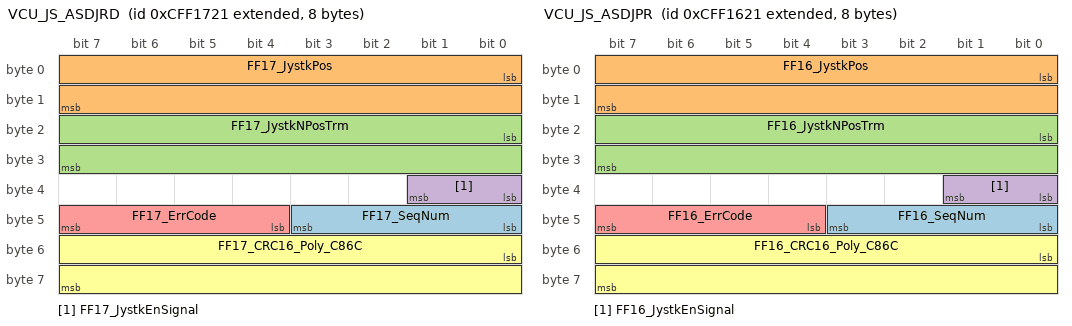
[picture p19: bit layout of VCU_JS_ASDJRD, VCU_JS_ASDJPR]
BO_ 2365527841 VCU_JS_ASDJRD: 8 Vector__XXX
 SG_ FF17_SeqNum : 40|4@1+ (1,0) [0|15] "" Vector__XXX
 SG_ FF17_JystkPos : 0|16@1+ (0.1,-100) [-100|100] "" Vector__XXX
 SG_ FF17_JystkNPosTrm : 16|16@1+ (0.1,-20) [-20|20] "" Vector__XXX
 SG_ FF17_JystkEnSignal : 32|2@1+ (1,0) [0|3] "" Vector__XXX
 SG_ FF17_ErrCode : 44|4@1+ (1,0) [0|15] "" Vector__XXX
 SG_ FF17_CRC16_Poly_C86C : 48|16@1+ (1,0) [0|65535] "" Vector__XXX

BO_ 2365527585 VCU_JS_ASDJPR: 8 Vector__XXX
 SG_ FF16_SeqNum : 40|4@1+ (1,0) [0|15] "" Vector__XXX
 SG_ FF16_JystkPos : 0|16@1+ (0.1,-100) [-100|100] "" Vector__XXX
 SG_ FF16_JystkNPosTrm : 16|16@1+ (0.1,-20) [-20|20] "" Vector__XXX
 SG_ FF16_JystkEnSignal : 32|2@1+ (1,0) [0|3] "" Vector__XXX
 SG_ FF16_ErrCode : 44|4@1+ (1,0) [0|15] "" Vector__XXX
 SG_ FF16_CRC16_Poly_C86C : 48|16@1+ (1,0) [0|65535] "" Vector__XXX

BO_ 2365543505 KeypadA_OperateSignal_SA51: 8 Vector__XXX
 SG_ FF54_881_TrackExpansion_SA51 : 63|1@1+ (1,0) [0|1] "" Vector__XXX
 SG_ FF54_871_InterlockOver_SA51 : 62|1@1+ (1,0) [0|1] "" Vector__XXX
 SG_ FF54_Keypad_861_Aux8_SA51 : 61|1@1+ (1,0) [0|1] "" Vector__XXX
 SG_ FF54_Keypad_851_Aux7_SA51 : 60|1@1+ (1,0) [0|1] "" Vector__XXX
 SG_ FF54_841_ContinuousFlow_SA51 : 59|1@1+ (1,0) [0|1] "" Vector__XXX
 SG_ FF54_Keypad_831_ReverseFan_SA51 : 58|1@1+ (1,0) [0|1] "" Vector__XXX
 SG_ FF54_Keypad_821_SelefLevel_SA51 : 57|1@1+ (1,0) [0|1] "" Vector__XXX
 SG_ FF54_Keypad_811_Reserved_SA51 : 56|1@1+ (1,0) [0|1] "" Vector__XXX
 SG_ FF54_Down_Signal_SA51 : 55|1@1+ (1,0) [0|1] "" Vector__XXX
 SG_ FF54_Up_Signal_SA51 : 54|1@1+ (1,0) [0|1] "" Vector__XXX
 SG_ FF54_Enter_Signal_SA51 : 53|1@1+ (1,0) [0|1] "" Vector__XXX
 SG_ FF54_Menu_Signal_SA51 : 52|1@1+ (1,0) [0|1] "" Vector__XXX
 SG_ FF54_BuzzerStopSignal_SA51 : 51|1@1+ (1,0) [0|1] "" Vector__XXX
 SG_ FF54_AudioSwitchSignal_SA51 : 50|1@1+ (1,0) [0|1] "" Vector__XXX
 SG_ FF54_CallSwitchSignal_SA51 : 49|1@1+ (1,0) [0|1] "" Vector__XXX
 SG_ FF54_711_RearClassHeater_SA51 : 48|1@1+ (1,0) [0|1] "" Vector__XXX
 SG_ FF54_Keypad_Front_Wiper_SA51 : 47|1@1+ (1,0) [0|1] "" Vector__XXX
 SG_ FF54_Keypad_Rear_Wiper_SA51 : 46|1@1+ (1,0) [0|1] "" Vector__XXX
 SG_ FF54_Keypad_Side_Wiper_SA51 : 45|1@1+ (1,0) [0|1] "" Vector__XXX
 SG_ FF54_Front_WiperWasher_SA51 : 44|1@1+ (1,0) [0|1] "" Vector__XXX
 SG_ FF54_Side_WiperWasher_SA51 : 43|1@1+ (1,0) [0|1] "" Vector__XXX
 SG_ FF54_AirCompSig_SA51 : 42|1@1+ (1,0) [0|1] "" Vector__XXX
 SG_ FF54_Keypad_TravelSpeedSig_SA51 : 41|1@1+ (1,0) [0|1] "" Vector__XXX
 SG_ FF54_Keypad_AutoidleSig_SA51 : 40|1@1+ (1,0) [0|1] "" Vector__XXX
 SG_ FF54_crab_round_select_SA51 : 39|1@1+ (1,0) [0|1] "" Vector__XXX
 SG_ FF54_4wheel_2wheel_select_SA51 : 38|1@1+ (1,0) [0|1] "" Vector__XXX
 SG_ FF54_ThrottleLockUp_SA51 : 37|1@1+ (1,0) [0|1] "" Vector__XXX
 SG_ FF54_TractionControlMode_SA51 : 36|1@1+ (1,0) [0|1] "" Vector__XXX
 SG_ FF54_VariableSpeedDown_SA51 : 35|1@1+ (1,0) [0|1] "" Vector__XXX
 SG_ FF54_VariableSpeedUp_SA51 : 34|1@1+ (1,0) [0|1] "" Vector__XXX
 SG_ FF54_MaxSpeedUp_SA51 : 33|1@1+ (1,0) [0|1] "" Vector__XXX
 SG_ FF54_MaxSpeedDown_SA51 : 32|1@1+ (1,0) [0|1] "" Vector__XXX
 SG_ FF54_TorqueConverterLockUp_SA51 : 31|1@1+ (1,0) [0|1] "" Vector__XXX
 SG_ FF54_ClutchCutOff_SA51 : 30|1@1+ (1,0) [0|1] "" Vector__XXX
 SG_ FF54_TrsmModeSelect_SA51 : 29|1@1+ (1,0) [0|1] "" Vector__XXX
 SG_ FF54_451_ShakeControl_SA51 : 28|1@1+ (1,0) [0|1] "" Vector__XXX
 SG_ FF54_Outrigger_ALL_SA51 : 27|1@1+ (1,0) [0|1] "" Vector__XXX
 SG_ FF54_Outrigger_RR_SA51 : 26|1@1+ (1,0) [0|1] "" Vector__XXX
 SG_ FF54_Outrigger_RL_SA51 : 25|1@1+ (1,0) [0|1] "" Vector__XXX
 SG_ FF54_Outrigger_FR_SA51 : 24|1@1+ (1,0) [0|1] "" Vector__XXX
 SG_ FF54_Outrigger_FL_SA51 : 23|1@1+ (1,0) [0|1] "" Vector__XXX
 SG_ FF54_DifferentialLockEng_SA51 : 22|1@1+ (1,0) [0|1] "" Vector__XXX
 SG_ FF54_EmergencySteering_SA51 : 21|1@1+ (1,0) [0|1] "" Vector__XXX
 SG_ FF54_BucketDetent_SA51 : 20|1@1+ (1,0) [0|1] "" Vector__XXX
 SG_ FF54_BoomDetent_SA51 : 19|1@1+ (1,0) [0|1] "" Vector__XXX
 SG_ FF54_LoadIsolation_SA51 : 18|1@1+ (1,0) [0|1] "" Vector__XXX
 SG_ FF54_ModeSelect_SA51 : 17|1@1+ (1,0) [0|1] "" Vector__XXX
 SG_ FF54_MenuHelp_SA51 : 16|1@1+ (1,0) [0|1] "" Vector__XXX
 SG_ FF54_JoystickSteering_SA51 : 15|1@1+ (1,0) [0|1] "" Vector__XXX
 SG_ FF54_Keypad_Fineswing_SA51 : 14|1@1+ (1,0) [0|1] "" Vector__XXX
 SG_ FF54_Keypad_TrailerHitch_SA51 : 13|1@1+ (1,0) [0|1] "" Vector__XXX
 SG_ FF54_Keypad_ADB_SA51 : 12|1@1+ (1,0) [0|1] "" Vector__XXX
 SG_ FF54_Keypad_BoomSwing_SA51 : 11|1@1+ (1,0) [0|1] "" Vector__XXX
 SG_ FF54_Keypad_Workmode_SA51 : 10|1@1+ (1,0) [0|1] "" Vector__XXX
 SG_ FF54_Keypad_Powermode_SA51 : 9|1@1+ (1,0) [0|1] "" Vector__XXX
 SG_ FF54_Keypad_TravelAlarm_SA51 : 8|1@1+ (1,0) [0|1] "" Vector__XXX
 SG_ FF54_MirrorHeat_SA51 : 7|1@1+ (1,0) [0|1] "" Vector__XXX
 SG_ FF54_RearWiperAndWasher_SA51 : 6|1@1+ (1,0) [0|1] "" Vector__XXX
 SG_ FF54_Keypad_OWD_SA51 : 5|1@1+ (1,0) [0|1] "" Vector__XXX
 SG_ FF54_Keypad_BoomLamp_SA51 : 4|1@1+ (1,0) [0|1] "" Vector__XXX
 SG_ FF54_BeaconLamp_SA51 : 3|1@1+ (1,0) [0|1] "" Vector__XXX
 SG_ FF54_RearWorkingLamp_SA51 : 2|1@1+ (1,0) [0|1] "" Vector__XXX
 SG_ FF54_FrontWorkingLamp_SA51 : 1|1@1+ (1,0) [0|1] "" Vector__XXX
 SG_ FF54_HeadLamp_SA51 : 0|1@1+ (1,0) [0|1] "" Vector__XXX

CM_ BO_ 2566763581 "Aftertreatment 1 Intake Gas 2";
CM_ BO_ 2566719744 "High Resolution Fuel Consumption (Liquid)";
CM_ BO_ 2566725632 "Aftertreatment 1 Diesel Oxidation Catalyst";
CM_ BO_ 2566749184 "Diesel Particulate Filter Control 1";
CM_ BO_ 2566831360 "Fan Drive #1";
CM_ BO_ 2566845696 "Ambient Conditions";
CM_ BO_ 2566846208 "Vehicle Electrical Power 1";
CM_ BO_ 2566845952 "Intake/Exhaust Conditions 1";
CM_ BO_ 2348875776 "Transmission Control 1";
CM_ BO_ 2565668669 "Transport Protocol - Connection Management";
CM_ SG_ 2565668669 ECU_TPCM_SA3D_Mux "Request to Send";
CM_ BO_ 2566804993 "Aftertreatment 1 Diesel Exhaust Fluid Tank 1 Information";
CM_ BO_ 2566763325 "Aftertreatment 1 Outlet Gas 2";
CM_ BO_ 2565799680 "Address Claimed";
CM_ BO_ 2565869137 "Aftertreatment 1 Intake Gas 1";
CM_ BO_ 2566709248 "Diesel Particulate Filter Control 2";
CM_ BO_ 2365394514 "Aftertreatment 1 Outlet Gas NOx Sensor correction data 2";
CM_ BO_ 2365394770 "Aftertreatment 1 Outlet Gas NOx Sensor correction data 1";
CM_ BO_ 2365395025 "Aftertreatment 1 Intake Gas NOx Sensor correction data 2";
CM_ BO_ 2365395281 "Aftertreatment 1 Intake Gas  NOx Sensor correction data 1";
CM_ BO_ 2566757374 "Aftertreatment 1 Diesel Exhaust Fluid Information";
CM_ BO_ 2566771968 "Electronic Engine Controller 5";
CM_ BO_ 2566802176 "Transmission Configuration 2";
CM_ BO_ 2566803211 "Vehicle Dynamic Stability Control 1";
CM_ BO_ 2365484270 "Tachograph";
CM_ BO_ 2298375691 "High Resolution Wheel Speed";
CM_ BO_ 2566818849 "Auxiliary Analog Information";
CM_ BO_ 2566831883 "Wheel Speed Information";
CM_ BO_ 2566832622 "High Resolution Vehicle Distance";
CM_ BO_ 2566838561 "Auxiliary Input/Output Status 1";
CM_ BO_ 2566839296 "Idle Operation";
CM_ BO_ 2566841600 "Engine Hours, Revolutions";
CM_ BO_ 2566842094 "Time/Date";
CM_ BO_ 2566842112 "Vehicle Hours";
CM_ BO_ 2566843136 "Component Identification";
CM_ BO_ 2566843392 "Vehicle Identification";
CM_ BO_ 2566843648 "Cruise Control/Vehicle Speed Setup";
CM_ BO_ 2566847511 "Dash Display";
CM_ BO_ 2564816679 "Stop Start Broadcast";
CM_ BO_ 2564816929 "Cab Message 1";
CM_ BO_ 2565869394 "Aftertreatment 1 Outlet Gas 1";
CM_ BO_ 2565668641 "Transport Protocol - Connection Management";
CM_ SG_ 2565668641 VCU_BAM_REX_Mux "Request to Send";
CM_ BO_ 2564882192 "Cab Message 1";
CM_ BO_ 2365457697 "Generator Total AC Power";
CM_ BO_ 2348810251 "Torque/Speed Control 1";
CM_ BO_ 2566834691 "Active Diagnostic Trouble Codes";
CM_ BO_ 2565865761 "Electronic Brake Controller 1";
CM_ SG_ 2231329825 ZFIMP_BucketPosition "This position of the bucket relative to the frame must be evaluated. The result must be transmitted via CAN. FE: Not available --> Function deactivatedFF: Error";
CM_ SG_ 2231329825 ZFIMP_BoomPosition "This position of the boom relative to the frame must be evaluated. The result must be transmitted via CAN. FE: Not available --> Function deactivatedFF: Error";
CM_ BO_ 2566859523 "ZF Clutch Calibration";
CM_ BO_ 2566856195 "ZF Clutch Calibration";
BA_DEF_ BO_  "VFrameFormat" ENUM  "StandardCAN","ExtendedCAN","reserved","J1939PG";
BA_DEF_ BO_  "GenMsgCycleTime" INT 0 65535;
BA_DEF_ SG_  "GenSigStartValue" FLOAT -3.4E+038 3.4E+038;
BA_DEF_ SG_  "SPN" INT -3.4E+038 3.4E+038;
BA_DEF_ SG_  "SigType" ENUM  "Default","Range","RangeSigned","ASCII","Discrete","Control","ReferencePGN","DTC","StringDelimiter","StringLength","StringLengthControl","MessageCounter","MessageChecksum";
BA_DEF_DEF_  "VFrameFormat" "J1939PG";
BA_DEF_DEF_  "GenMsgCycleTime" 0;
BA_DEF_DEF_  "GenSigStartValue" 0;
BA_DEF_DEF_  "SPN" 0;
BA_DEF_DEF_  "SigType" "Default";
BA_ "GenMsgCycleTime" BO_ 2566763581 500;
BA_ "GenMsgCycleTime" BO_ 2566719744 1000;
BA_ "GenMsgCycleTime" BO_ 2566725632 500;
BA_ "GenMsgCycleTime" BO_ 2566749184 1000;
BA_ "GenMsgCycleTime" BO_ 2566831360 1000;
BA_ "GenMsgCycleTime" BO_ 2566845696 1000;
BA_ "GenMsgCycleTime" BO_ 2566846208 1000;
BA_ "GenMsgCycleTime" BO_ 2566845952 500;
BA_ "GenMsgCycleTime" BO_ 2348875776 50;
BA_ "GenMsgCycleTime" BO_ 2565807649 100;
BA_ "GenMsgCycleTime" BO_ 2566804993 1000;
BA_ "GenMsgCycleTime" BO_ 2566763325 500;
BA_ "GenMsgCycleTime" BO_ 2565869137 50;
BA_ "GenMsgCycleTime" BO_ 2566709248 100;
BA_ "GenMsgCycleTime" BO_ 2566757374 1000;
BA_ "GenMsgCycleTime" BO_ 2566802176 5000;
BA_ "GenMsgCycleTime" BO_ 2566803211 100;
BA_ "GenMsgCycleTime" BO_ 2365484270 50;
BA_ "GenMsgCycleTime" BO_ 2298375691 20;
BA_ "GenMsgCycleTime" BO_ 2566831883 100;
BA_ "GenMsgCycleTime" BO_ 2566832622 1000;
BA_ "GenMsgCycleTime" BO_ 2566838561 100;
BA_ "GenMsgCycleTime" BO_ 2566847511 1000;
BA_ "GenMsgCycleTime" BO_ 2564816929 1000;
BA_ "GenMsgCycleTime" BO_ 2565869394 50;
BA_ "GenMsgCycleTime" BO_ 2564882192 1000;
BA_ "GenMsgCycleTime" BO_ 2365457697 100;
BA_ "GenMsgCycleTime" BO_ 2348810251 10;
BA_ "GenMsgCycleTime" BO_ 2566834691 1000;
BA_ "GenMsgCycleTime" BO_ 2565865761 100;
BA_ "GenMsgCycleTime" BO_ 2365543713 100;
BA_ "GenMsgCycleTime" BO_ 2365543504 100;
BA_ "GenMsgCycleTime" BO_ 2231329825 20;
BA_ "GenMsgCycleTime" BO_ 2566859523 100;
BA_ "GenMsgCycleTime" BO_ 2566856195 100;
BA_ "GenMsgCycleTime" BO_ 2365544272 100;
BA_ "GenMsgCycleTime" BO_ 2365543505 100;
BA_ "GenSigStartValue" SG_ 2566763581 Aftrtrtmnt1ExhaustTemperature1 8736;
BA_ "SPN" SG_ 2566763581 Aftrtrtmnt1ExhaustTemperature1 3241;
BA_ "GenSigStartValue" SG_ 2566763581 Aftrtrtmnt1DslPFIntkTemperature 8736;
BA_ "SPN" SG_ 2566763581 Aftrtrtmnt1DslPFIntkTemperature 3242;
BA_ "SPN" SG_ 2566763581 Aftrtrtmnt1ExhstTemp1PrelimFMI 3243;
BA_ "SPN" SG_ 2566763581 Aft1DslPFIntkTempPrelimFMI 3244;
BA_ "SPN" SG_ 2566719744 EngineTripFuel 5053;
BA_ "SPN" SG_ 2566719744 EngineTotalFuelUsed 5054;
BA_ "GenSigStartValue" SG_ 2566725632 Aft1DslOxidtnCtlystIntkTemp 8736;
BA_ "SPN" SG_ 2566725632 Aft1DslOxidtnCtlystIntkTemp 4765;
BA_ "GenSigStartValue" SG_ 2566725632 Aft1DslOxidtnCtlystOtltTemp 8736;
BA_ "SPN" SG_ 2566725632 Aft1DslOxidtnCtlystOtltTemp 4766;
BA_ "SPN" SG_ 2566725632 Aft1DslOxidtnCtlystDiffPress 4767;
BA_ "SPN" SG_ 2566725632 Aft1DslOxidtnCatIntkTmpPrlmFMI 4768;
BA_ "SPN" SG_ 2566725632 Aft1DslOxidtnCatOtltTmpPrlmFMI 4769;
BA_ "SPN" SG_ 2566725632 Aft1DslOxidtnCatDiffPressPrlmFMI 4770;
BA_ "SPN" SG_ 2566749184 DieselParticulateFilterLampCmd 3697;
BA_ "SPN" SG_ 2566749184 AftrtrtmntDslPFPassiveRegenStat 3699;
BA_ "SPN" SG_ 2566749184 AftrtrtmntDslPFActvRegenStatus 3700;
BA_ "SPN" SG_ 2566749184 AftrtrtmntDslPFStatus 3701;
BA_ "SPN" SG_ 2566749184 DslPFActvRegenInhbtdStatus 3702;
BA_ "SPN" SG_ 2566749184 DslPFActvRegenInhbtdDTInhbtSw 3703;
BA_ "SPN" SG_ 2566749184 DslPFActRegenInhbtdDTCltchDiseng 3704;
BA_ "SPN" SG_ 2566749184 DslPFActRegenInhbtdDTSrvcBrkActv 3705;
BA_ "SPN" SG_ 2566749184 DslPFActvRegenInhbtdDTPTOActv 3706;
BA_ "SPN" SG_ 2566749184 DPFActRegenInhbtdDTAcclPdlOffIdl 3707;
BA_ "SPN" SG_ 2566749184 DslPFActvRegenInhbtdDTOutOfNtrl 3708;
BA_ "SPN" SG_ 2566749184 DPFActRegInhDTVhclSpdAbvAllwdSpd 3709;
BA_ "SPN" SG_ 2566749184 DPFActRegenInhbtdDTPrkBrkNotSet 3710;
BA_ "SPN" SG_ 2566749184 DPFActRegenInhbtdDTLowExhstTemp 3711;
BA_ "SPN" SG_ 2566749184 DslPFActRegenInhbtdDTSysFaultAct 3712;
BA_ "SPN" SG_ 2566749184 DslPFActvRegenInhbtdDTSysTimeout 3713;
BA_ "SPN" SG_ 2566749184 DPFActRegenInhbtdDTTmprySysLckt 3714;
BA_ "SPN" SG_ 2566749184 DPFActRegenInhbtdDTPrmntSysLckt 3715;
BA_ "SPN" SG_ 2566749184 DPFActRegInhbtdDTEngNotWarmedUp 3716;
BA_ "SPN" SG_ 2566749184 DPFActRegInhDTVhclSpdBlwAllwdSpd 3717;
BA_ "SPN" SG_ 2566749184 DslPFAutoActvRegenInitConf 3718;
BA_ "SPN" SG_ 2566749184 ExhstSystemHghTemperatureLampCmd 3698;
BA_ "SPN" SG_ 2566749184 DslPFActvRegenForcedStatus 4175;
BA_ "SPN" SG_ 2566749184 HydrocarbonDoserPurgingEnable 5504;
BA_ "SPN" SG_ 2566749184 DPFActRegenInhbtdDTLowExhstPress 5629;
BA_ "SPN" SG_ 2566749184 Aft1DPFConditionsNotMetForActReg 3750;
BA_ "SPN" SG_ 2566831360 EngineFan1EstimatedPercentSpeed 975;
BA_ "SPN" SG_ 2566831360 FanDriveState 977;
BA_ "SPN" SG_ 2566831360 FanSpeed 1639;
BA_ "SPN" SG_ 2566831360 HydraulicFanMotorPressure 4211;
BA_ "SPN" SG_ 2566831360 FanDriveBypassCommandStatus 4212;
BA_ "SPN" SG_ 2566845696 BarometricPressure 108;
BA_ "GenSigStartValue" SG_ 2566845696 CabInteriorTemperature 8736;
BA_ "SPN" SG_ 2566845696 CabInteriorTemperature 170;
BA_ "GenSigStartValue" SG_ 2566845696 AmbientAirTemperature 8736;
BA_ "SPN" SG_ 2566845696 AmbientAirTemperature 171;
BA_ "GenSigStartValue" SG_ 2566845696 EngineIntakeAirTemperature 40;
BA_ "SPN" SG_ 2566845696 EngineIntakeAirTemperature 172;
BA_ "GenSigStartValue" SG_ 2566845696 RoadSurfaceTemperature 8736;
BA_ "SPN" SG_ 2566845696 RoadSurfaceTemperature 79;
BA_ "GenSigStartValue" SG_ 2566846208 NetBatteryCurrent 125;
BA_ "SPN" SG_ 2566846208 NetBatteryCurrent 114;
BA_ "SPN" SG_ 2566846208 AlternatorCurrent 115;
BA_ "SPN" SG_ 2566846208 ChargingSystemPotential 167;
BA_ "SPN" SG_ 2566846208 BatteryPotentialPowerInput1 168;
BA_ "SPN" SG_ 2566846208 KeyswitchBatteryPotential 158;
BA_ "SPN" SG_ 2566845952 DOC_outlet_gas_temp 173;
BA_ "SPN" SG_ 2566845952 Aftrtrtmnt1DslPFIntkPressure 81;
BA_ "SPN" SG_ 2566845952 EngineIntakeManifold1Pressure 102;
BA_ "GenSigStartValue" SG_ 2566845952 EngineIntakeManifold1Temperature 40;
BA_ "SPN" SG_ 2566845952 EngineIntakeManifold1Temperature 105;
BA_ "SPN" SG_ 2566845952 EngineIntakeAirPressure 106;
BA_ "SPN" SG_ 2566845952 EngineAirFilter1DiffPressure 107;
BA_ "SPN" SG_ 2566845952 DOC_intake_gas_temp 173;
BA_ "SPN" SG_ 2566845952 EngineCoolntFilterDiffPressure 112;
BA_ "SPN" SG_ 2348875776 TransmissionGearShiftInhbtRq 681;
BA_ "SPN" SG_ 2348875776 TrnsmTrqCnvLockupDisableRq 682;
BA_ "SPN" SG_ 2348875776 DisengageDrivelineRequest 683;
BA_ "SPN" SG_ 2348875776 TrnsmReverseGearShftInhbtRq 4242;
BA_ "SPN" SG_ 2348875776 RequestedPercentClutchSlip 684;
BA_ "GenSigStartValue" SG_ 2348875776 TransmissionRequestedGear 125;
BA_ "SPN" SG_ 2348875776 TransmissionRequestedGear 525;
BA_ "SPN" SG_ 2348875776 DisengiffLockRequestFrontAxl1 685;
BA_ "SPN" SG_ 2348875776 DisengiffLockRequestFrontAxl2 686;
BA_ "SPN" SG_ 2348875776 DisengageDiffLockRequestRearAxl1 687;
BA_ "SPN" SG_ 2348875776 DisengageDiffLockRequestRearAxl2 688;
BA_ "SPN" SG_ 2348875776 DisengageDiffLockRequestCentral 689;
BA_ "SPN" SG_ 2348875776 DisengiffLockRequestCentralFront 690;
BA_ "SPN" SG_ 2348875776 DisengiffLockRequestCentralRear 691;
BA_ "SPN" SG_ 2348875776 TransmissionLoadRedInhbtRequest 5762;
BA_ "SPN" SG_ 2348875776 TransmissionMode1 1852;
BA_ "SPN" SG_ 2348875776 TransmissionMode2 1853;
BA_ "SPN" SG_ 2348875776 TransmissionMode3 1854;
BA_ "SPN" SG_ 2348875776 TransmissionMode4 1855;
BA_ "SPN" SG_ 2348875776 TransmissionRequestedLaunchGear 4255;
BA_ "SPN" SG_ 2348875776 TrnsmShftSlctorDisplayMdeSw 2985;
BA_ "SPN" SG_ 2348875776 TransmissionMode5 4246;
BA_ "SPN" SG_ 2348875776 TransmissionMode6 4247;
BA_ "SPN" SG_ 2348875776 TransmissionMode7 4248;
BA_ "SPN" SG_ 2348875776 TransmissionMode8 4249;
BA_ "SPN" SG_ 2365541665 FF4D_Max_RPM 190;
BA_ "SPN" SG_ 2365541665 FF4D_Min_RPM 190;
BA_ "GenSigStartValue" SG_ 2566866209 FF45_WeighingMeasureWeight 32127;
BA_ "SPN" SG_ 2565668669 TotalMessageSize16 2557;
BA_ "SPN" SG_ 2565668669 TotalNumberOfPackets16 2558;
BA_ "SPN" SG_ 2565668669 MaximumNumberOfPackets 2559;
BA_ "SPN" SG_ 2565668669 PGNOfThePacketedMessage16 2560;
BA_ "SPN" SG_ 2565668669 NumberOfPacketsThatCanBeSent 2561;
BA_ "SPN" SG_ 2565668669 NextPacketNumberToBeSent 2562;
BA_ "SPN" SG_ 2565668669 PGNOfThePacketedMessage17 2563;
BA_ "SPN" SG_ 2565668669 TotalMessageSize19 2564;
BA_ "SPN" SG_ 2565668669 TotalNumberOfPackets19 2565;
BA_ "SPN" SG_ 2565668669 PGNOfThePacketedMessage19 2566;
BA_ "SPN" SG_ 2565668669 TotalMessageSize32 2567;
BA_ "SPN" SG_ 2565668669 TotalNumberOfPackets32 2568;
BA_ "SPN" SG_ 2565668669 PGNOfThePacketedMessage32 2569;
BA_ "SPN" SG_ 2565668669 ConnectionAbortReason 2570;
BA_ "SPN" SG_ 2565668669 ParameterGrpNoOfPacketedMessage 2571;
BA_ "SPN" SG_ 2566804993 Aftrtrtmnt1DslExhstFldTankLevel 1761;
BA_ "GenSigStartValue" SG_ 2566804993 Aftrtrtmnt1DslExhstFldTnkTemp 40;
BA_ "SPN" SG_ 2566804993 Aftrtrtmnt1DslExhstFldTnkTemp 3031;
BA_ "SPN" SG_ 2566804993 Aftrtrtmnt1DslExhstFldTankLevel2 3517;
BA_ "SPN" SG_ 2566804993 Aft1DslExhstFldTnkLvlPrelimFMI 3532;
BA_ "SPN" SG_ 2566804993 AftSlctiveCtlytcRedOprtrIndcmntA 5245;
BA_ "SPN" SG_ 2566804993 Aft1DslExhstFldTnk1TempPrelimFMI 4365;
BA_ "SPN" SG_ 2566804993 AftrtrtmntSCROprtrIndcmntSvrty 5246;
BA_ "SPN" SG_ 2566804993 Aftrtrtmnt1DslExhstFldTankHeater 3363;
BA_ "SPN" SG_ 2566804993 Aft1DslExhstFldTnk1HtrPrelimFMI 4366;
BA_ "GenSigStartValue" SG_ 2566763325 Aftrtrtmnt1ExhaustTemperature3 8736;
BA_ "SPN" SG_ 2566763325 Aftrtrtmnt1ExhaustTemperature3 3245;
BA_ "GenSigStartValue" SG_ 2566763325 Aftrtrtmnt1DslPFOtltTemperature 8736;
BA_ "SPN" SG_ 2566763325 Aftrtrtmnt1DslPFOtltTemperature 3246;
BA_ "SPN" SG_ 2566763325 Aftrtrtmnt1ExhstTemp3PrelimFMI 3247;
BA_ "SPN" SG_ 2566763325 Aft1DslPFOtltExhstTempPrelimFMI 3248;
BA_ "SPN" SG_ 2565799680 NAMEOfControllerApplication 2848;
BA_ "GenSigStartValue" SG_ 2565869137 Aft1SlctiveCtlytcRedIntkNOx 4000;
BA_ "SPN" SG_ 2565869137 Aft1SlctiveCtlytcRedIntkNOx 3216;
BA_ "GenSigStartValue" SG_ 2565869137 Aftertreatment1IntakePercentO2 23346.3035019455;
BA_ "SPN" SG_ 2565869137 Aftertreatment1IntakePercentO2 3217;
BA_ "SPN" SG_ 2565869137 Aftrtrtmnt1IntkGasSensorPwrInRng 3218;
BA_ "SPN" SG_ 2565869137 Aftrtrtmnt1IntkGasSnsrAtTemp 3219;
BA_ "SPN" SG_ 2565869137 Aft1SlctiveCtlytcRedIntkNOxRdngS 3220;
BA_ "SPN" SG_ 2565869137 Aft1IntkWdRngPrcntO2RdngStable 3221;
BA_ "SPN" SG_ 2565869137 Aft1IntkGasSnsrHtrPrelimFMI 3222;
BA_ "SPN" SG_ 2565869137 Aftrtrtmnt1IntkGasSensorHtrCtrl 3223;
BA_ "SPN" SG_ 2565869137 Aft1SlctiveCtlytcRedIntkNOxSnsrP 3224;
BA_ "SPN" SG_ 2565869137 Aft1IntkNOxSnsrSelfDiagnssStat 5714;
BA_ "SPN" SG_ 2565869137 Aftrtrtmnt1IntkO2SensorPrelimFMI 3225;
BA_ "GenSigStartValue" SG_ 2566709248 Aft1DslPFIntkTemperatuRstPoint 8736;
BA_ "SPN" SG_ 2566709248 Aft1DslPFIntkTemperatuRstPoint 5501;
BA_ "SPN" SG_ 2566709248 EngineUnburnedFuelPercentage 5502;
BA_ "SPN" SG_ 2566709248 Aftertreatment1FuelMassRate 5503;
BA_ "SPN" SG_ 2566709248 Aftertreatment2FuelMassRate 5834;
BA_ "SPN" SG_ 2365394514 Aft1OtltNOxSnsrO2PressCorrctn 5034;
BA_ "SPN" SG_ 2365394514 Aft1OtltNOxSnsrNOxPressCorrctn 5035;
BA_ "SPN" SG_ 2365394514 Aftrtrtmnt1OtltNOxSnsrNO2Corrctn 5036;
BA_ "SPN" SG_ 2365394514 Aftrtrtmnt1OtltNOxSnsrNH3Corrctn 5037;
BA_ "SPN" SG_ 2365394514 Aft1OtltNOxSnsrSelfDiagssFinalRs 5717;
BA_ "SPN" SG_ 2365394770 Aftrtrtmnt1OtltNOxSensorHtrRatio 5031;
BA_ "GenSigStartValue" SG_ 2365394770 Aft1OtltNOxSnsrNwPrtDviatNOxGain 1000;
BA_ "SPN" SG_ 2365394770 Aft1OtltNOxSnsrNwPrtDviatNOxGain 5032;
BA_ "GenSigStartValue" SG_ 2365394770 Aft1OtltNOxSnsrNPDviatNOxOffst 125;
BA_ "SPN" SG_ 2365394770 Aft1OtltNOxSnsrNPDviatNOxOffst 5033;
BA_ "SPN" SG_ 2365394770 Aftrtrtmnt1OtltNOxSensorOpHours 5721;
BA_ "SPN" SG_ 2365395025 Aft1IntkNOxSnsrO2PressCorrctn 5027;
BA_ "SPN" SG_ 2365395025 Aft1IntkNOxSnsrNOxPressCorrctn 5028;
BA_ "SPN" SG_ 2365395025 Aftrtrtmnt1IntkNOxSnsrNO2Corrctn 5029;
BA_ "SPN" SG_ 2365395025 Aftrtrtmnt1IntkNOxSnsrNH3Corrctn 5030;
BA_ "SPN" SG_ 2365395025 Aft1IntkNOxSnsrSelfDiagssFinalRs 5718;
BA_ "SPN" SG_ 2365395281 Aftrtrtmnt1IntkNOxSensorHtrRatio 5024;
BA_ "GenSigStartValue" SG_ 2365395281 Aft1IntkNOxSnsrNwPrtDviatNOxGain 1000;
BA_ "SPN" SG_ 2365395281 Aft1IntkNOxSnsrNwPrtDviatNOxGain 5025;
BA_ "GenSigStartValue" SG_ 2365395281 Aft1IntkNOxSnsrNPDviatNOxOffst 125;
BA_ "SPN" SG_ 2365395281 Aft1IntkNOxSnsrNPDviatNOxOffst 5026;
BA_ "SPN" SG_ 2365395281 Aftrtrtmnt1IntkNOxSensorOpHours 5722;
BA_ "GenSigStartValue" SG_ 2566757374 Aftrtrtmnt1DslExhstFldTemp2 40;
BA_ "SPN" SG_ 2566757374 Aftrtrtmnt1DslExhstFldTemp2 3515;
BA_ "SPN" SG_ 2566757374 Aft1DslExhstFldConcentration 3516;
BA_ "SPN" SG_ 2566757374 Aft1DslExhstFldConductivity 3518;
BA_ "SPN" SG_ 2566757374 Aft1DslExhstFldTemp2PrelimFMI 3519;
BA_ "SPN" SG_ 2566757374 Aft1DslExhstFldPropPrelimFMI 3520;
BA_ "SPN" SG_ 2566757374 Aftrtrtmnt1DslExhstFluidProperty 3521;
BA_ "GenSigStartValue" SG_ 2566771968 EngTurbo1ClclatdTurbineIntkTemp 8736;
BA_ "SPN" SG_ 2566771968 EngTurbo1ClclatdTurbineIntkTemp 2789;
BA_ "GenSigStartValue" SG_ 2566771968 EngTurbo1ClclatdTurbineOtltTemp 8736;
BA_ "SPN" SG_ 2566771968 EngTurbo1ClclatdTurbineOtltTemp 2790;
BA_ "SPN" SG_ 2566771968 EngExhstGasRecirc1Valve1Ctrl1 2791;
BA_ "SPN" SG_ 2566771968 EngVarGmtryTurboAirCtrlShtoffVlv 2792;
BA_ "SPN" SG_ 2566771968 EngineFuelControlMode 5323;
BA_ "SPN" SG_ 2566771968 EngVariableGmtryTurbo1CtrlMde 5457;
BA_ "SPN" SG_ 2566771968 EngVariableGmtryTurbo1ActrPos 2795;
BA_ "SPN" SG_ 2566802176 TransmissionTorqueLimit 1845;
BA_ "SPN" SG_ 2566803211 VDCInformationSignal 1813;
BA_ "SPN" SG_ 2566803211 VDCFullyOperational 1814;
BA_ "SPN" SG_ 2566803211 VDCBrakeLightRequest 1815;
BA_ "SPN" SG_ 2566803211 ROPEngineControlActive 1816;
BA_ "SPN" SG_ 2566803211 ROPBrakeControlActive 1818;
BA_ "SPN" SG_ 2566803211 YCEngineControlActive 1817;
BA_ "SPN" SG_ 2566803211 YCBrakeControlActive 1819;
BA_ "SPN" SG_ 2566803211 TrailerVDCActive 5624;
BA_ "SPN" SG_ 2365484270 Driver1WorkingState 1612;
BA_ "SPN" SG_ 2365484270 Driver2WorkingState 1613;
BA_ "SPN" SG_ 2365484270 VehicleMotion 1611;
BA_ "SPN" SG_ 2365484270 Driver1TimeRelatedStates 1617;
BA_ "SPN" SG_ 2365484270 DriverCard_Driver1 1615;
BA_ "SPN" SG_ 2365484270 VehicleOverspeed 1614;
BA_ "SPN" SG_ 2365484270 Driver2TimeRelatedStates 1618;
BA_ "SPN" SG_ 2365484270 DriverCard_Driver2 1616;
BA_ "SPN" SG_ 2365484270 SystemEvent 1622;
BA_ "SPN" SG_ 2365484270 HandlingInformation 1621;
BA_ "SPN" SG_ 2365484270 TachographPerformance 1620;
BA_ "SPN" SG_ 2365484270 DirectionIndicator 1619;
BA_ "SPN" SG_ 2365484270 TachographOutputShaftSpeed 1623;
BA_ "SPN" SG_ 2365484270 TachographVehicleSpeed 1624;
BA_ "SPN" SG_ 2298375691 FrontAxle_LeftWheelSpeed 1592;
BA_ "SPN" SG_ 2298375691 FrontAxle_RightWheelSpeed 1593;
BA_ "SPN" SG_ 2298375691 RearAxle_LeftWheelSpeed 1594;
BA_ "SPN" SG_ 2298375691 RearAxle_RightWheelSpeed 1595;
BA_ "GenSigStartValue" SG_ 2566818849 HydraulicOilTemperature 40;
BA_ "SPN" SG_ 2566818849 HydraulicOilTemperature 441;
BA_ "SPN" SG_ 2566818849 AuxiliaryPressure1 1387;
BA_ "SPN" SG_ 2566818849 AuxiliaryPressure2 1388;
BA_ "SPN" SG_ 2566818849 AuxiliaryLevel 3087;
BA_ "SPN" SG_ 2566818849 RelativeHumidity 354;
BA_ "SPN" SG_ 2566831883 FrontAxleSpeed 904;
BA_ "GenSigStartValue" SG_ 2566831883 RelativeSpeed_FrontAxl_LeftWheel 125;
BA_ "SPN" SG_ 2566831883 RelativeSpeed_FrontAxl_LeftWheel 905;
BA_ "GenSigStartValue" SG_ 2566831883 RelativeSpeed_FrntAxl_RightWheel 125;
BA_ "SPN" SG_ 2566831883 RelativeSpeed_FrntAxl_RightWheel 906;
BA_ "GenSigStartValue" SG_ 2566831883 RelativeSpeed_RearAxl1_LeftWheel 125;
BA_ "SPN" SG_ 2566831883 RelativeSpeed_RearAxl1_LeftWheel 907;
BA_ "GenSigStartValue" SG_ 2566831883 RelSpeed_RearAxl1_RightWheel 125;
BA_ "SPN" SG_ 2566831883 RelSpeed_RearAxl1_RightWheel 908;
BA_ "GenSigStartValue" SG_ 2566831883 RelativeSpeed_RearAxl2_LeftWheel 125;
BA_ "SPN" SG_ 2566831883 RelativeSpeed_RearAxl2_LeftWheel 909;
BA_ "GenSigStartValue" SG_ 2566831883 RelSpeed_RearAxl2_RightWheel 125;
BA_ "SPN" SG_ 2566831883 RelSpeed_RearAxl2_RightWheel 910;
BA_ "SPN" SG_ 2566832622 TotalVehicleDistance 917;
BA_ "SPN" SG_ 2566832622 TripDistance 918;
BA_ "SPN" SG_ 2566838561 AuxiliaryIO04 704;
BA_ "SPN" SG_ 2566838561 AuxiliaryIO03 703;
BA_ "SPN" SG_ 2566838561 AuxiliaryIO02 702;
BA_ "SPN" SG_ 2566838561 AuxiliaryIO01 701;
BA_ "SPN" SG_ 2566838561 AuxiliaryIO08 708;
BA_ "SPN" SG_ 2566838561 AuxiliaryIO07 707;
BA_ "SPN" SG_ 2566838561 AuxiliaryIO06 706;
BA_ "SPN" SG_ 2566838561 AuxiliaryIO05 705;
BA_ "SPN" SG_ 2566838561 AuxiliaryIO12 712;
BA_ "SPN" SG_ 2566838561 AuxiliaryIO11 711;
BA_ "SPN" SG_ 2566838561 AuxiliaryIO10 710;
BA_ "SPN" SG_ 2566838561 AuxiliaryIO09 709;
BA_ "SPN" SG_ 2566838561 AuxiliaryIO16 716;
BA_ "SPN" SG_ 2566838561 AuxiliaryIO15 715;
BA_ "SPN" SG_ 2566838561 AuxiliaryIO14 714;
BA_ "SPN" SG_ 2566838561 AuxiliaryIO13 713;
BA_ "SPN" SG_ 2566838561 AuxiliaryIOChannel1 1083;
BA_ "SPN" SG_ 2566838561 AuxiliaryIOChannel2 1084;
BA_ "SPN" SG_ 2566839296 EngineTotalIdleFuelUsed 236;
BA_ "SPN" SG_ 2566839296 EngineTotalIdleHours 235;
BA_ "SPN" SG_ 2566841600 EngineTotalHoursOfOperation 247;
BA_ "SPN" SG_ 2566841600 EngineTotalRevolutions 249;
BA_ "SPN" SG_ 2566842094 Seconds 959;
BA_ "SPN" SG_ 2566842094 Minutes 960;
BA_ "SPN" SG_ 2566842094 Hours 961;
BA_ "SPN" SG_ 2566842094 Month 963;
BA_ "SPN" SG_ 2566842094 Day 962;
BA_ "GenSigStartValue" SG_ 2566842094 Year -1985;
BA_ "SPN" SG_ 2566842094 Year 964;
BA_ "GenSigStartValue" SG_ 2566842094 LocalMinuteOffset 125;
BA_ "SPN" SG_ 2566842094 LocalMinuteOffset 1601;
BA_ "GenSigStartValue" SG_ 2566842094 LocalHourOffset 125;
BA_ "SPN" SG_ 2566842094 LocalHourOffset 1602;
BA_ "SPN" SG_ 2566842112 TotalVehicleHours 246;
BA_ "SPN" SG_ 2566842112 TotalPowerTakeoffHours 248;
BA_ "SPN" SG_ 2566843392 VehicleIdentificationNumber 237;
BA_ "SigType" SG_ 2566843392 VehicleIdentificationNumber 3;
BA_ "SPN" SG_ 2566843648 MaximumVehicleSpeedLimit 74;
BA_ "SPN" SG_ 2566843648 CruiseControlHighSetLimitSpeed 87;
BA_ "SPN" SG_ 2566843648 CruiseControlLowSetLimitSpeed 88;
BA_ "SPN" SG_ 2566843648 MaximumVehicleSpeedLimitHighReso 6808;
BA_ "SPN" SG_ 2566847511 WasherFluidLevel 80;
BA_ "SPN" SG_ 2566847511 FuelLevel1 96;
BA_ "SPN" SG_ 2566847511 EngineFuelFilterDiffPressure 95;
BA_ "SPN" SG_ 2566847511 EngineOilFilterDiffPressure 99;
BA_ "GenSigStartValue" SG_ 2566847511 CargoAmbientTemperature 8736;
BA_ "SPN" SG_ 2566847511 CargoAmbientTemperature 169;
BA_ "SPN" SG_ 2566847511 FuelLevel2 38;
BA_ "SPN" SG_ 2564816679 J1939Network1_PrmryVhclNetwork 639;
BA_ "SPN" SG_ 2564816679 J1922 622;
BA_ "SPN" SG_ 2564816679 J1587 608;
BA_ "SPN" SG_ 2564816679 CurrentDataLink 1230;
BA_ "SPN" SG_ 2564816679 Other_ManufacturerSpecifiedPort 1234;
BA_ "SPN" SG_ 2564816679 J1850 1233;
BA_ "SPN" SG_ 2564816679 ISO9141 1232;
BA_ "SPN" SG_ 2564816679 J1939Network2 1231;
BA_ "SPN" SG_ 2564816679 J1939Network4 1668;
BA_ "SPN" SG_ 2564816679 ProprietaryNetwork2 5588;
BA_ "SPN" SG_ 2564816679 ProprietaryNetwork1 625;
BA_ "SPN" SG_ 2564816679 J1939Network3 1235;
BA_ "SPN" SG_ 2564816679 SuspendSignal 2618;
BA_ "SPN" SG_ 2564816679 HoldSignal 1236;
BA_ "SPN" SG_ 2564816679 SuspendDuration 2619;
BA_ "SPN" SG_ 2564816929 EngineFan1RequestedPercentSpeed 986;
BA_ "GenSigStartValue" SG_ 2564816929 CabInteriorTemperatureCommand 8736;
BA_ "SPN" SG_ 2564816929 CabInteriorTemperatureCommand 1691;
BA_ "SPN" SG_ 2564816929 AuxHeaterCoolantPumpRequest 1684;
BA_ "SPN" SG_ 2564816929 BatteryMainSwitchHoldRequest 1682;
BA_ "SPN" SG_ 2564816929 OperatorSeatDirectionSwitch 1714;
BA_ "SPN" SG_ 2564816929 SeatBeltSwitch 1856;
BA_ "SPN" SG_ 2564816929 ParkBrakeCommand 5630;
BA_ "SPN" SG_ 2564816929 VehicleLmtngSpdGvrnrDecrementSw 1655;
BA_ "SPN" SG_ 2564816929 VehicleLmtngSpdGvrnrIncrementSw 1654;
BA_ "SPN" SG_ 2564816929 VehicleLmtngSpeedGvrnrEnblSwitch 1653;
BA_ "SPN" SG_ 2564816929 AftrtrtmntRegenInhbtSwitch 3695;
BA_ "SPN" SG_ 2564816929 AftrtrtmntRegenForceSwitch 3696;
BA_ "SPN" SG_ 2564816929 AutoGearShiftingEnableSwitch 1666;
BA_ "SPN" SG_ 2564816929 EngineAutomaticStartEnableSwitch 1656;
BA_ "SPN" SG_ 2564816929 AuxiliaryHeaterModeRequest 1683;
BA_ "SPN" SG_ 2564816929 RequestEngineZoneHeating 1685;
BA_ "SPN" SG_ 2564816929 RequestCabZoneHeating 1686;
BA_ "SPN" SG_ 2564816929 SelectedMaximumVehicleSpeedLimit 2596;
BA_ "GenSigStartValue" SG_ 2565869394 Aftertreatment1OutletNOx 4000;
BA_ "SPN" SG_ 2565869394 Aftertreatment1OutletNOx 3226;
BA_ "GenSigStartValue" SG_ 2565869394 Aftertreatment1OutletPercentO2 23346.3035019455;
BA_ "SPN" SG_ 2565869394 Aftertreatment1OutletPercentO2 3227;
BA_ "SPN" SG_ 2565869394 Aftrtrtmnt1OtltGasSensorPwrInRng 3228;
BA_ "SPN" SG_ 2565869394 Aftrtrtmnt1OtltGasSnsrAtTemp 3229;
BA_ "SPN" SG_ 2565869394 Aftrtrtmnt1OtltNOxReadingStable 3230;
BA_ "SPN" SG_ 2565869394 Aftrtrtmnt1OtltWdRngO2RdngStable 3231;
BA_ "SPN" SG_ 2565869394 Aft1OtltGasSnsrHtrPrelimFMI 3232;
BA_ "SPN" SG_ 2565869394 Aftrtrtmnt1OtltGasSensorHtrCtrl 3233;
BA_ "SPN" SG_ 2565869394 Aftrtrtmnt1OtltNOxSnsrPrelimFMI 3234;
BA_ "SPN" SG_ 2565869394 Aft1OtltNOxSnsrSelfDiagnssStat 5713;
BA_ "SPN" SG_ 2565869394 Aftrtrtmnt1OtltO2SensorPrelimFMI 3235;
BA_ "SPN" SG_ 2565668641 TotalMessageSize16 2557;
BA_ "SPN" SG_ 2565668641 TotalNumberOfPackets16 2558;
BA_ "SPN" SG_ 2565668641 MaximumNumberOfPackets 2559;
BA_ "SPN" SG_ 2565668641 PGNOfThePacketedMessage16 2560;
BA_ "SPN" SG_ 2565668641 NumberOfPacketsThatCanBeSent 2561;
BA_ "SPN" SG_ 2565668641 NextPacketNumberToBeSent 2562;
BA_ "SPN" SG_ 2565668641 PGNOfThePacketedMessage17 2563;
BA_ "SPN" SG_ 2565668641 TotalMessageSize19 2564;
BA_ "SPN" SG_ 2565668641 TotalNumberOfPackets19 2565;
BA_ "SPN" SG_ 2565668641 PGNOfThePacketedMessage19 2566;
BA_ "SPN" SG_ 2565668641 TotalMessageSize32 2567;
BA_ "SPN" SG_ 2565668641 TotalNumberOfPackets32 2568;
BA_ "SPN" SG_ 2565668641 PGNOfThePacketedMessage32 2569;
BA_ "SPN" SG_ 2565668641 ConnectionAbortReason 2570;
BA_ "SPN" SG_ 2565668641 ParameterGrpNoOfPacketedMessage 2571;
BA_ "SPN" SG_ 2564882192 EngineFan1RequestedPercentSpeed 986;
BA_ "GenSigStartValue" SG_ 2564882192 CabInteriorTemperatureCommand 8736;
BA_ "SPN" SG_ 2564882192 CabInteriorTemperatureCommand 1691;
BA_ "SPN" SG_ 2564882192 AuxHeaterCoolantPumpRequest 1684;
BA_ "SPN" SG_ 2564882192 BatteryMainSwitchHoldRequest 1682;
BA_ "SPN" SG_ 2564882192 OperatorSeatDirectionSwitch 1714;
BA_ "SPN" SG_ 2564882192 SeatBeltSwitch 1856;
BA_ "SPN" SG_ 2564882192 ParkBrakeCommand 5630;
BA_ "SPN" SG_ 2564882192 VehicleLmtngSpdGvrnrDecrementSw 1655;
BA_ "SPN" SG_ 2564882192 VehicleLmtngSpdGvrnrIncrementSw 1654;
BA_ "SPN" SG_ 2564882192 VehicleLmtngSpeedGvrnrEnblSwitch 1653;
BA_ "SPN" SG_ 2564882192 AftrtrtmntRegenInhbtSwitch 3695;
BA_ "SPN" SG_ 2564882192 AftrtrtmntRegenForceSwitch 3696;
BA_ "SPN" SG_ 2564882192 AutoGearShiftingEnableSwitch 1666;
BA_ "SPN" SG_ 2564882192 EngineAutomaticStartEnableSwitch 1656;
BA_ "SPN" SG_ 2564882192 AuxiliaryHeaterModeRequest 1683;
BA_ "SPN" SG_ 2564882192 RequestEngineZoneHeating 1685;
BA_ "SPN" SG_ 2564882192 RequestCabZoneHeating 1686;
BA_ "SPN" SG_ 2564882192 SelectedMaximumVehicleSpeedLimit 2596;
BA_ "GenSigStartValue" SG_ 2365457697 GeneratorTotalRealPower 2000000000;
BA_ "SPN" SG_ 2365457697 GeneratorTotalRealPower 2452;
BA_ "GenSigStartValue" SG_ 2365457697 GeneratorTotalApparentPower 2000000000;
BA_ "SPN" SG_ 2365457697 GeneratorTotalApparentPower 2460;
BA_ "SPN" SG_ 2348810251 EngineRequestedSpeedSpeedLimit 898;
BA_ "GenSigStartValue" SG_ 2348810251 EngineRequestedTorqueTorqueLimit 125;
BA_ "SPN" SG_ 2348810251 EngineRequestedTorqueTorqueLimit 518;
BA_ "SPN" SG_ 2348810251 TSC1TransmissionRate 3349;
BA_ "SPN" SG_ 2348810251 TSC1ControlPurpose 3350;
BA_ "SPN" SG_ 2348810251 EngineRequestedTorque 4191;
BA_ "SPN" SG_ 2348810251 MessageCounter 4206;
BA_ "SPN" SG_ 2348810251 MessageChecksum 4207;
BA_ "GenSigStartValue" SG_ 2566834691 FECA_Byte8 255;
BA_ "GenSigStartValue" SG_ 2566834691 FECA_Byte7 255;
BA_ "GenSigStartValue" SG_ 2566834691 FECA_SPNConversionMethod 1;
BA_ "GenSigStartValue" SG_ 2566834691 FECA_OccurrenceCount 127;
BA_ "GenSigStartValue" SG_ 2566834691 FECA_SPNMSBits 7;
BA_ "GenSigStartValue" SG_ 2566834691 FECA_FMI 31;
BA_ "GenSigStartValue" SG_ 2566834691 FECA_SPNLSBits 255;
BA_ "GenSigStartValue" SG_ 2566834691 FECA_FlashMalfuncIndicatorLamp 3;
BA_ "GenSigStartValue" SG_ 2566834691 FECA_FlashRedStopLamp 3;
BA_ "GenSigStartValue" SG_ 2566834691 FECA_FlashAmberWarningLamp 3;
BA_ "GenSigStartValue" SG_ 2566834691 FECA_FlashProtectLamp 3;
BA_ "GenSigStartValue" SG_ 2566834691 FECA_MalfunctionIndLampStatus 3;
BA_ "GenSigStartValue" SG_ 2566834691 FECA_RedStopLampStatus 3;
BA_ "GenSigStartValue" SG_ 2566834691 FECA_AmberWarningLampStatus 3;
BA_ "GenSigStartValue" SG_ 2566834691 FECA_ProtectLampStatus 3;
BA_ "GenSigStartValue" SG_ 2566834947 FECB_RedStopLampStatus 3;
BA_ "GenSigStartValue" SG_ 2566834947 FECB_SPNConversionMethod 1;
BA_ "GenSigStartValue" SG_ 2566834947 FECB_OccurrenceCount 126;
BA_ "GenSigStartValue" SG_ 2566834947 FECB_FMI 31;
BA_ "GenSigStartValue" SG_ 2566834947 FECB_SPN_LSByte 255;
BA_ "GenSigStartValue" SG_ 2566834947 FECB_SPN_MByte 7;
BA_ "GenSigStartValue" SG_ 2566834947 FECB_MalfunctionIndLampStatus 3;
BA_ "SPN" SG_ 2565865761 ASREngineControlActive 561;
BA_ "SPN" SG_ 2565865761 ASRBrakeControlActive 562;
BA_ "SPN" SG_ 2565865761 AntiLockBrakingActive 563;
BA_ "SPN" SG_ 2565865761 EBSBrakeSwitch 1121;
BA_ "SPN" SG_ 2565865761 BrakePedalPosition 521;
BA_ "SPN" SG_ 2565865761 ABSOffRoadSwitch 575;
BA_ "SPN" SG_ 2565865761 ASROffRoadSwitch 576;
BA_ "SPN" SG_ 2565865761 ASRHillHolderSwitch 577;
BA_ "SPN" SG_ 2565865761 TractionControlOverrideSwitch 1238;
BA_ "SPN" SG_ 2565865761 AcceleratorInterlockSwitch 972;
BA_ "SPN" SG_ 2565865761 EngineDerateSwitch 971;
BA_ "SPN" SG_ 2565865761 EngineAuxiliaryShutdownSwitch 970;
BA_ "SPN" SG_ 2565865761 RemoteAcceleratorEnableSwitch 969;
BA_ "SPN" SG_ 2565865761 EngineRetarderSelection 973;
BA_ "SPN" SG_ 2565865761 ABSFullyOperational 1243;
BA_ "SPN" SG_ 2565865761 EBSRedWarningSignal 1439;
BA_ "SPN" SG_ 2565865761 ABSEBSAmberWarningSignal 1438;
BA_ "SPN" SG_ 2565865761 ATCASRInformationSignal 1793;
BA_ "SPN" SG_ 2565865761 SrcAddrOfCtrllingDevForBrkCtrl 1481;
BA_ "SPN" SG_ 2565865761 RailroadModeSwitch 7941;
BA_ "SPN" SG_ 2565865761 HaltBrakeSwitch 2911;
BA_ "SPN" SG_ 2565865761 TrailerABSStatus 1836;
BA_ "SPN" SG_ 2565865761 TractorMntdTrailerABSWarningSig 1792;
BA_ "GenSigStartValue" SG_ 2231329825 ZFIMP_BucketPosition 125;
BA_ "GenSigStartValue" SG_ 2231329825 ZFIMP_BoomPosition 125;
BA_ "GenSigStartValue" SG_ 2566856451 FF1F_SumpTemp 50;
BA_ "GenSigStartValue" SG_ 2566856451 FF1F_TorqueConTemp 50;
BA_ "GenSigStartValue" SG_ 2566260325 Fuel_Temp 40;
BA_ "GenSigStartValue" SG_ 2365527841 FF17_JystkPos 1000;
BA_ "GenSigStartValue" SG_ 2365527841 FF17_JystkNPosTrm 200;
BA_ "GenSigStartValue" SG_ 2365527585 FF16_JystkPos 1000;
BA_ "GenSigStartValue" SG_ 2365527585 FF16_JystkNPosTrm 200;
VAL_ 2566749184 DieselParticulateFilterLampCmd 0 "Off" 1 "On - solid" 2 "reserved for SAE assignment " 3 "reserved for SAE assignment" 4 "On - fast blink (1 HZ)" 5 "reserved for SAE assignment" 6 "reserved for SAE assignment" 7 "not available" ;
VAL_ 2566749184 AftrtrtmntDslPFActvRegenStatus 0 "not active" 1 "active" 2 "regeneration needed" 3 "not available" ;
VAL_ 2566749184 AftrtrtmntDslPFStatus 0 "Regeneration not needed" 1 "Regeneration needed - lowest level" 2 "Regeneration needed - moderate level" 3 "Regeneration needed - highest level" 4 "reserved for SAE assignment" 5 "reserved for SAE assignment" 6 "reserved for SAE assignment" 7 "not available" ;
VAL_ 2566749184 DslPFActvRegenInhbtdStatus 0 "not inhibited" 1 "inhibited" 2 "reserved for SAE assignment" 3 "not available" ;
VAL_ 2566749184 DslPFActvRegenInhbtdDTInhbtSw 0 "not inhibited" 1 "inhibited" 2 "reserved for SAE assignment" 3 "not available" ;
VAL_ 2566749184 DslPFActRegenInhbtdDTCltchDiseng 0 "not inhibited" 1 "inhibited" 2 "reserved for SAE assignment" 3 "not available" ;
VAL_ 2566749184 DslPFActRegenInhbtdDTSrvcBrkActv 0 "not inhibited" 1 "inhibited" 2 "reserved for SAE assignment" 3 "not available" ;
VAL_ 2566749184 DslPFActvRegenInhbtdDTPTOActv 0 "not inhibited" 1 "inhibited" 2 "reserved for SAE assignment" 3 "not available" ;
VAL_ 2566749184 DPFActRegenInhbtdDTAcclPdlOffIdl 0 "not inhibited" 1 "inhibited" 2 "reserved for SAE assignment" 3 "not available" ;
VAL_ 2566749184 DslPFActvRegenInhbtdDTOutOfNtrl 0 "not inhibited" 1 "inhibited" 2 "reserved for SAE assignment" 3 "not available" ;
VAL_ 2566749184 DPFActRegInhDTVhclSpdAbvAllwdSpd 0 "not inhibited" 1 "inhibited" 2 "reserved for SAE assignment" 3 "not available" ;
VAL_ 2566749184 DPFActRegenInhbtdDTPrkBrkNotSet 0 "not inhibited" 1 "inhibited" 2 "reserved for SAE assignment" 3 "not available" ;
VAL_ 2566749184 DPFActRegenInhbtdDTLowExhstTemp 0 "not inhibited" 1 "inhibited" 2 "reserved for SAE assignment" 3 "not available" ;
VAL_ 2566749184 DslPFActRegenInhbtdDTSysFaultAct 0 "not inhibited" 1 "inhibited" 2 "reserved for SAE assignment" 3 "not available" ;
VAL_ 2566749184 DslPFActvRegenInhbtdDTSysTimeout 0 "not inhibited" 1 "inhibited" 2 "reserved for SAE assignment" 3 "not available" ;
VAL_ 2566749184 DPFActRegenInhbtdDTTmprySysLckt 0 "not inhibited" 1 "inhibited" 2 "reserved for SAE assignment" 3 "not available" ;
VAL_ 2566749184 DPFActRegenInhbtdDTPrmntSysLckt 0 "not inhibited" 1 "inhibited" 2 "reserved for SAE assignment" 3 "not available" ;
VAL_ 2566749184 DPFActRegInhbtdDTEngNotWarmedUp 0 "not inhibited" 1 "inhibited" 2 "reserved for SAE assignment" 3 "not available" ;
VAL_ 2566749184 DPFActRegInhDTVhclSpdBlwAllwdSpd 0 "not inhibited" 1 "inhibited" 2 "reserved for SAE assignment" 3 "not available" ;
VAL_ 2566749184 DslPFAutoActvRegenInitConf 0 "not enabled" 1 "enabled" 2 "reserved for SAE assignment" 3 "not available" ;
VAL_ 2566749184 ExhstSystemHghTemperatureLampCmd 0 "Off" 1 "On - solid " 2 "reserved for SAE assignment " 3 "reserved for SAE assignment" 4 "reserved for SAE assignment" 5 "reserved for SAE assignment" 6 "reserved for SAE assignment" 7 "not available" ;
VAL_ 2566749184 DslPFActvRegenForcedStatus 0 "Not Active" 1 "Active - Forced by Switch (See SPN 3696)" 2 "Active - Forced by Service Tool " 3 "Reserved for SAE Assignment" 4 "Reserved for SAE Assignment" 5 "Reserved for SAE Assignment" 6 "Reserved for SAE Assignment" 7 "not available" ;
VAL_ 2566749184 HydrocarbonDoserPurgingEnable 0 "Purging not enabled" 1 "Purging enabled" 2 "Purging enabled" 3 "Not available" ;
VAL_ 2566749184 DPFActRegenInhbtdDTLowExhstPress 0 "not inhibited" 1 "inhibited" 2 "reserved for SAE assignment" 3 "not available" ;
VAL_ 2566749184 Aft1DPFConditionsNotMetForActReg 0 "active DPF regeneration not inhibited" 1 "active DPF regeneration inhibited" 2 "reserved for SAE assignment" 3 "not available" ;
VAL_ 2566831360 FanDriveState 0 "Fan off" 1 "Engine system-General" 2 "Excessive engine air temperature" 3 "Excessive engine oil temperature" 4 "Excessive engine coolant temperature" 5 "Excessive transmission oil temperature" 6 "Excessive hydraulic oil temperature" 7 "Default Operation" 8 "Reverse Operation" 9 "Manual control" 10 "Transmission retarder" 11 "A/C system" 12 "Timer" 13 "Engine brake" 14 "Other" 15 "Not available" ;
VAL_ 2566883328 UreaLevelBuzzer 1 "Buzzer On" 0 "Buzzer Off" ;
VAL_ 2566883328 EmissionObdInducementState 15 "Not available" 14 "Error" 4 "Lamp fast blinking" 3 "Lamp slow blinking" 2 "Lamp On (FId_ComIndcLvl1)" 0 "Lamp Off" ;
VAL_ 2566883328 UreaLevelInducementState 6 "Error" 4 "Urea Level Fast Blinking" 2 "Urea Level Lamp Slow Blinking" 1 "Urea Level Lamp On" 0 "Urea Level Lamp Off" ;
VAL_ 2566883328 EmissionObdInducementFailureReas 8 "Nox Failure" 4 "Monitor Failure" 2 "Urea Quality Error" 1 "Dosing Error" 0 "No failure" ;
VAL_ 2348875776 TransmissionGearShiftInhbtRq 0 "Gear shifts are allowed" 1 "Gear shifts are inhibited" 2 "Reserved" 3 "Take no action" ;
VAL_ 2348875776 TrnsmTrqCnvLockupDisableRq 0 "Allow torque converter lockup" 1 "Disable torque converter lockup" 2 "Reserved" 3 "Take no action" ;
VAL_ 2348875776 DisengageDrivelineRequest 0 "Allow driveline engagement" 1 "Disengage driveline" 2 "Reserved" 3 "Take no action" ;
VAL_ 2348875776 TrnsmReverseGearShftInhbtRq 0 "Allow shifts into Reverse gear" 1 "Inhibit shifts into Reverse gear" 2 "Reserved " 3 "Take no action" ;
VAL_ 2348875776 TransmissionRequestedGear 253 "Hold current gear" 252 "Forward Drive Position" 251 "'Park' position" 250 "Forward 'Low' position" 249 "Upshift 1 gear from current position" 248 "Upshift 2 gears from current position" 247 "Downshift 1 gear from current position" 246 "Downshift 2 gears from current position" 245 "D-1: 1st forward selector position" 244 "D-2: 2nd forward selector position" 243 "D-3: 3rd forward selector position" 242 "D-4: 4th forward selector position" 241 "D-5: 5th forward selector position" 240 "D-6: 6th forward selector position" 239 "D-7: 7th forward selector position" 238 "Between two shift selector positions" 237 "Between two reverse shift selector positions" 236 "Between two forward shift selector positions" 235 "Between D-7 and D-6 shift selector positions" 234 "Between D-6 and D-5 shift selector positions" 233 "Between D-5 and D-4 shift selector positions" 232 "Between D-4 and D-3 shift selector positions" 231 "Between D-3 and D-2 shift selector positions" 230 "Between D-2 and D-1 shift selector positions" 229 "Between D-1 and 'Drive' shift selector positions" 228 "Between 'Drive' and 'Neutral' shift selector positions" 227 "Between 'Neutral' and 'Reverse' shift selector positions" 226 "Between 'Reverse' and 'Park' shift selector positions" 225 "Press of momentary button to reselect current position" 224 "Position unknown and/or no buttons pressed" 223 "Reverse Selector Position" 60 "Reserved" ;
VAL_ 2348875776 DisengiffLockRequestFrontAxl1 0 "Engage differential lock" 1 "Disengage differential lock" 2 "Reserved" 3 "Take no action" ;
VAL_ 2348875776 DisengiffLockRequestFrontAxl2 0 "Engage differential lock" 1 "Disengage differential lock" 2 "Reserved" 3 "Take no action" ;
VAL_ 2348875776 DisengageDiffLockRequestRearAxl1 0 "Engage differential lock" 1 "Disengage differential lock" 2 "Reserved" 3 "Take no action" ;
VAL_ 2348875776 DisengageDiffLockRequestRearAxl2 0 "Engage differential lock" 1 "Disengage differential lock" 2 "Reserved" 3 "Take no action" ;
VAL_ 2348875776 DisengageDiffLockRequestCentral 0 "Engage differential lock" 1 "Disengage differential lock" 2 "Reserved" 3 "Take no action" ;
VAL_ 2348875776 DisengiffLockRequestCentralFront 0 "Engage differential lock" 1 "Disengage differential lock" 2 "Reserved" 3 "Take no action" ;
VAL_ 2348875776 DisengiffLockRequestCentralRear 0 "Engage differential lock" 1 "Disengage differential lock" 2 "Reserved" 3 "Take no action" ;
VAL_ 2348875776 TransmissionLoadRedInhbtRequest 0 "Allow or resume transmission" 1 "Inhibit or abort transmission" 2 "Reserved" 3 "Don't care/take no action" ;
VAL_ 2348875776 TransmissionMode1 0 "Disable" 1 "Enable" 2 "Reserved" 3 "Take no action" ;
VAL_ 2348875776 TransmissionMode2 0 "Disable" 1 "Enable" 2 "Reserved" 3 "Take no action" ;
VAL_ 2348875776 TransmissionMode3 0 "Disable" 1 "Enable" 2 "Reserved" 3 "Take no action" ;
VAL_ 2348875776 TransmissionMode4 0 "Disable" 1 "Enable" 2 "Reserved" 3 "Take no action" ;
VAL_ 2348875776 TransmissionRequestedLaunchGear 0 "No specific launch gear requested" 1 "Launch the vehicle in 1st gear" 2 "Launch the vehicle in 2nd gear" 3 "Launch the vehicle in 3rd gear" 4 "Launch the vehicle in 4th gear" 5 "Launch the vehicle in 5th gear" 6 "Launch the vehicle in 6th gear" 7 "Launch the vehicle in 7th gear" 8 "Launch the vehicle in 8th gear" 9 "Launch the vehicle in Reverse 1" 10 "Launch the vehicle in Reverse 2" 11 "Launch the vehicle in Reverse 3" 12 "Launch the vehicle in Reverse 4 " 13 "Allow transmission to select the optimum launch gear" 14 "Error" 15 "Not Available" ;
VAL_ 2348875776 TrnsmShftSlctorDisplayMdeSw 0 "Off" 1 "One" 2 "Error" 3 "Not available" ;
VAL_ 2348875776 TransmissionMode5 0 "Disable" 1 "Enable" 2 "Reserved" 3 "Take no action" ;
VAL_ 2348875776 TransmissionMode6 0 "Disable" 1 "Enable" 2 "Reserved" 3 "Take no action" ;
VAL_ 2348875776 TransmissionMode7 0 "Disable" 1 "Enable" 2 "Reserved" 3 "Take no action" ;
VAL_ 2348875776 TransmissionMode8 0 "Disable" 1 "Enable" 2 "Reserved" 3 "Take no action" ;
VAL_ 2565668669 ECU_TPCM_SA3D_Mux 16 "RTS" 17 "CTS" 19 "EoM_ACK" 32 "BAM" 255 "ConnAbort" ;
VAL_ 2566804993 AftSlctiveCtlytcRedOprtrIndcmntA 0 "Off" 1 "On solid" 2 "reserved for SAE assignment" 3 "reserved for SAE assignment" 4 "On fast blink (1 Hz)" 5 "reserved for SAE assignment" 6 "reserved for SAE assignment" 7 "not available" ;
VAL_ 2566804993 AftrtrtmntSCROprtrIndcmntSvrty 0 "Driver Warning" 1 "Inducement Level 1" 2 "Inducement Level 2" 3 "Inducement Level 3" 4 "Inducement Level 4" 5 "Inducement Level 5" 6 "Temporary Override of Inducement" 7 "Not Available / Not Supported" ;
VAL_ 2565869137 Aftrtrtmnt1IntkGasSensorPwrInRng 0 "Not in range" 1 "In range" 2 "Error" 3 "Not available" ;
VAL_ 2565869137 Aftrtrtmnt1IntkGasSnsrAtTemp 0 "Not in range" 1 "In range" 2 "Error" 3 "Not available" ;
VAL_ 2565869137 Aft1SlctiveCtlytcRedIntkNOxRdngS 0 "Not stable" 1 "Stable" 2 "Error" 3 "Not available" ;
VAL_ 2565869137 Aft1IntkWdRngPrcntO2RdngStable 0 "Not stable" 1 "Stable" 2 "Error" 3 "Not available" ;
VAL_ 2565869137 Aftrtrtmnt1IntkGasSensorHtrCtrl 0 "Automatic" 1 "Preheat 2" 2 "Preheat 1" 3 "Heater off" ;
VAL_ 2565869137 Aft1IntkNOxSnsrSelfDiagnssStat 0 "Diagnosis not active" 1 "NOx Sensor ATI1 Self Diagnosis active flag" 2 "NOx Sensor ATI1 Self Diagnosis Result Complete" 3 "NOx Sensor ATI1 Self Diagnosis aborted" 4 "NOx Sensor ATI1 Self Diagnosis not possible" 7 "Not Supported" ;
VAL_ 2566757374 Aftrtrtmnt1DslExhstFluidProperty 0 "Urea concentration too high" 1 "Urea concentration too low" 2 "Fluid is diesel" 3 "Diesel exhaust fluid is proper mixture" 13 "Fluid type unknown" 14 "Fluid property detection error" 15 "Not available" ;
VAL_ 2566771968 EngVarGmtryTurboAirCtrlShtoffVlv 0 "VGT Air Control Shutoff Valve is Off" 1 "VGT Air Control Shutoff Valve is On" 2 "Reserved" 3 "Not available" ;
VAL_ 2566771968 EngineFuelControlMode 0 "Open loop" 1 "Closed loop" 2 "SAE reserved" 3 "Not available" ;
VAL_ 2566771968 EngVariableGmtryTurbo1CtrlMde 0 "Open loop" 1 "Closed loop" 2 "SAE reserved" 3 "Not available" ;
VAL_ 2566803211 VDCInformationSignal 0 "Off" 1 "On" 2 "Reserved" 3 "Don't care/take no action" ;
VAL_ 2566803211 VDCFullyOperational 0 "Not fully operational" 1 "Fully operational" 2 "Reserved" 3 "Don't care/Take no action" ;
VAL_ 2566803211 VDCBrakeLightRequest 0 "Turn brake light not on" 1 "Turn brake light on" 2 "Reserved" 3 "Don't care/Take no action" ;
VAL_ 2566803211 ROPEngineControlActive 0 "ROP engine control passive but installed" 1 "ROP engine control active" 2 "Reserved" 3 "Don't care/Take no action" ;
VAL_ 2566803211 ROPBrakeControlActive 0 "ROP brake control passive but installed" 1 "ROP brake control active" 2 "Reserved" 3 "Don't care/Take no action" ;
VAL_ 2566803211 YCEngineControlActive 0 "YC engine control passive but installed" 1 "YC engine control active" 2 "Reserved" 3 "Don't care/Take no action" ;
VAL_ 2566803211 YCBrakeControlActive 0 "YC brake control passive but installed" 1 "YC brake control active" 2 "Reserved" 3 "Don't care/Take no action" ;
VAL_ 2566803211 TrailerVDCActive 0 "VDC passive, but installed" 1 "VDC active" 2 "Reserved" 3 "Not availble or not installed" ;
VAL_ 2365484270 Driver1WorkingState 0 "Rest" 1 "Driver available" 2 "Work" 3 "Drive" 6 "Error" 7 "Not available" ;
VAL_ 2365484270 Driver2WorkingState 0 "Rest" 1 "Driver available" 2 "Work" 3 "Drive" 6 "Error" 7 "Not available" ;
VAL_ 2365484270 VehicleMotion 0 "Vehicle motion not detected" 1 "Vehicle motion detected" 2 "Error" 3 "Not available" ;
VAL_ 2365484270 Driver1TimeRelatedStates 0 "Normal/No limits reached" 1 "Limit #1 - 15 min before 4 ,5 h" 2 "Limit #2 - 4 ,5 h reached" 3 "Limit #3 - 15 min before 9 h" 4 "Limit #4 - 9 h reached" 5 "Limit #5 - 15 min before 16 h" 6 "Limit #6 - 16 h reached" 13 "Other" 14 "Error" 15 "Not available" ;
VAL_ 2365484270 DriverCard_Driver1 0 "Driver card not present" 1 "Driver card present" 2 "Error" 3 "Not available" ;
VAL_ 2365484270 VehicleOverspeed 0 "No overspeed" 1 "Overspeed" 2 "Error" 3 "Not available" ;
VAL_ 2365484270 Driver2TimeRelatedStates 0 "Normal/No limits reached" 1 "Limit #1 - 15 min before 4 ,5 h" 2 "Limit #2 - 4 ,5 h reached" 3 "Limit #3 - 15 min before 9 h" 4 "Limit #4 - 9 h reached" 5 "Limit #5 - 15 min before 16 h" 6 "Limit #6 - 16 h reached" 13 "Other" 14 "Error" 15 "Not available" ;
VAL_ 2365484270 DriverCard_Driver2 0 "Driver card not present" 1 "Driver card present" 2 "Error" 3 "Not available" ;
VAL_ 2365484270 SystemEvent 0 "No tachograph event" 1 "Tachograph event" 2 "Error" 3 "Not available" ;
VAL_ 2365484270 HandlingInformation 0 "No handling information" 1 "Handling information" 2 "Error" 3 "Not available" ;
VAL_ 2365484270 TachographPerformance 0 "Normal performance" 1 "Performance analysis" 2 "Error" 3 "Not available" ;
VAL_ 2365484270 DirectionIndicator 0 "Forward" 1 "Reverse" 2 "Error" 3 "Not available" ;
VAL_ 2566838561 AuxiliaryIO04 0 "Auxiliary channel off" 1 "Auxiliary channel on" 2 "Error" 3 "Not available" ;
VAL_ 2566838561 AuxiliaryIO03 0 "Auxiliary channel off" 1 "Auxiliary channel on" 2 "Error" 3 "Not available" ;
VAL_ 2566838561 AuxiliaryIO02 0 "Auxiliary channel off" 1 "Auxiliary channel on" 2 "Error" 3 "Not available" ;
VAL_ 2566838561 AuxiliaryIO01 0 "Auxiliary channel off" 1 "Auxiliary channel on" 2 "Error" 3 "Not available" ;
VAL_ 2566838561 AuxiliaryIO08 0 "Auxiliary channel off" 1 "Auxiliary channel on" 2 "Error" 3 "Not available" ;
VAL_ 2566838561 AuxiliaryIO07 0 "Auxiliary channel off" 1 "Auxiliary channel on" 2 "Error" 3 "Not available" ;
VAL_ 2566838561 AuxiliaryIO06 0 "Auxiliary channel off" 1 "Auxiliary channel on" 2 "Error" 3 "Not available" ;
VAL_ 2566838561 AuxiliaryIO05 0 "Auxiliary channel off" 1 "Auxiliary channel on" 2 "Error" 3 "Not available" ;
VAL_ 2566838561 AuxiliaryIO12 0 "Auxiliary channel off" 1 "Auxiliary channel on" 2 "Error" 3 "Not available" ;
VAL_ 2566838561 AuxiliaryIO11 0 "Auxiliary channel off" 1 "Auxiliary channel on" 2 "Error" 3 "Not available" ;
VAL_ 2566838561 AuxiliaryIO10 0 "Auxiliary channel off" 1 "Auxiliary channel on" 2 "Error" 3 "Not available" ;
VAL_ 2566838561 AuxiliaryIO09 0 "Auxiliary channel off" 1 "Auxiliary channel on" 2 "Error" 3 "Not available" ;
VAL_ 2566838561 AuxiliaryIO16 0 "Auxiliary channel off" 1 "Auxiliary channel on" 2 "Error" 3 "Not available" ;
VAL_ 2566838561 AuxiliaryIO15 0 "Auxiliary channel off" 1 "Auxiliary channel on" 2 "Error" 3 "Not available" ;
VAL_ 2566838561 AuxiliaryIO14 0 "Auxiliary channel off" 1 "Auxiliary channel on" 2 "Error" 3 "Not available" ;
VAL_ 2566838561 AuxiliaryIO13 0 "Auxiliary channel off" 1 "Auxiliary channel on" 2 "Error" 3 "Not available" ;
VAL_ 2564816679 J1939Network1_PrmryVhclNetwork 0 "Stop Broadcast" 1 "Start Broadcast" 2 "Reserved" 3 "Don't Care/take no action (leave as is)" ;
VAL_ 2564816679 J1922 0 "Stop Broadcast" 1 "Start Broadcast" 2 "Reserved" 3 "Don't Care/take no action (leave as is)" ;
VAL_ 2564816679 J1587 0 "Stop Broadcast" 1 "Start Broadcast" 2 "Reserved" 3 "Don't Care/take no action (leave as is)" ;
VAL_ 2564816679 CurrentDataLink 0 "Stop Broadcast" 1 "Start Broadcast" 2 "Reserved" 3 "Don't Care/take no action (leave as is)" ;
VAL_ 2564816679 Other_ManufacturerSpecifiedPort 0 "Stop Broadcast" 1 "Start Broadcast" 2 "Reserved" 3 "Don't Care/take no action (leave as is)" ;
VAL_ 2564816679 J1850 0 "Stop Broadcast" 1 "Start Broadcast" 2 "Reserved" 3 "Don't Care/take no action (leave as is)" ;
VAL_ 2564816679 ISO9141 0 "Stop Broadcast" 1 "Start Broadcast" 2 "Reserved" 3 "Don't Care/take no action (leave as is)" ;
VAL_ 2564816679 J1939Network2 0 "Stop Broadcast" 1 "Start Broadcast" 2 "Reserved" 3 "Don't Care/take no action (leave as is)" ;
VAL_ 2564816679 J1939Network4 0 "Stop Broadcast" 1 "Start Broadcast" 2 "Reserved" 3 "Don't Care/take no action (leave as is)" ;
VAL_ 2564816679 ProprietaryNetwork2 0 "Stop Broadcast" 1 "Start Broadcast" 2 "Reserved" 3 "Don't Care/take no action (leave as is)" ;
VAL_ 2564816679 ProprietaryNetwork1 0 "Stop Broadcast" 1 "Start Broadcast" 2 "Reserved" 3 "Don't Care/take no action (leave as is)" ;
VAL_ 2564816679 J1939Network3 0 "Stop Broadcast" 1 "Start Broadcast" 2 "Reserved" 3 "Don't Care/take no action (leave as is)" ;
VAL_ 2564816679 SuspendSignal 0 "Indefinite suspension of all broadcasts" 1 "Indefinite suspension of some messages" 2 "Temporary suspension of all broadcasts" 3 "Temporary suspension of some messages" 14 "Resuming normal broadcast pattern" 15 "Not Available" ;
VAL_ 2564816679 HoldSignal 0 "All Devices" 1 "Devices whose broadcast state has been modified" 15 "Not Available" ;
VAL_ 2564816929 AuxHeaterCoolantPumpRequest 0 "Deactivate water pump" 1 "Activate water pump" 2 "Reserved" 3 "Don't care/take no action" ;
VAL_ 2564816929 BatteryMainSwitchHoldRequest 0 "Release Battery Main Switch" 1 "Hold Battery Main Switch" 2 "undefined" 3 "Don't care/take no action" ;
VAL_ 2564816929 OperatorSeatDirectionSwitch 0 "Operator seat not facing forward" 1 "Operator seat is facing forward" 2 "Error" 3 "Not Available" ;
VAL_ 2564816929 SeatBeltSwitch 0 "NOT Buckled" 1 "OK - Seat Belt is buckled" 2 "Error - Switch state cannot be determined" 3 "Not Available" ;
VAL_ 2564816929 ParkBrakeCommand 0 "Park Brake apply not requested" 1 "Park Brake apply requested" 2 "SAE Reserved  " 3 "Don't care/Take no action" ;
VAL_ 2564816929 VehicleLmtngSpdGvrnrDecrementSw 0 "Switch in the off state" 1 "Switch in the on state - decrease" 2 "Error" 3 "Not available" ;
VAL_ 2564816929 VehicleLmtngSpdGvrnrIncrementSw 0 "Switch in the off state" 1 "Switch in the on state - increase" 2 "Error" 3 "Not available" ;
VAL_ 2564816929 VehicleLmtngSpeedGvrnrEnblSwitch 0 "Switch disabled" 1 "Switched enabled" 2 "Error" 3 "Not available" ;
VAL_ 2564816929 AftrtrtmntRegenInhbtSwitch 0 "not active" 1 "active" 2 "error" 3 "not available" ;
VAL_ 2564816929 AftrtrtmntRegenForceSwitch 0 "not active" 1 "active" 2 "error" 3 "not available" ;
VAL_ 2564816929 AutoGearShiftingEnableSwitch 0 "Automated Gear Shifting is disabled" 1 "Automated Gear Shifting is enabled" 2 "error" 3 "Not available" ;
VAL_ 2564816929 EngineAutomaticStartEnableSwitch 0 "Switch in the off state" 1 "Switch in the on state" 2 "Error" 3 "Not available" ;
VAL_ 2564816929 AuxiliaryHeaterModeRequest 0 "De-activate auxiliary heater" 1 "Off due to ADR" 2 "Economy mode" 3 "Normal mode" 4 "Heater pump up-keep" 14 "Reserved" 15 "Don't care" ;
VAL_ 2564816929 RequestEngineZoneHeating 0 "Do not heat engine zone" 1 "Heat engine zone" 2 "Reserved" 3 "Don't care/take no action" ;
VAL_ 2564816929 RequestCabZoneHeating 0 "Do not heat cab engine zone" 1 "Heat cab zone" 2 "Reserved" 3 "Don't care/take no action" ;
VAL_ 2565869394 Aftrtrtmnt1OtltGasSensorPwrInRng 0 "Not in range" 1 "In range" 2 "Error" 3 "Not available" ;
VAL_ 2565869394 Aftrtrtmnt1OtltGasSnsrAtTemp 0 "Not in range" 1 "In range" 2 "Error" 3 "Not available" ;
VAL_ 2565869394 Aftrtrtmnt1OtltNOxReadingStable 0 "Not stable" 1 "Stable" 2 "Error" 3 "Not available" ;
VAL_ 2565869394 Aftrtrtmnt1OtltWdRngO2RdngStable 0 "Not stable" 1 "Stable" 2 "Error" 3 "Not available" ;
VAL_ 2565869394 Aftrtrtmnt1OtltGasSensorHtrCtrl 0 "Automatic" 1 "Preheat 2" 2 "Preheat 1" 3 "Heater off" ;
VAL_ 2565869394 Aft1OtltNOxSnsrSelfDiagnssStat 0 "Diagnosis not active" 1 "NOx Sensor ATO1 Self Diagnosis active flag" 2 "NOx Sensor ATO1 Self Diagnosis Result Complete" 3 "NOx Sensor ATO1 Self Diagnosis aborted" 4 "NOx Sensor ATO1 Self Diagnosis not possible" 7 "Not Supported" ;
VAL_ 2565668641 VCU_BAM_REX_Mux 16 "RTS" 17 "CTS" 19 "EoM_ACK" 32 "BAM" 255 "ConnAbort" ;
VAL_ 2564882192 AuxHeaterCoolantPumpRequest 0 "Deactivate water pump" 1 "Activate water pump" 2 "Reserved" 3 "Don't care/take no action" ;
VAL_ 2564882192 BatteryMainSwitchHoldRequest 0 "Release Battery Main Switch" 1 "Hold Battery Main Switch" 2 "undefined" 3 "Don't care/take no action" ;
VAL_ 2564882192 OperatorSeatDirectionSwitch 0 "Operator seat not facing forward" 1 "Operator seat is facing forward" 2 "Error" 3 "Not Available" ;
VAL_ 2564882192 SeatBeltSwitch 0 "NOT Buckled" 1 "OK - Seat Belt is buckled" 2 "Error - Switch state cannot be determined" 3 "Not Available" ;
VAL_ 2564882192 ParkBrakeCommand 0 "Park Brake apply not requested" 1 "Park Brake apply requested" 2 "SAE Reserved  " 3 "Don't care/Take no action" ;
VAL_ 2564882192 VehicleLmtngSpdGvrnrDecrementSw 0 "Switch in the off state" 1 "Switch in the on state - decrease" 2 "Error" 3 "Not available" ;
VAL_ 2564882192 VehicleLmtngSpdGvrnrIncrementSw 0 "Switch in the off state" 1 "Switch in the on state - increase" 2 "Error" 3 "Not available" ;
VAL_ 2564882192 VehicleLmtngSpeedGvrnrEnblSwitch 0 "Switch disabled" 1 "Switched enabled" 2 "Error" 3 "Not available" ;
VAL_ 2564882192 AftrtrtmntRegenInhbtSwitch 0 "not active" 1 "active" 2 "error" 3 "not available" ;
VAL_ 2564882192 AftrtrtmntRegenForceSwitch 0 "not active" 1 "active" 2 "error" 3 "not available" ;
VAL_ 2564882192 AutoGearShiftingEnableSwitch 0 "Automated Gear Shifting is disabled" 1 "Automated Gear Shifting is enabled" 2 "error" 3 "Not available" ;
VAL_ 2564882192 EngineAutomaticStartEnableSwitch 0 "Switch in the off state" 1 "Switch in the on state" 2 "Error" 3 "Not available" ;
VAL_ 2564882192 AuxiliaryHeaterModeRequest 0 "De-activate auxiliary heater" 1 "Off due to ADR" 2 "Economy mode" 3 "Normal mode" 4 "Heater pump up-keep" 14 "Reserved" 15 "Don't care" ;
VAL_ 2564882192 RequestEngineZoneHeating 0 "Do not heat engine zone" 1 "Heat engine zone" 2 "Reserved" 3 "Don't care/take no action" ;
VAL_ 2564882192 RequestCabZoneHeating 0 "Do not heat cab engine zone" 1 "Heat cab zone" 2 "Reserved" 3 "Don't care/take no action" ;
VAL_ 2348810251 TSC1OverrideControlModePriority 0 "Highest priority" 1 "High priority" 2 "Medium priority" 3 "Low priority" ;
VAL_ 2348810251 TSC1EngineOverrideCtrlMode 0 "Override disabled" 1 "Speed control" 2 "Torque control" 3 "Speed/torque limit control" ;
VAL_ 2634018819 FFF0_ResultCode 20 "TCU_ID #1 Message Required" 11 "Requested ID not Available" 10 "Requested ID Reprogrammed" 1 "Vehicle Type ID Different" 0 "Vehicle Type ID Identical" ;
VAL_ 2565865761 ASREngineControlActive 0 "ASR engine control passive but installed" 1 "ASR engine control active" 2 "Reserved" 3 "Not available" ;
VAL_ 2565865761 ASRBrakeControlActive 0 "ASR brake control passive but installed" 1 "ASR brake control active" 2 "Reserved" 3 "Not available" ;
VAL_ 2565865761 AntiLockBrakingActive 0 "ABS passive but installed" 1 "ABS active" 2 "Reserved" 3 "Not available" ;
VAL_ 2565865761 EBSBrakeSwitch 0 "Brake pedal is not being pressed" 1 "Brake pedal is being pressed" 2 "Error" 3 "Not available" ;
VAL_ 2565865761 ABSOffRoadSwitch 0 "ABS off-road switch passive" 1 "ABS off-road switch active" 2 "Error" 3 "Not available" ;
VAL_ 2565865761 ASROffRoadSwitch 0 "ASR off-road switch passive" 1 "ASR off-road switch active" 2 "Error" 3 "Not available" ;
VAL_ 2565865761 ASRHillHolderSwitch 0 "ASR 'hill holder' switch passive" 1 "ASR 'hill holder' switch active" 2 "Error" 3 "Not available" ;
VAL_ 2565865761 TractionControlOverrideSwitch 0 "Off" 1 "On" 2 "Error" 3 "Not available or not installed" ;
VAL_ 2565865761 AcceleratorInterlockSwitch 0 "Off" 1 "On" 2 "Error" 3 "Not available" ;
VAL_ 2565865761 EngineDerateSwitch 0 "Off" 1 "On" 2 "Error" 3 "Not available" ;
VAL_ 2565865761 EngineAuxiliaryShutdownSwitch 0 "Off" 1 "On" 2 "Error" 3 "Not available" ;
VAL_ 2565865761 RemoteAcceleratorEnableSwitch 0 "Off" 1 "On" 2 "Error" 3 "Not available" ;
VAL_ 2565865761 ABSFullyOperational 0 "Not Fully Operational" 1 "Fully Operational" 2 "Reserved" 3 "Not available" ;
VAL_ 2565865761 EBSRedWarningSignal 0 "Off" 1 "On" 2 "Reserved" 3 "Take no action" ;
VAL_ 2565865761 ABSEBSAmberWarningSignal 0 "Off" 1 "On" 2 "Reserved" 3 "Take no action" ;
VAL_ 2565865761 ATCASRInformationSignal 0 "Off" 1 "On" 2 "Reserved" 3 "Take no action" ;
VAL_ 2565865761 RailroadModeSwitch 0 "Railroad mode switch passive" 1 "Railroad mode switch active" 2 "Error" 3 "Not available" ;
VAL_ 2565865761 HaltBrakeSwitch 0 "Halt brake switch passive" 1 "Halt brake switch active" 2 "Error" 3 "Not available" ;
VAL_ 2565865761 TrailerABSStatus 0 "Information Available Not Active" 1 "Active" 2 "Reserved" 3 "Information Not Available" ;
VAL_ 2565865761 TractorMntdTrailerABSWarningSig 0 "Off" 1 "On" 2 "Reserved" 3 "Take no action" ;
VAL_ 2231329825 ZFIMP_BucketPosition 255 "Not available" 254 "Error indicator" ;
VAL_ 2231329825 ZFIMP_BoomPosition 255 "Not available" 254 "Error indicator" ;
VAL_ 2566859523 FF1E_DrivelineStatus 1 "Engaged" 0 "Disengaged" ;
VAL_ 2566859523 FF1E_ShiftStatus 1 "in Process" 0 "Not in Process" ;
VAL_ 2566859523 FF1E_OPMode 6 "TCU Idle" 5 "TCU Key Off" 4 "TCU ShutDown" 3 "Transmission ShutDown" 2 "Limp Home" 1 "Substitue Clutch Control" 0 "Normal" ;
VAL_ 2566859523 FF1E_JoystickMode 1 "Active" 0 "Not Active" ;
VAL_ 2566859523 FF1E_CurrentDirection 2 "Reverse / State Gear eng." 1 "Forward / State Gear eng." 0 "Neutral or DirectionClutch Off" ;
VAL_ 2566859523 FF1E_CurrentGear 15 "Limp Home Gear" 6 "Gear_6" 5 "Gear_5" 4 "Gear_4" 3 "Gear_3" 2 "Gear_2" 1 "Gear_1" 0 "Neutral" ;
VAL_ 2566859523 FF1E_DifferentialLock 1 "ON" 0 "OFF" ;
VAL_ 2566859523 FF1E_ShifterDirection 3 "TCU requires N Position" 2 "Position_R" 1 "Position_F" 0 "Position_N" ;
VAL_ 2566859523 FF1E_ShifterRange 15 "Limp Home Gear" 6 "Gear_6" 5 "Gear_5" 4 "Gear_4" 3 "Gear_3" 2 "Gear_2" 1 "Gear_1" 0 "Neutral" ;
VAL_ 2566856195 FF1E_CalibrationStatusWK 3 "Clutch Cal not Active" 2 "Clutch Cal Failed" 1 "Clutch Cal finished successfully" 0 "Clutch Cal running" ;
VAL_ 2566856195 FF1E_CalibrationStatusKR 3 "Clutch Cal not Active" 2 "Clutch Cal Failed" 1 "Clutch Cal finished successfully" 0 "Clutch Cal running" ;
VAL_ 2566856195 FF1E_CalibrationStatusK4 3 "Clutch Cal not Active" 2 "Clutch Cal Failed" 1 "Clutch Cal finished successfully" 0 "Clutch Cal running" ;
VAL_ 2566856195 FF1E_CalibrationStatusKV 3 "Clutch Cal not Active" 2 "Clutch Cal Failed" 1 "Clutch Cal finished successfully" 0 "Clutch Cal running" ;
VAL_ 2566856195 FF1E_CalibrationStatusK3 3 "Clutch Cal not Active" 2 "Clutch Cal Failed" 1 "Clutch Cal finished successfully" 0 "Clutch Cal running" ;
VAL_ 2566856195 FF1E_CalibrationStatusK2 3 "Clutch Cal not Active" 2 "Clutch Cal Failed" 1 "Clutch Cal finished successfully" 0 "Clutch Cal running" ;
VAL_ 2566856195 FF1E_StartCondition 11 "Cal. Already started " 10 "Actual TM Operation not normal" 9 "Park Brake not Applied" 8 "Driver Condition not Fulfilled" 7 "Trans Output Speed Not Zero" 6 "No Neutral Request" 5 "Trans Oil Sump Temp Too Low" 4 "Trans Oil Sump Temp Too High" 3 "Engine Speed Too low" 2 "Engine Speed Too High" 1 "False Command for Clutch Cal." 0 "All condition fulfilled" ;
VAL_ 2566856195 FF1E_CalibrationStatusK1 3 "Clutch Cal not Active" 2 "Clutch Cal Failed" 1 "Clutch Cal finished successfully" 0 "Clutch Cal running" ;
VAL_ 2566856195 FF1E_ClutchCalPhase 3 "clutch cal. not active" 2 "clutch cal. not successful" 1 "clutch cal. successful" 0 "clutch calibration running" ;
VAL_ 2566856195 FF1E_CalibrationStatus 3 "cal. not yet started" 2 "cal. finished not successful" 1 "cal. finished successful" 0 "calibration running" ;
VAL_ 2566856195 FF1E_BreakCondition 16 "internal calibration timeout" 15 "clutch slipping time too long" 14 "calibration not active" 13 "no clutch selected" 12 "no value found" 11 "time determin for drain failed" 10 "pressure too high" 9 "park brake not applied" 8 "trm op. mode not NORMAL" 7 "trm output speed not zero" 6 "no neutral request" 5 "trm oil sump temp. too low" 4 "trm oil sump temp. too high" 3 "eng. speed too low" 2 "eng. speed too high" 1 "aborted by user" 0 "All conditions fulfilled" ;
